VERSION "created by canmatrix"

NS_ :

BS_:

BU_:

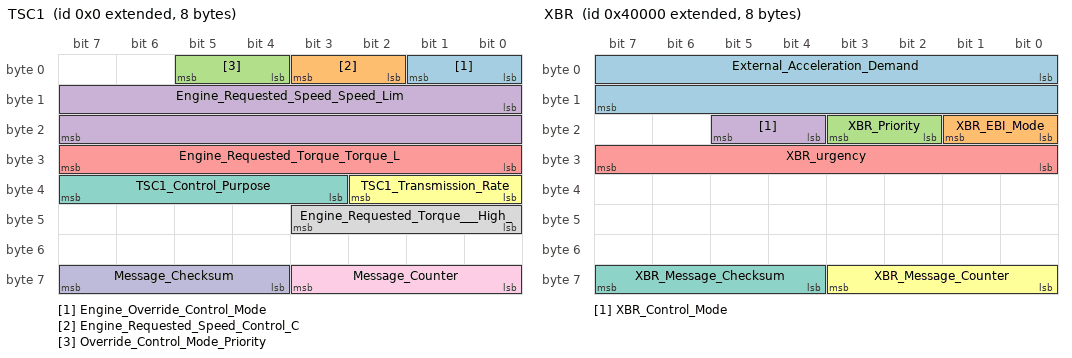
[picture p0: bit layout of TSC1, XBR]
BO_ 2147483648 TSC1: 8 Vector__XXX
 SG_ Engine_Override_Control_Mode : 0|2@1+ (1,0) [0|3] "" Vector__XXX
 SG_ Engine_Requested_Speed_Control_C : 2|2@1+ (1,0) [0|3] "" Vector__XXX
 SG_ Override_Control_Mode_Priority : 4|2@1+ (1,0) [0|3] "" Vector__XXX
 SG_ Engine_Requested_Speed_Speed_Lim : 8|16@1+ (1,0) [0|65535] "" Vector__XXX
 SG_ Engine_Requested_Torque_Torque_L : 24|8@1+ (1,0) [0|255] "" Vector__XXX
 SG_ TSC1_Transmission_Rate : 32|3@1+ (1,0) [0|7] "" Vector__XXX
 SG_ TSC1_Control_Purpose : 35|5@1+ (1,0) [0|31] "" Vector__XXX
 SG_ Engine_Requested_Torque___High_ : 40|4@1+ (1,0) [0|15] "" Vector__XXX
 SG_ Message_Counter : 56|4@1+ (1,0) [0|15] "" Vector__XXX
 SG_ Message_Checksum : 60|4@1+ (1,0) [0|15] "" Vector__XXX

BO_ 2147549184 TC1: 8 Vector__XXX
 SG_ Transmission_Gear_Shift_Inhibit_ : 0|2@1+ (1,0) [0|3] "" Vector__XXX
 SG_ Transmission_Torque_Converter_Lo : 2|2@1+ (1,0) [0|3] "" Vector__XXX
 SG_ Disengage_Driveline_Request : 4|2@1+ (1,0) [0|3] "" Vector__XXX
 SG_ Transmission_Reverse_Gear_Shift_ : 6|2@1+ (1,0) [0|3] "" Vector__XXX
 SG_ Requested_Percent_Clutch_Slip : 8|8@1+ (1,0) [0|255] "" Vector__XXX
 SG_ Transmission_Requested_Gear : 16|8@1+ (1,0) [0|255] "" Vector__XXX
 SG_ Disengage_Differential_Lock_Requ0 : 24|2@1+ (1,0) [0|3] "" Vector__XXX
 SG_ Disengage_Differential_Lock_Requ1 : 26|2@1+ (1,0) [0|3] "" Vector__XXX
 SG_ Disengage_Differential_Lock_Requ2 : 28|2@1+ (1,0) [0|3] "" Vector__XXX
 SG_ Disengage_Differential_Lock_Requ3 : 30|2@1+ (1,0) [0|3] "" Vector__XXX
 SG_ Disengage_Differential_Lock_Requ4 : 32|2@1+ (1,0) [0|3] "" Vector__XXX
 SG_ Disengage_Differential_Lock_Requ5 : 34|2@1+ (1,0) [0|3] "" Vector__XXX
 SG_ Disengage_Differential_Lock_Requ6 : 36|2@1+ (1,0) [0|3] "" Vector__XXX
 SG_ Transmission_Mode_1 : 40|2@1+ (1,0) [0|3] "" Vector__XXX
 SG_ Transmission_Mode_2 : 42|2@1+ (1,0) [0|3] "" Vector__XXX
 SG_ Transmission_Mode_3 : 44|2@1+ (1,0) [0|3] "" Vector__XXX
 SG_ Transmission_Mode_4 : 46|2@1+ (1,0) [0|3] "" Vector__XXX
 SG_ Transmission_Requested_Launch_Ge : 50|4@1+ (1,0) [0|15] "" Vector__XXX
 SG_ Transmission_Shift_Selector_Disp : 54|2@1+ (1,0) [0|3] "" Vector__XXX
 SG_ Transmission_Mode_5 : 56|2@1+ (1,0) [0|3] "" Vector__XXX
 SG_ Transmission_Mode_6 : 58|2@1+ (1,0) [0|3] "" Vector__XXX
 SG_ Transmission_Mode_7 : 60|2@1+ (1,0) [0|3] "" Vector__XXX
 SG_ Transmission_Mode_8 : 62|2@1+ (1,0) [0|3] "" Vector__XXX

BO_ 2147745792 XBR: 8 Vector__XXX
 SG_ External_Acceleration_Demand : 0|16@1+ (1,0) [0|65535] "" Vector__XXX
 SG_ XBR_EBI_Mode : 16|2@1+ (1,0) [0|3] "" Vector__XXX
 SG_ XBR_Priority : 18|2@1+ (1,0) [0|3] "" Vector__XXX
 SG_ XBR_Control_Mode : 20|2@1+ (1,0) [0|3] "" Vector__XXX
 SG_ XBR_urgency : 24|8@1+ (1,0) [0|255] "" Vector__XXX
 SG_ XBR_Message_Counter : 56|4@1+ (1,0) [0|15] "" Vector__XXX
 SG_ XBR_Message_Checksum : 60|4@1+ (1,0) [0|15] "" Vector__XXX

BO_ 2147942400 GPV4: 8 Vector__XXX
 SG_ Valve_Load_Sense_Pressure : 0|16@1+ (1,0) [0|65535] "" Vector__XXX
 SG_ Valve_Pilot_Pressure : 16|8@1+ (1,0) [0|255] "" Vector__XXX
 SG_ Valve_Assembly_Load_sense_Pressu : 24|16@1+ (1,0) [0|65535] "" Vector__XXX
 SG_ Valve_Assembly_Supply_Pressure : 40|16@1+ (1,0) [0|65535] "" Vector__XXX

BO_ 2148007936 AUXIO5: 8 Vector__XXX
 SG_ Auxiliary_I_O_Channel__6 : 0|16@1+ (1,0) [0|65535] "" Vector__XXX
 SG_ Auxiliary_I_O_Channel__5 : 16|16@1+ (1,0) [0|65535] "" Vector__XXX
 SG_ Auxiliary_I_O_Channel__4 : 32|16@1+ (1,0) [0|65535] "" Vector__XXX
 SG_ Auxiliary_I_O_Channel__3 : 48|16@1+ (1,0) [0|65535] "" Vector__XXX

BO_ 2157641728 PMI: 8 Vector__XXX
 SG_ Data_Dictionary_Manufacturer_Cod : 0|11@1+ (1,0) [0|2047] "" Vector__XXX
 SG_ Data_Dictionary_Method : 11|21@1+ (1,0) [0|2097151] "" Vector__XXX

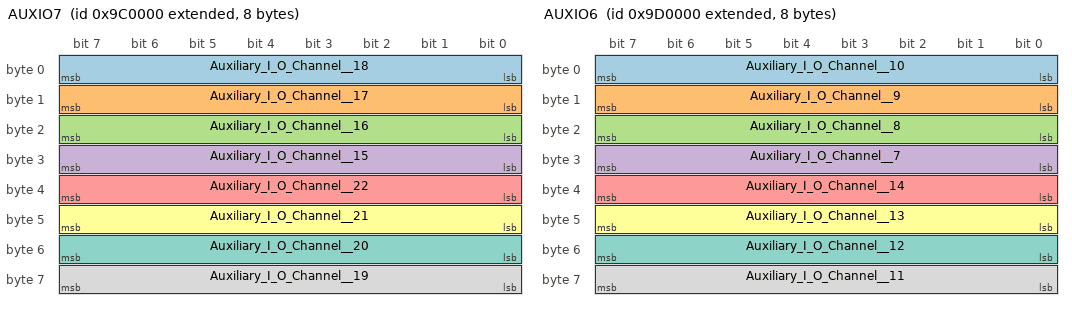
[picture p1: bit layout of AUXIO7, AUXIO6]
BO_ 2157707264 AUXIO7: 8 Vector__XXX
 SG_ Auxiliary_I_O_Channel__18 : 0|8@1+ (1,0) [0|255] "" Vector__XXX
 SG_ Auxiliary_I_O_Channel__17 : 8|8@1+ (1,0) [0|255] "" Vector__XXX
 SG_ Auxiliary_I_O_Channel__16 : 16|8@1+ (1,0) [0|255] "" Vector__XXX
 SG_ Auxiliary_I_O_Channel__15 : 24|8@1+ (1,0) [0|255] "" Vector__XXX
 SG_ Auxiliary_I_O_Channel__22 : 32|8@1+ (1,0) [0|255] "" Vector__XXX
 SG_ Auxiliary_I_O_Channel__21 : 40|8@1+ (1,0) [0|255] "" Vector__XXX
 SG_ Auxiliary_I_O_Channel__20 : 48|8@1+ (1,0) [0|255] "" Vector__XXX
 SG_ Auxiliary_I_O_Channel__19 : 56|8@1+ (1,0) [0|255] "" Vector__XXX

BO_ 2157772800 AUXIO6: 8 Vector__XXX
 SG_ Auxiliary_I_O_Channel__10 : 0|8@1+ (1,0) [0|255] "" Vector__XXX
 SG_ Auxiliary_I_O_Channel__9 : 8|8@1+ (1,0) [0|255] "" Vector__XXX
 SG_ Auxiliary_I_O_Channel__8 : 16|8@1+ (1,0) [0|255] "" Vector__XXX
 SG_ Auxiliary_I_O_Channel__7 : 24|8@1+ (1,0) [0|255] "" Vector__XXX
 SG_ Auxiliary_I_O_Channel__14 : 32|8@1+ (1,0) [0|255] "" Vector__XXX
 SG_ Auxiliary_I_O_Channel__13 : 40|8@1+ (1,0) [0|255] "" Vector__XXX
 SG_ Auxiliary_I_O_Channel__12 : 48|8@1+ (1,0) [0|255] "" Vector__XXX
 SG_ Auxiliary_I_O_Channel__11 : 56|8@1+ (1,0) [0|255] "" Vector__XXX

BO_ 2158297088 AUXIO4: 8 Vector__XXX
 SG_ Auxiliary_I_O__84 : 0|2@1+ (1,0) [0|3] "" Vector__XXX
 SG_ Auxiliary_I_O__83 : 2|2@1+ (1,0) [0|3] "" Vector__XXX
 SG_ Auxiliary_I_O__82 : 4|2@1+ (1,0) [0|3] "" Vector__XXX
 SG_ Auxiliary_I_O__81 : 6|2@1+ (1,0) [0|3] "" Vector__XXX
 SG_ Auxiliary_I_O__88 : 8|2@1+ (1,0) [0|3] "" Vector__XXX
 SG_ Auxiliary_I_O__87 : 10|2@1+ (1,0) [0|3] "" Vector__XXX
 SG_ Auxiliary_I_O__86 : 12|2@1+ (1,0) [0|3] "" Vector__XXX
 SG_ Auxiliary_I_O__85 : 14|2@1+ (1,0) [0|3] "" Vector__XXX
 SG_ Auxiliary_I_O__92 : 16|2@1+ (1,0) [0|3] "" Vector__XXX
 SG_ Auxiliary_I_O__91 : 18|2@1+ (1,0) [0|3] "" Vector__XXX
 SG_ Auxiliary_I_O__90 : 20|2@1+ (1,0) [0|3] "" Vector__XXX
 SG_ Auxiliary_I_O__89 : 22|2@1+ (1,0) [0|3] "" Vector__XXX
 SG_ Auxiliary_I_O__96 : 24|2@1+ (1,0) [0|3] "" Vector__XXX
 SG_ Auxiliary_I_O__95 : 26|2@1+ (1,0) [0|3] "" Vector__XXX
 SG_ Auxiliary_I_O__94 : 28|2@1+ (1,0) [0|3] "" Vector__XXX
 SG_ Auxiliary_I_O__93 : 30|2@1+ (1,0) [0|3] "" Vector__XXX
 SG_ Auxiliary_I_O__100 : 32|2@1+ (1,0) [0|3] "" Vector__XXX
 SG_ Auxiliary_I_O__99 : 34|2@1+ (1,0) [0|3] "" Vector__XXX
 SG_ Auxiliary_I_O__98 : 36|2@1+ (1,0) [0|3] "" Vector__XXX
 SG_ Auxiliary_I_O__97 : 38|2@1+ (1,0) [0|3] "" Vector__XXX
 SG_ Auxiliary_I_O__104 : 40|2@1+ (1,0) [0|3] "" Vector__XXX
 SG_ Auxiliary_I_O__103 : 42|2@1+ (1,0) [0|3] "" Vector__XXX
 SG_ Auxiliary_I_O__102 : 44|2@1+ (1,0) [0|3] "" Vector__XXX
 SG_ Auxiliary_I_O__101 : 46|2@1+ (1,0) [0|3] "" Vector__XXX
 SG_ Auxiliary_I_O__108 : 48|2@1+ (1,0) [0|3] "" Vector__XXX
 SG_ Auxiliary_I_O__107 : 50|2@1+ (1,0) [0|3] "" Vector__XXX
 SG_ Auxiliary_I_O__106 : 52|2@1+ (1,0) [0|3] "" Vector__XXX
 SG_ Auxiliary_I_O__105 : 54|2@1+ (1,0) [0|3] "" Vector__XXX
 SG_ Auxiliary_I_O__112 : 56|2@1+ (1,0) [0|3] "" Vector__XXX
 SG_ Auxiliary_I_O__111 : 58|2@1+ (1,0) [0|3] "" Vector__XXX
 SG_ Auxiliary_I_O__110 : 60|2@1+ (1,0) [0|3] "" Vector__XXX
 SG_ Auxiliary_I_O__109 : 62|2@1+ (1,0) [0|3] "" Vector__XXX

BO_ 2158362624 AUXIO3: 8 Vector__XXX
 SG_ Auxiliary_I_O__52 : 0|2@1+ (1,0) [0|3] "" Vector__XXX
 SG_ Auxiliary_I_O__51 : 2|2@1+ (1,0) [0|3] "" Vector__XXX
 SG_ Auxiliary_I_O__50 : 4|2@1+ (1,0) [0|3] "" Vector__XXX
 SG_ Auxiliary_I_O__49 : 6|2@1+ (1,0) [0|3] "" Vector__XXX
 SG_ Auxiliary_I_O__56 : 8|2@1+ (1,0) [0|3] "" Vector__XXX
 SG_ Auxiliary_I_O__55 : 10|2@1+ (1,0) [0|3] "" Vector__XXX
 SG_ Auxiliary_I_O__54 : 12|2@1+ (1,0) [0|3] "" Vector__XXX
 SG_ Auxiliary_I_O__53 : 14|2@1+ (1,0) [0|3] "" Vector__XXX
 SG_ Auxiliary_I_O__60 : 16|2@1+ (1,0) [0|3] "" Vector__XXX
 SG_ Auxiliary_I_O__59 : 18|2@1+ (1,0) [0|3] "" Vector__XXX
 SG_ Auxiliary_I_O__58 : 20|2@1+ (1,0) [0|3] "" Vector__XXX
 SG_ Auxiliary_I_O__57 : 22|2@1+ (1,0) [0|3] "" Vector__XXX
 SG_ Auxiliary_I_O__64 : 24|2@1+ (1,0) [0|3] "" Vector__XXX
 SG_ Auxiliary_I_O__63 : 26|2@1+ (1,0) [0|3] "" Vector__XXX
 SG_ Auxiliary_I_O__62 : 28|2@1+ (1,0) [0|3] "" Vector__XXX
 SG_ Auxiliary_I_O__61 : 30|2@1+ (1,0) [0|3] "" Vector__XXX
 SG_ Auxiliary_I_O__68 : 32|2@1+ (1,0) [0|3] "" Vector__XXX
 SG_ Auxiliary_I_O__67 : 34|2@1+ (1,0) [0|3] "" Vector__XXX
 SG_ Auxiliary_I_O__66 : 36|2@1+ (1,0) [0|3] "" Vector__XXX
 SG_ Auxiliary_I_O__65 : 38|2@1+ (1,0) [0|3] "" Vector__XXX
 SG_ Auxiliary_I_O__72 : 40|2@1+ (1,0) [0|3] "" Vector__XXX
 SG_ Auxiliary_I_O__71 : 42|2@1+ (1,0) [0|3] "" Vector__XXX
 SG_ Auxiliary_I_O__70 : 44|2@1+ (1,0) [0|3] "" Vector__XXX
 SG_ Auxiliary_I_O__69 : 46|2@1+ (1,0) [0|3] "" Vector__XXX
 SG_ Auxiliary_I_O__76 : 48|2@1+ (1,0) [0|3] "" Vector__XXX
 SG_ Auxiliary_I_O__75 : 50|2@1+ (1,0) [0|3] "" Vector__XXX
 SG_ Auxiliary_I_O__74 : 52|2@1+ (1,0) [0|3] "" Vector__XXX
 SG_ Auxiliary_I_O__73 : 54|2@1+ (1,0) [0|3] "" Vector__XXX
 SG_ Auxiliary_I_O__80 : 56|2@1+ (1,0) [0|3] "" Vector__XXX
 SG_ Auxiliary_I_O__79 : 58|2@1+ (1,0) [0|3] "" Vector__XXX
 SG_ Auxiliary_I_O__78 : 60|2@1+ (1,0) [0|3] "" Vector__XXX
 SG_ Auxiliary_I_O__77 : 62|2@1+ (1,0) [0|3] "" Vector__XXX

BO_ 2158428160 AUXIO2: 8 Vector__XXX
 SG_ Auxiliary_I_O__20 : 0|2@1+ (1,0) [0|3] "" Vector__XXX
 SG_ Auxiliary_I_O__19 : 2|2@1+ (1,0) [0|3] "" Vector__XXX
 SG_ Auxiliary_I_O__18 : 4|2@1+ (1,0) [0|3] "" Vector__XXX
 SG_ Auxiliary_I_O__17 : 6|2@1+ (1,0) [0|3] "" Vector__XXX
 SG_ Auxiliary_I_O__24 : 8|2@1+ (1,0) [0|3] "" Vector__XXX
 SG_ Auxiliary_I_O__23 : 10|2@1+ (1,0) [0|3] "" Vector__XXX
 SG_ Auxiliary_I_O__22 : 12|2@1+ (1,0) [0|3] "" Vector__XXX
 SG_ Auxiliary_I_O__21 : 14|2@1+ (1,0) [0|3] "" Vector__XXX
 SG_ Auxiliary_I_O__28 : 16|2@1+ (1,0) [0|3] "" Vector__XXX
 SG_ Auxiliary_I_O__27 : 18|2@1+ (1,0) [0|3] "" Vector__XXX
 SG_ Auxiliary_I_O__26 : 20|2@1+ (1,0) [0|3] "" Vector__XXX
 SG_ Auxiliary_I_O__25 : 22|2@1+ (1,0) [0|3] "" Vector__XXX
 SG_ Auxiliary_I_O__32 : 24|2@1+ (1,0) [0|3] "" Vector__XXX
 SG_ Auxiliary_I_O__31 : 26|2@1+ (1,0) [0|3] "" Vector__XXX
 SG_ Auxiliary_I_O__30 : 28|2@1+ (1,0) [0|3] "" Vector__XXX
 SG_ Auxiliary_I_O__29 : 30|2@1+ (1,0) [0|3] "" Vector__XXX
 SG_ Auxiliary_I_O__36 : 32|2@1+ (1,0) [0|3] "" Vector__XXX
 SG_ Auxiliary_I_O__35 : 34|2@1+ (1,0) [0|3] "" Vector__XXX
 SG_ Auxiliary_I_O__34 : 36|2@1+ (1,0) [0|3] "" Vector__XXX
 SG_ Auxiliary_I_O__33 : 38|2@1+ (1,0) [0|3] "" Vector__XXX
 SG_ Auxiliary_I_O__40 : 40|2@1+ (1,0) [0|3] "" Vector__XXX
 SG_ Auxiliary_I_O__39 : 42|2@1+ (1,0) [0|3] "" Vector__XXX
 SG_ Auxiliary_I_O__38 : 44|2@1+ (1,0) [0|3] "" Vector__XXX
 SG_ Auxiliary_I_O__37 : 46|2@1+ (1,0) [0|3] "" Vector__XXX
 SG_ Auxiliary_I_O__44 : 48|2@1+ (1,0) [0|3] "" Vector__XXX
 SG_ Auxiliary_I_O__43 : 50|2@1+ (1,0) [0|3] "" Vector__XXX
 SG_ Auxiliary_I_O__42 : 52|2@1+ (1,0) [0|3] "" Vector__XXX
 SG_ Auxiliary_I_O__41 : 54|2@1+ (1,0) [0|3] "" Vector__XXX
 SG_ Auxiliary_I_O__48 : 56|2@1+ (1,0) [0|3] "" Vector__XXX
 SG_ Auxiliary_I_O__47 : 58|2@1+ (1,0) [0|3] "" Vector__XXX
 SG_ Auxiliary_I_O__46 : 60|2@1+ (1,0) [0|3] "" Vector__XXX
 SG_ Auxiliary_I_O__45 : 62|2@1+ (1,0) [0|3] "" Vector__XXX

BO_ 2158493696 DISP1: 8 Vector__XXX
 SG_ Text_Display_Instructions : 0|4@1+ (1,0) [0|15] "" Vector__XXX
 SG_ Text_Display_Index : 16|8@1+ (1,0) [0|255] "" Vector__XXX
 SG_ Text_Display_Character : 24|1600@1+ (1,0) [0|4.446241647709404462001681407E+481] "" Vector__XXX

BO_ 2158559232 FLIC: 8 Vector__XXX
 SG_ Lane_Departure_Warning_Enable_Co : 0|2@1+ (1,0) [0|3] "" Vector__XXX

BO_ 2158886912 TPRS: 8 Vector__XXX
 SG_ Tire_Location : 0|8@1+ (1,0) [0|255] "" Vector__XXX
 SG_ Reference_Tire_Pressure_Setting : 8|8@1+ (1,0) [0|255] "" Vector__XXX

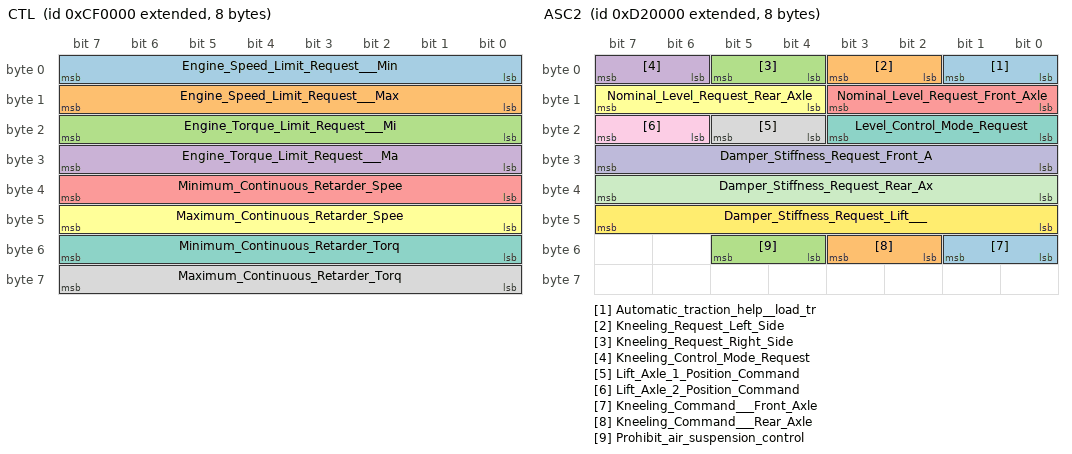
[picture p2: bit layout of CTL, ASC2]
BO_ 2161049600 CTL: 8 Vector__XXX
 SG_ Engine_Speed_Limit_Request___Min : 0|8@1+ (1,0) [0|255] "" Vector__XXX
 SG_ Engine_Speed_Limit_Request___Max : 8|8@1+ (1,0) [0|255] "" Vector__XXX
 SG_ Engine_Torque_Limit_Request___Mi : 16|8@1+ (1,0) [0|255] "" Vector__XXX
 SG_ Engine_Torque_Limit_Request___Ma : 24|8@1+ (1,0) [0|255] "" Vector__XXX
 SG_ Minimum_Continuous_Retarder_Spee : 32|8@1+ (1,0) [0|255] "" Vector__XXX
 SG_ Maximum_Continuous_Retarder_Spee : 40|8@1+ (1,0) [0|255] "" Vector__XXX
 SG_ Minimum_Continuous_Retarder_Torq : 48|8@1+ (1,0) [0|255] "" Vector__XXX
 SG_ Maximum_Continuous_Retarder_Torq : 56|8@1+ (1,0) [0|255] "" Vector__XXX

BO_ 2161115136 CL: 8 Vector__XXX
 SG_ Illumination_Brightness_Percent : 0|8@1+ (1,0) [0|255] "" Vector__XXX

BO_ 2161180672 ASC6: 8 Vector__XXX
 SG_ Level_Preset_Front_Axle_Left : 0|16@1+ (1,0) [0|65535] "" Vector__XXX
 SG_ Level_Preset_Front_Axle_Right : 16|16@1+ (1,0) [0|65535] "" Vector__XXX
 SG_ Level_Preset_Rear_Axle_Left : 32|16@1+ (1,0) [0|65535] "" Vector__XXX
 SG_ Level_Preset_Rear_Axle_Right : 48|16@1+ (1,0) [0|65535] "" Vector__XXX

BO_ 2161246208 ASC2: 8 Vector__XXX
 SG_ Automatic_traction_help__load_tr : 0|2@1+ (1,0) [0|3] "" Vector__XXX
 SG_ Kneeling_Request_Left_Side : 2|2@1+ (1,0) [0|3] "" Vector__XXX
 SG_ Kneeling_Request_Right_Side : 4|2@1+ (1,0) [0|3] "" Vector__XXX
 SG_ Kneeling_Control_Mode_Request : 6|2@1+ (1,0) [0|3] "" Vector__XXX
 SG_ Nominal_Level_Request_Front_Axle : 8|4@1+ (1,0) [0|15] "" Vector__XXX
 SG_ Nominal_Level_Request_Rear_Axle : 12|4@1+ (1,0) [0|15] "" Vector__XXX
 SG_ Level_Control_Mode_Request : 16|4@1+ (1,0) [0|15] "" Vector__XXX
 SG_ Lift_Axle_1_Position_Command : 20|2@1+ (1,0) [0|3] "" Vector__XXX
 SG_ Lift_Axle_2_Position_Command : 22|2@1+ (1,0) [0|3] "" Vector__XXX
 SG_ Damper_Stiffness_Request_Front_A : 24|8@1+ (1,0) [0|255] "" Vector__XXX
 SG_ Damper_Stiffness_Request_Rear_Ax : 32|8@1+ (1,0) [0|255] "" Vector__XXX
 SG_ Damper_Stiffness_Request_Lift___ : 40|8@1+ (1,0) [0|255] "" Vector__XXX
 SG_ Kneeling_Command___Front_Axle : 48|2@1+ (1,0) [0|3] "" Vector__XXX
 SG_ Kneeling_Command___Rear_Axle : 50|2@1+ (1,0) [0|3] "" Vector__XXX
 SG_ Prohibit_air_suspension_control : 52|2@1+ (1,0) [0|3] "" Vector__XXX

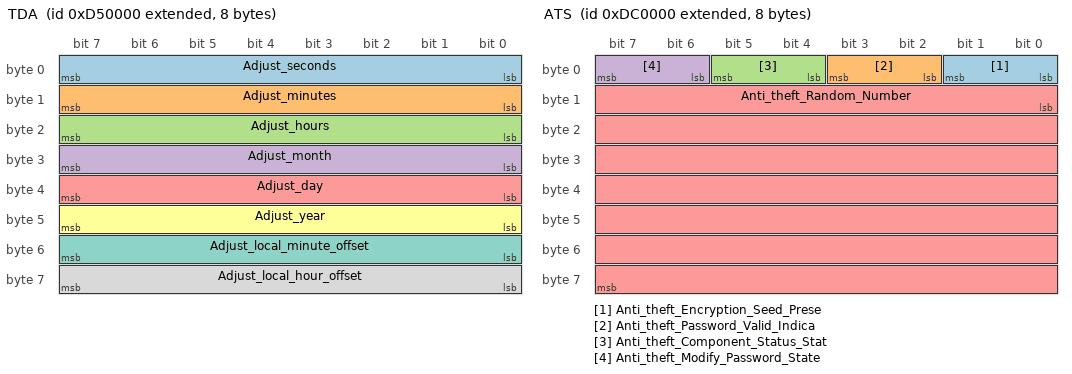
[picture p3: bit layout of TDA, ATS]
BO_ 2161442816 TDA: 8 Vector__XXX
 SG_ Adjust_seconds : 0|8@1+ (1,0) [0|255] "" Vector__XXX
 SG_ Adjust_minutes : 8|8@1+ (1,0) [0|255] "" Vector__XXX
 SG_ Adjust_hours : 16|8@1+ (1,0) [0|255] "" Vector__XXX
 SG_ Adjust_month : 24|8@1+ (1,0) [0|255] "" Vector__XXX
 SG_ Adjust_day : 32|8@1+ (1,0) [0|255] "" Vector__XXX
 SG_ Adjust_year : 40|8@1+ (1,0) [0|255] "" Vector__XXX
 SG_ Adjust_local_minute_offset : 48|8@1+ (1,0) [0|255] "" Vector__XXX
 SG_ Adjust_local_hour_offset : 56|8@1+ (1,0) [0|255] "" Vector__XXX

BO_ 2161901568 ATS: 8 Vector__XXX
 SG_ Anti_theft_Encryption_Seed_Prese : 0|2@1+ (1,0) [0|3] "" Vector__XXX
 SG_ Anti_theft_Password_Valid_Indica : 2|2@1+ (1,0) [0|3] "" Vector__XXX
 SG_ Anti_theft_Component_Status_Stat : 4|2@1+ (1,0) [0|3] "" Vector__XXX
 SG_ Anti_theft_Modify_Password_State : 6|2@1+ (1,0) [0|3] "" Vector__XXX
 SG_ Anti_theft_Random_Number : 8|56@1+ (1,0) [0|72057594037927935] "" Vector__XXX

BO_ 2161967104 ATR: 8 Vector__XXX
 SG_ Anti_theft_Encryption_Indicator_ : 1|2@1+ (1,0) [0|3] "" Vector__XXX
 SG_ Anti_theft_Desired_Exit_Mode_Sta : 3|2@1+ (1,0) [0|3] "" Vector__XXX
 SG_ Anti_theft_Command_States : 5|3@1+ (1,0) [0|7] "" Vector__XXX
 SG_ Anti_theft_Password_Representati : 8|56@1+ (1,0) [0|72057594037927935] "" Vector__XXX

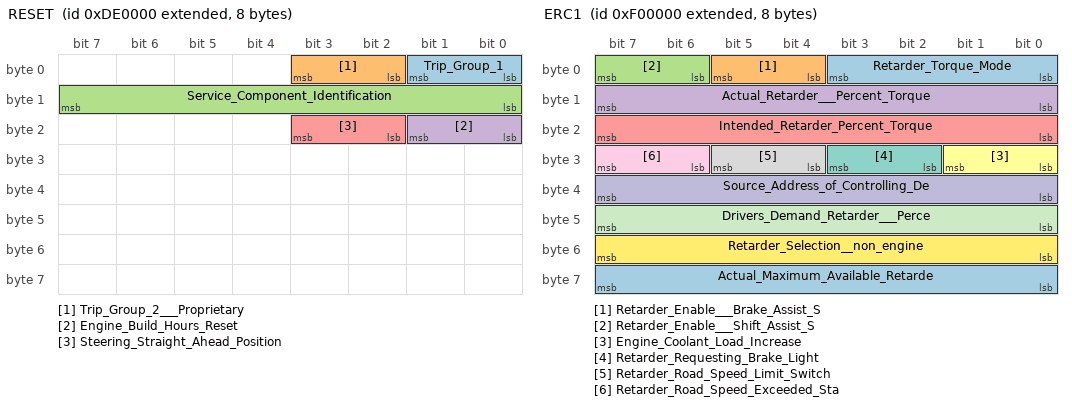
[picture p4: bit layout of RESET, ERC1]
BO_ 2162032640 RESET: 8 Vector__XXX
 SG_ Trip_Group_1 : 0|2@1+ (1,0) [0|3] "" Vector__XXX
 SG_ Trip_Group_2___Proprietary : 2|2@1+ (1,0) [0|3] "" Vector__XXX
 SG_ Service_Component_Identification : 8|8@1+ (1,0) [0|255] "" Vector__XXX
 SG_ Engine_Build_Hours_Reset : 16|2@1+ (1,0) [0|3] "" Vector__XXX
 SG_ Steering_Straight_Ahead_Position : 18|2@1+ (1,0) [0|3] "" Vector__XXX

BO_ 2162163712 CM1: 8 Vector__XXX
 SG_ Requested_Percent_Fan_Speed : 0|8@1+ (1,0) [0|255] "" Vector__XXX
 SG_ Cab_Interior_Temperature_Command : 8|16@1+ (1,0) [0|65535] "" Vector__XXX
 SG_ Auxiliary_Heater_Coolant_Pump_Re : 24|2@1+ (1,0) [0|3] "" Vector__XXX
 SG_ Battery_Main_Switch_Hold_Request : 26|2@1+ (1,0) [0|3] "" Vector__XXX
 SG_ Operator_Seat_Direction_Switch : 28|2@1+ (1,0) [0|3] "" Vector__XXX
 SG_ Seat_Belt_Switch : 30|2@1+ (1,0) [0|3] "" Vector__XXX
 SG_ Vehicle_Limiting_Speed_Governor_0 : 34|2@1+ (1,0) [0|3] "" Vector__XXX
 SG_ Vehicle_Limiting_Speed_Governor_1 : 36|2@1+ (1,0) [0|3] "" Vector__XXX
 SG_ Vehicle_Limiting_Speed_Governor_2 : 38|2@1+ (1,0) [0|3] "" Vector__XXX
 SG_ Diesel_Particulate_Filter_Regene0 : 40|2@1+ (1,0) [0|3] "" Vector__XXX
 SG_ Diesel_Particulate_Filter_Regene1 : 42|2@1+ (1,0) [0|3] "" Vector__XXX
 SG_ Automatic_Gear_Shifting_Enable_S : 44|2@1+ (1,0) [0|3] "" Vector__XXX
 SG_ Engine_Automatic_Start_Enable_Sw : 46|2@1+ (1,0) [0|3] "" Vector__XXX
 SG_ Auxiliary_Heater_Mode_Request : 48|4@1+ (1,0) [0|15] "" Vector__XXX
 SG_ Request_Engine_Zone_Heating : 52|2@1+ (1,0) [0|3] "" Vector__XXX
 SG_ Request_Cab_Zone_Heating : 54|2@1+ (1,0) [0|3] "" Vector__XXX
 SG_ Selected_Maximum_Vehicle_Speed_L : 56|8@1+ (1,0) [0|255] "" Vector__XXX

BO_ 2163212288 ERC1: 8 Vector__XXX
 SG_ Retarder_Torque_Mode : 0|4@1+ (1,0) [0|15] "" Vector__XXX
 SG_ Retarder_Enable___Brake_Assist_S : 4|2@1+ (1,0) [0|3] "" Vector__XXX
 SG_ Retarder_Enable___Shift_Assist_S : 6|2@1+ (1,0) [0|3] "" Vector__XXX
 SG_ Actual_Retarder___Percent_Torque : 8|8@1+ (1,0) [0|255] "" Vector__XXX
 SG_ Intended_Retarder_Percent_Torque : 16|8@1+ (1,0) [0|255] "" Vector__XXX
 SG_ Engine_Coolant_Load_Increase : 24|2@1+ (1,0) [0|3] "" Vector__XXX
 SG_ Retarder_Requesting_Brake_Light : 26|2@1+ (1,0) [0|3] "" Vector__XXX
 SG_ Retarder_Road_Speed_Limit_Switch : 28|2@1+ (1,0) [0|3] "" Vector__XXX
 SG_ Retarder_Road_Speed_Exceeded_Sta : 30|2@1+ (1,0) [0|3] "" Vector__XXX
 SG_ Source_Address_of_Controlling_De : 32|8@1+ (1,0) [0|255] "" Vector__XXX
 SG_ Drivers_Demand_Retarder___Perce : 40|8@1+ (1,0) [0|255] "" Vector__XXX
 SG_ Retarder_Selection__non_engine : 48|8@1+ (1,0) [0|255] "" Vector__XXX
 SG_ Actual_Maximum_Available_Retarde : 56|8@1+ (1,0) [0|255] "" Vector__XXX

BO_ 2163212544 EBC1: 8 Vector__XXX
 SG_ ASR_Engine_Control_Active : 0|2@1+ (1,0) [0|3] "" Vector__XXX
 SG_ ASR_Brake_Control_Active : 2|2@1+ (1,0) [0|3] "" Vector__XXX
 SG_ Anti_Lock_Braking__ABS__Active : 4|2@1+ (1,0) [0|3] "" Vector__XXX
 SG_ EBS_Brake_Switch : 6|2@1+ (1,0) [0|3] "" Vector__XXX
 SG_ Brake_Pedal_Position : 8|8@1+ (1,0) [0|255] "" Vector__XXX
 SG_ ABS_Off_road_Switch : 16|2@1+ (1,0) [0|3] "" Vector__XXX
 SG_ ASR_Off_road_Switch : 18|2@1+ (1,0) [0|3] "" Vector__XXX
 SG_ ASR__Hill_Holder__Switch : 20|2@1+ (1,0) [0|3] "" Vector__XXX
 SG_ Traction_Control_Override_Switch : 22|2@1+ (1,0) [0|3] "" Vector__XXX
 SG_ Accelerator_Interlock_Switch : 24|2@1+ (1,0) [0|3] "" Vector__XXX
 SG_ Engine_Derate_Switch : 26|2@1+ (1,0) [0|3] "" Vector__XXX
 SG_ Engine_Auxiliary_Shutdown_Switch : 28|2@1+ (1,0) [0|3] "" Vector__XXX
 SG_ Remote_Accelerator_Enable_Switch : 30|2@1+ (1,0) [0|3] "" Vector__XXX
 SG_ Engine_Retarder_Selection : 32|8@1+ (1,0) [0|255] "" Vector__XXX
 SG_ ABS_Fully_Operational : 40|2@1+ (1,0) [0|3] "" Vector__XXX
 SG_ EBS_Red_Warning_Signal : 42|2@1+ (1,0) [0|3] "" Vector__XXX
 SG_ ABS_EBS_Amber_Warning_Signal__Po : 44|2@1+ (1,0) [0|3] "" Vector__XXX
 SG_ ATC_ASR_Information_Signal : 46|2@1+ (1,0) [0|3] "" Vector__XXX
 SG_ Source_Address_of_Controlling_De : 48|8@1+ (1,0) [0|255] "" Vector__XXX
 SG_ Halt_brake_switch : 58|2@1+ (1,0) [0|3] "" Vector__XXX
 SG_ Trailer_ABS_Status : 60|2@1+ (1,0) [0|3] "" Vector__XXX
 SG_ Tractor_Mounted_Trailer_ABS_Warn : 62|2@1+ (1,0) [0|3] "" Vector__XXX

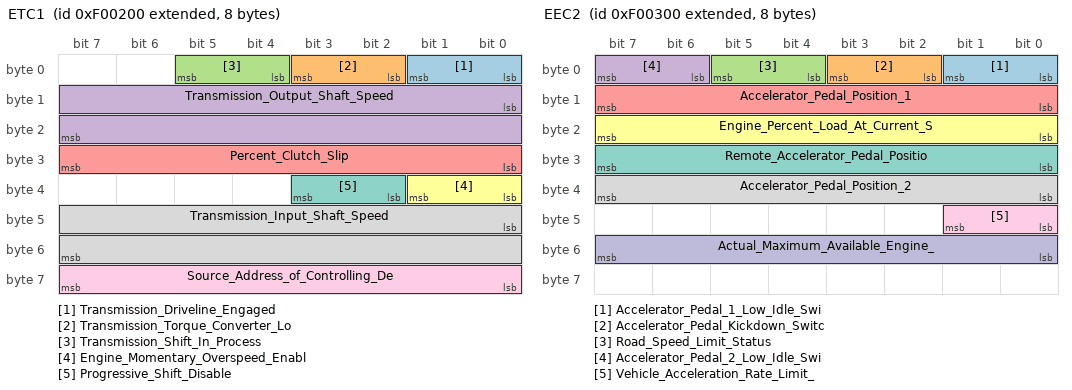
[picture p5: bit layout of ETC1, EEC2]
BO_ 2163212800 ETC1: 8 Vector__XXX
 SG_ Transmission_Driveline_Engaged : 0|2@1+ (1,0) [0|3] "" Vector__XXX
 SG_ Transmission_Torque_Converter_Lo : 2|2@1+ (1,0) [0|3] "" Vector__XXX
 SG_ Transmission_Shift_In_Process : 4|2@1+ (1,0) [0|3] "" Vector__XXX
 SG_ Transmission_Output_Shaft_Speed : 8|16@1+ (1,0) [0|65535] "" Vector__XXX
 SG_ Percent_Clutch_Slip : 24|8@1+ (1,0) [0|255] "" Vector__XXX
 SG_ Engine_Momentary_Overspeed_Enabl : 32|2@1+ (1,0) [0|3] "" Vector__XXX
 SG_ Progressive_Shift_Disable : 34|2@1+ (1,0) [0|3] "" Vector__XXX
 SG_ Transmission_Input_Shaft_Speed : 40|16@1+ (1,0) [0|65535] "" Vector__XXX
 SG_ Source_Address_of_Controlling_De : 56|8@1+ (1,0) [0|255] "" Vector__XXX

BO_ 2163213056 EEC2: 8 Vector__XXX
 SG_ Accelerator_Pedal_1_Low_Idle_Swi : 0|2@1+ (1,0) [0|3] "" Vector__XXX
 SG_ Accelerator_Pedal_Kickdown_Switc : 2|2@1+ (1,0) [0|3] "" Vector__XXX
 SG_ Road_Speed_Limit_Status : 4|2@1+ (1,0) [0|3] "" Vector__XXX
 SG_ Accelerator_Pedal_2_Low_Idle_Swi : 6|2@1+ (1,0) [0|3] "" Vector__XXX
 SG_ Accelerator_Pedal_Position_1 : 8|8@1+ (1,0) [0|255] "" Vector__XXX
 SG_ Engine_Percent_Load_At_Current_S : 16|8@1+ (1,0) [0|255] "" Vector__XXX
 SG_ Remote_Accelerator_Pedal_Positio : 24|8@1+ (1,0) [0|255] "" Vector__XXX
 SG_ Accelerator_Pedal_Position_2 : 32|8@1+ (1,0) [0|255] "" Vector__XXX
 SG_ Vehicle_Acceleration_Rate_Limit_ : 40|2@1+ (1,0) [0|3] "" Vector__XXX
 SG_ Actual_Maximum_Available_Engine_ : 48|8@1+ (1,0) [0|255] "" Vector__XXX

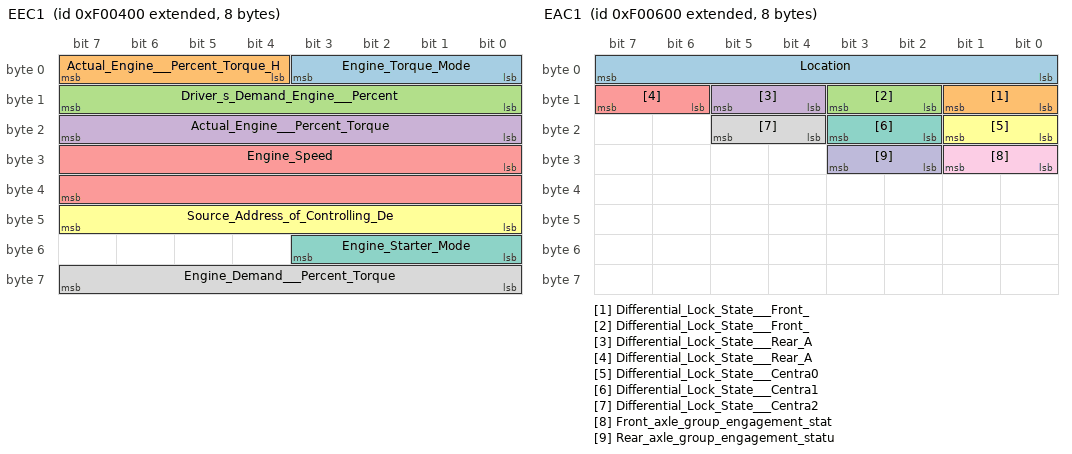
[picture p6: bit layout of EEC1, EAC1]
BO_ 2163213312 EEC1: 8 Vector__XXX
 SG_ Engine_Torque_Mode : 0|4@1+ (1,0) [0|15] "" Vector__XXX
 SG_ Actual_Engine___Percent_Torque_H : 4|4@1+ (1,0) [0|15] "" Vector__XXX
 SG_ Driver_s_Demand_Engine___Percent : 8|8@1+ (1,0) [0|255] "" Vector__XXX
 SG_ Actual_Engine___Percent_Torque : 16|8@1+ (1,0) [0|255] "" Vector__XXX
 SG_ Engine_Speed : 24|16@1+ (1,0) [0|65535] "" Vector__XXX
 SG_ Source_Address_of_Controlling_De : 40|8@1+ (1,0) [0|255] "" Vector__XXX
 SG_ Engine_Starter_Mode : 48|4@1+ (1,0) [0|15] "" Vector__XXX
 SG_ Engine_Demand___Percent_Torque : 56|8@1+ (1,0) [0|255] "" Vector__XXX

BO_ 2163213568 ETC2: 8 Vector__XXX
 SG_ Transmission_Selected_Gear : 0|8@1+ (1,0) [0|255] "" Vector__XXX
 SG_ Transmission_Actual_Gear_Ratio : 8|16@1+ (1,0) [0|65535] "" Vector__XXX
 SG_ Transmission_Current_Gear : 24|8@1+ (1,0) [0|255] "" Vector__XXX
 SG_ Transmission_Requested_Range : 32|16@1+ (1,0) [0|65535] "" Vector__XXX
 SG_ Transmission_Current_Range : 48|16@1+ (1,0) [0|65535] "" Vector__XXX

BO_ 2163213824 EAC1: 8 Vector__XXX
 SG_ Location : 0|8@1+ (1,0) [0|255] "" Vector__XXX
 SG_ Differential_Lock_State___Front_ : 8|2@1+ (1,0) [0|3] "" Vector__XXX
 SG_ Differential_Lock_State___Front_ : 10|2@1+ (1,0) [0|3] "" Vector__XXX
 SG_ Differential_Lock_State___Rear_A : 12|2@1+ (1,0) [0|3] "" Vector__XXX
 SG_ Differential_Lock_State___Rear_A : 14|2@1+ (1,0) [0|3] "" Vector__XXX
 SG_ Differential_Lock_State___Centra0 : 16|2@1+ (1,0) [0|3] "" Vector__XXX
 SG_ Differential_Lock_State___Centra1 : 18|2@1+ (1,0) [0|3] "" Vector__XXX
 SG_ Differential_Lock_State___Centra2 : 20|2@1+ (1,0) [0|3] "" Vector__XXX
 SG_ Front_axle_group_engagement_stat : 24|2@1+ (1,0) [0|3] "" Vector__XXX
 SG_ Rear_axle_group_engagement_statu : 26|2@1+ (1,0) [0|3] "" Vector__XXX

BO_ 2163214080 FLI1: 8 Vector__XXX
 SG_ Lane_Departure_Left : 0|2@1+ (1,0) [0|3] "" Vector__XXX
 SG_ Lane_Departure_Right : 2|2@1+ (1,0) [0|3] "" Vector__XXX
 SG_ Lane_Departure_Imminent__Right_S : 4|2@1+ (1,0) [0|3] "" Vector__XXX
 SG_ Lane_Departure_Imminent__Left_Si : 6|2@1+ (1,0) [0|3] "" Vector__XXX

BO_ 2163214336 HPG: 8 Vector__XXX
 SG_ Hydraulic_Pressure : 0|16@1+ (1,0) [0|65535] "" Vector__XXX
 SG_ Engine_Hydraulic_Pressure_Govern0 : 16|2@1+ (1,0) [0|3] "" Vector__XXX
 SG_ Engine_Hydraulic_Pressure_Govern1 : 18|2@1+ (1,0) [0|3] "" Vector__XXX
 SG_ Fire_Apparatus_Pump_Engagement : 20|2@1+ (1,0) [0|3] "" Vector__XXX

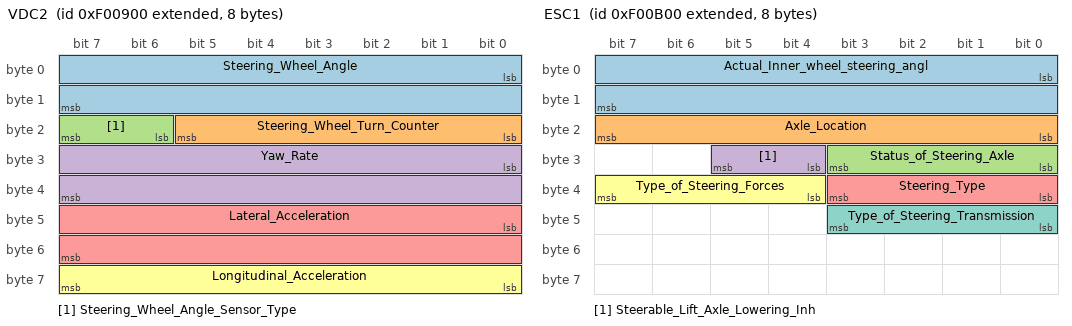
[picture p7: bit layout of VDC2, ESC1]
BO_ 2163214592 VDC2: 8 Vector__XXX
 SG_ Steering_Wheel_Angle : 0|16@1+ (1,0) [0|65535] "" Vector__XXX
 SG_ Steering_Wheel_Turn_Counter : 16|6@1+ (1,0) [0|63] "" Vector__XXX
 SG_ Steering_Wheel_Angle_Sensor_Type : 22|2@1+ (1,0) [0|3] "" Vector__XXX
 SG_ Yaw_Rate : 24|16@1+ (1,0) [0|65535] "" Vector__XXX
 SG_ Lateral_Acceleration : 40|16@1+ (1,0) [0|65535] "" Vector__XXX
 SG_ Longitudinal_Acceleration : 56|8@1+ (1,0) [0|255] "" Vector__XXX

BO_ 2163214848 EGF1: 8 Vector__XXX
 SG_ Engine_Exhaust_Gas_Recirculation : 0|16@1+ (1,0) [0|65535] "" Vector__XXX
 SG_ Engine_Inlet_Air_Mass_Flow_Rate : 16|16@1+ (1,0) [0|65535] "" Vector__XXX

BO_ 2163215104 ESC1: 8 Vector__XXX
 SG_ Actual_Inner_wheel_steering_angl : 0|16@1+ (1,0) [0|65535] "" Vector__XXX
 SG_ Axle_Location : 16|8@1+ (1,0) [0|255] "" Vector__XXX
 SG_ Status_of_Steering_Axle : 24|4@1+ (1,0) [0|15] "" Vector__XXX
 SG_ Steerable_Lift_Axle_Lowering_Inh : 28|2@1+ (1,0) [0|3] "" Vector__XXX
 SG_ Steering_Type : 32|4@1+ (1,0) [0|15] "" Vector__XXX
 SG_ Type_of_Steering_Forces : 36|4@1+ (1,0) [0|15] "" Vector__XXX
 SG_ Type_of_Steering_Transmission : 40|4@1+ (1,0) [0|15] "" Vector__XXX

BO_ 2163215360 ETC8: 8 Vector__XXX
 SG_ Transmission_Torque_Converter_Ra : 0|16@1+ (1,0) [0|65535] "" Vector__XXX

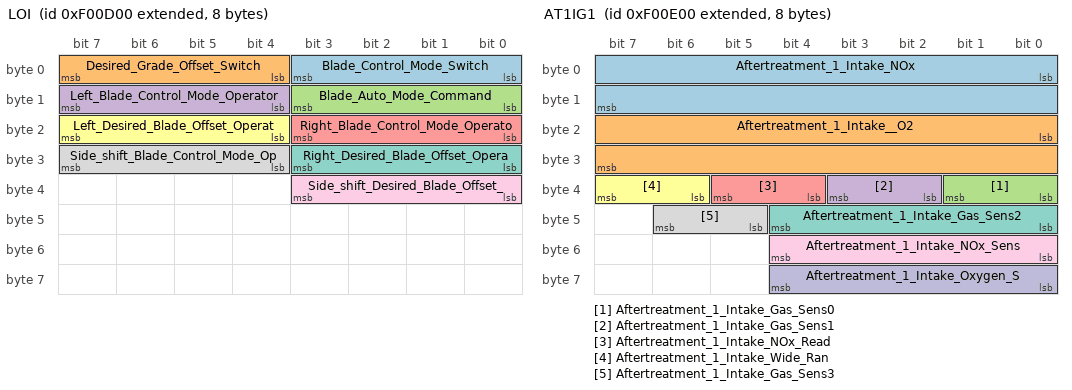
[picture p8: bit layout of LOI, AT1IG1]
BO_ 2163215616 LOI: 8 Vector__XXX
 SG_ Blade_Control_Mode_Switch : 0|4@1+ (1,0) [0|15] "" Vector__XXX
 SG_ Desired_Grade_Offset_Switch : 4|4@1+ (1,0) [0|15] "" Vector__XXX
 SG_ Blade_Auto_Mode_Command : 8|4@1+ (1,0) [0|15] "" Vector__XXX
 SG_ Left_Blade_Control_Mode_Operator : 12|4@1+ (1,0) [0|15] "" Vector__XXX
 SG_ Right_Blade_Control_Mode_Operato : 16|4@1+ (1,0) [0|15] "" Vector__XXX
 SG_ Left_Desired_Blade_Offset_Operat : 20|4@1+ (1,0) [0|15] "" Vector__XXX
 SG_ Right_Desired_Blade_Offset_Opera : 24|4@1+ (1,0) [0|15] "" Vector__XXX
 SG_ Side_shift_Blade_Control_Mode_Op : 28|4@1+ (1,0) [0|15] "" Vector__XXX
 SG_ Side_shift_Desired_Blade_Offset_ : 32|4@1+ (1,0) [0|15] "" Vector__XXX

BO_ 2163215872 AT1IG1: 8 Vector__XXX
 SG_ Aftertreatment_1_Intake_NOx : 0|16@1+ (1,0) [0|65535] "" Vector__XXX
 SG_ Aftertreatment_1_Intake__O2 : 16|16@1+ (1,0) [0|65535] "" Vector__XXX
 SG_ Aftertreatment_1_Intake_Gas_Sens0 : 32|2@1+ (1,0) [0|3] "" Vector__XXX
 SG_ Aftertreatment_1_Intake_Gas_Sens1 : 34|2@1+ (1,0) [0|3] "" Vector__XXX
 SG_ Aftertreatment_1_Intake_NOx_Read : 36|2@1+ (1,0) [0|3] "" Vector__XXX
 SG_ Aftertreatment_1_Intake_Wide_Ran : 38|2@1+ (1,0) [0|3] "" Vector__XXX
 SG_ Aftertreatment_1_Intake_Gas_Sens2 : 40|5@1+ (1,0) [0|31] "" Vector__XXX
 SG_ Aftertreatment_1_Intake_Gas_Sens3 : 45|2@1+ (1,0) [0|3] "" Vector__XXX
 SG_ Aftertreatment_1_Intake_NOx_Sens : 48|5@1+ (1,0) [0|31] "" Vector__XXX
 SG_ Aftertreatment_1_Intake_Oxygen_S : 56|5@1+ (1,0) [0|31] "" Vector__XXX

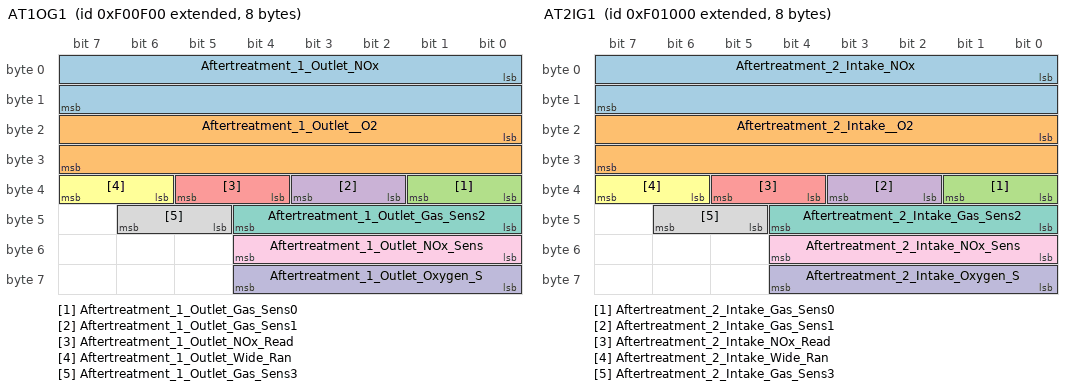
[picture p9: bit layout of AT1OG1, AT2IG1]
BO_ 2163216128 AT1OG1: 8 Vector__XXX
 SG_ Aftertreatment_1_Outlet_NOx : 0|16@1+ (1,0) [0|65535] "" Vector__XXX
 SG_ Aftertreatment_1_Outlet__O2 : 16|16@1+ (1,0) [0|65535] "" Vector__XXX
 SG_ Aftertreatment_1_Outlet_Gas_Sens0 : 32|2@1+ (1,0) [0|3] "" Vector__XXX
 SG_ Aftertreatment_1_Outlet_Gas_Sens1 : 34|2@1+ (1,0) [0|3] "" Vector__XXX
 SG_ Aftertreatment_1_Outlet_NOx_Read : 36|2@1+ (1,0) [0|3] "" Vector__XXX
 SG_ Aftertreatment_1_Outlet_Wide_Ran : 38|2@1+ (1,0) [0|3] "" Vector__XXX
 SG_ Aftertreatment_1_Outlet_Gas_Sens2 : 40|5@1+ (1,0) [0|31] "" Vector__XXX
 SG_ Aftertreatment_1_Outlet_Gas_Sens3 : 45|2@1+ (1,0) [0|3] "" Vector__XXX
 SG_ Aftertreatment_1_Outlet_NOx_Sens : 48|5@1+ (1,0) [0|31] "" Vector__XXX
 SG_ Aftertreatment_1_Outlet_Oxygen_S : 56|5@1+ (1,0) [0|31] "" Vector__XXX

BO_ 2163216384 AT2IG1: 8 Vector__XXX
 SG_ Aftertreatment_2_Intake_NOx : 0|16@1+ (1,0) [0|65535] "" Vector__XXX
 SG_ Aftertreatment_2_Intake__O2 : 16|16@1+ (1,0) [0|65535] "" Vector__XXX
 SG_ Aftertreatment_2_Intake_Gas_Sens0 : 32|2@1+ (1,0) [0|3] "" Vector__XXX
 SG_ Aftertreatment_2_Intake_Gas_Sens1 : 34|2@1+ (1,0) [0|3] "" Vector__XXX
 SG_ Aftertreatment_2_Intake_NOx_Read : 36|2@1+ (1,0) [0|3] "" Vector__XXX
 SG_ Aftertreatment_2_Intake_Wide_Ran : 38|2@1+ (1,0) [0|3] "" Vector__XXX
 SG_ Aftertreatment_2_Intake_Gas_Sens2 : 40|5@1+ (1,0) [0|31] "" Vector__XXX
 SG_ Aftertreatment_2_Intake_Gas_Sens3 : 45|2@1+ (1,0) [0|3] "" Vector__XXX
 SG_ Aftertreatment_2_Intake_NOx_Sens : 48|5@1+ (1,0) [0|31] "" Vector__XXX
 SG_ Aftertreatment_2_Intake_Oxygen_S : 56|5@1+ (1,0) [0|31] "" Vector__XXX

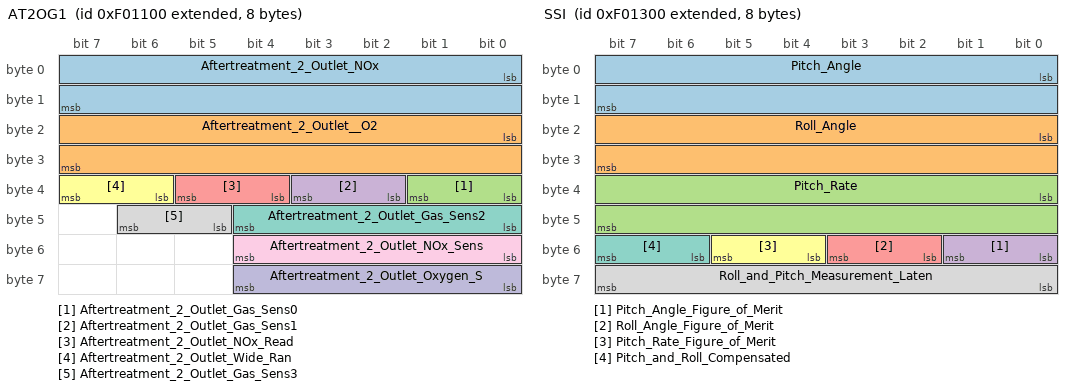
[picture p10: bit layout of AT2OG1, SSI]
BO_ 2163216640 AT2OG1: 8 Vector__XXX
 SG_ Aftertreatment_2_Outlet_NOx : 0|16@1+ (1,0) [0|65535] "" Vector__XXX
 SG_ Aftertreatment_2_Outlet__O2 : 16|16@1+ (1,0) [0|65535] "" Vector__XXX
 SG_ Aftertreatment_2_Outlet_Gas_Sens0 : 32|2@1+ (1,0) [0|3] "" Vector__XXX
 SG_ Aftertreatment_2_Outlet_Gas_Sens1 : 34|2@1+ (1,0) [0|3] "" Vector__XXX
 SG_ Aftertreatment_2_Outlet_NOx_Read : 36|2@1+ (1,0) [0|3] "" Vector__XXX
 SG_ Aftertreatment_2_Outlet_Wide_Ran : 38|2@1+ (1,0) [0|3] "" Vector__XXX
 SG_ Aftertreatment_2_Outlet_Gas_Sens2 : 40|5@1+ (1,0) [0|31] "" Vector__XXX
 SG_ Aftertreatment_2_Outlet_Gas_Sens3 : 45|2@1+ (1,0) [0|3] "" Vector__XXX
 SG_ Aftertreatment_2_Outlet_NOx_Sens : 48|5@1+ (1,0) [0|31] "" Vector__XXX
 SG_ Aftertreatment_2_Outlet_Oxygen_S : 56|5@1+ (1,0) [0|31] "" Vector__XXX

BO_ 2163216896 FWSS1: 8 Vector__XXX
 SG_ Fifth_Wheel_Vertical_Force : 0|16@1+ (1,0) [0|65535] "" Vector__XXX
 SG_ Fifth_Wheel_Drawbar_Force : 16|16@1+ (1,0) [0|65535] "" Vector__XXX
 SG_ Fifth_Wheel_Roll_Moment_ : 32|16@1+ (1,0) [0|65535] "" Vector__XXX
 SG_ Fifth_Wheel_Roll_Warning_Indicat : 48|2@1+ (1,0) [0|3] "" Vector__XXX

BO_ 2163217152 SSI: 8 Vector__XXX
 SG_ Pitch_Angle : 0|16@1+ (1,0) [0|65535] "" Vector__XXX
 SG_ Roll_Angle : 16|16@1+ (1,0) [0|65535] "" Vector__XXX
 SG_ Pitch_Rate : 32|16@1+ (1,0) [0|65535] "" Vector__XXX
 SG_ Pitch_Angle_Figure_of_Merit : 48|2@1+ (1,0) [0|3] "" Vector__XXX
 SG_ Roll_Angle_Figure_of_Merit : 50|2@1+ (1,0) [0|3] "" Vector__XXX
 SG_ Pitch_Rate_Figure_of_Merit : 52|2@1+ (1,0) [0|3] "" Vector__XXX
 SG_ Pitch_and_Roll_Compensated : 54|2@1+ (1,0) [0|3] "" Vector__XXX
 SG_ Roll_and_Pitch_Measurement_Laten : 56|8@1+ (1,0) [0|255] "" Vector__XXX

BO_ 2163217408 BI: 8 Vector__XXX
 SG_ Relative_Blade_Height : 0|16@1+ (1,0) [0|65535] "" Vector__XXX
 SG_ Blade_Rotation_Angle : 16|16@1+ (1,0) [0|65535] "" Vector__XXX
 SG_ Relative_Blade_Height_and_Blade_ : 32|8@1+ (1,0) [0|255] "" Vector__XXX
 SG_ Relative_Blade_Height_Figure_of_ : 40|2@1+ (1,0) [0|3] "" Vector__XXX
 SG_ Blade_Rotation_Angle_Figure_of_M : 42|2@1+ (1,0) [0|3] "" Vector__XXX

BO_ 2163217920 CCS: 8 Vector__XXX
 SG_ Engine_Cylinder_1_Combustion_Sta : 0|2@1+ (1,0) [0|3] "" Vector__XXX
 SG_ Engine_Cylinder_2_Combustion_Sta : 2|2@1+ (1,0) [0|3] "" Vector__XXX
 SG_ Engine_Cylinder_3_Combustion_Sta : 4|2@1+ (1,0) [0|3] "" Vector__XXX
 SG_ Engine_Cylinder_4_Combustion_Sta : 6|2@1+ (1,0) [0|3] "" Vector__XXX
 SG_ Engine_Cylinder_5_Combustion_Sta : 8|2@1+ (1,0) [0|3] "" Vector__XXX
 SG_ Engine_Cylinder_6_Combustion_Sta : 10|2@1+ (1,0) [0|3] "" Vector__XXX
 SG_ Engine_Cylinder_7_Combustion_Sta : 12|2@1+ (1,0) [0|3] "" Vector__XXX
 SG_ Engine_Cylinder_8_Combustion_Sta : 14|2@1+ (1,0) [0|3] "" Vector__XXX
 SG_ Engine_Cylinder_9_Combustion_Sta : 16|2@1+ (1,0) [0|3] "" Vector__XXX
 SG_ Engine_Cylinder_10_Combustion_St : 18|2@1+ (1,0) [0|3] "" Vector__XXX
 SG_ Engine_Cylinder_11_Combustion_St : 20|2@1+ (1,0) [0|3] "" Vector__XXX
 SG_ Engine_Cylinder_12_Combustion_St : 22|2@1+ (1,0) [0|3] "" Vector__XXX
 SG_ Engine_Cylinder_13_Combustion_St : 24|2@1+ (1,0) [0|3] "" Vector__XXX
 SG_ Engine_Cylinder_14_Combustion_St : 26|2@1+ (1,0) [0|3] "" Vector__XXX
 SG_ Engine_Cylinder_15_Combustion_St : 28|2@1+ (1,0) [0|3] "" Vector__XXX
 SG_ Engine_Cylinder_16_Combustion_St : 30|2@1+ (1,0) [0|3] "" Vector__XXX
 SG_ Engine_Cylinder_17_Combustion_St : 32|2@1+ (1,0) [0|3] "" Vector__XXX
 SG_ Engine_Cylinder_18_Combustion_St : 34|2@1+ (1,0) [0|3] "" Vector__XXX
 SG_ Engine_Cylinder_19_Combustion_St : 36|2@1+ (1,0) [0|3] "" Vector__XXX
 SG_ Engine_Cylinder_20_Combustion_St : 38|2@1+ (1,0) [0|3] "" Vector__XXX
 SG_ Engine_Cylinder_21_Combustion_St : 40|2@1+ (1,0) [0|3] "" Vector__XXX
 SG_ Engine_Cylinder_22_Combustion_St : 42|2@1+ (1,0) [0|3] "" Vector__XXX
 SG_ Engine_Cylinder_23_Combustion_St : 44|2@1+ (1,0) [0|3] "" Vector__XXX
 SG_ Engine_Cylinder_24_Combustion_St : 46|2@1+ (1,0) [0|3] "" Vector__XXX

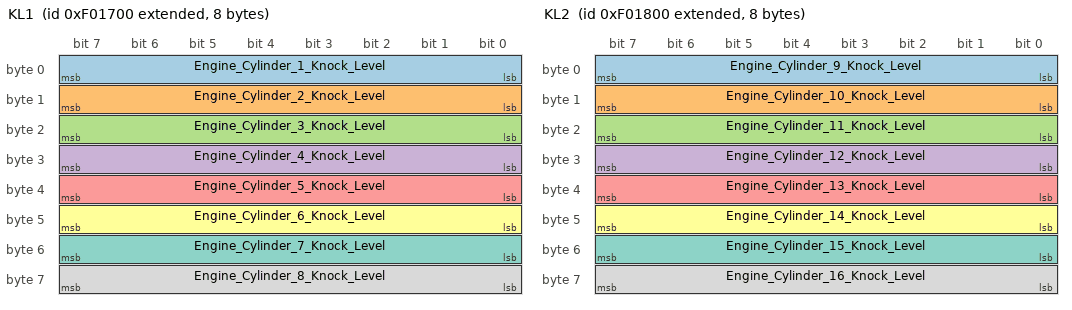
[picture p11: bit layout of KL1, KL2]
BO_ 2163218176 KL1: 8 Vector__XXX
 SG_ Engine_Cylinder_1_Knock_Level : 0|8@1+ (1,0) [0|255] "" Vector__XXX
 SG_ Engine_Cylinder_2_Knock_Level : 8|8@1+ (1,0) [0|255] "" Vector__XXX
 SG_ Engine_Cylinder_3_Knock_Level : 16|8@1+ (1,0) [0|255] "" Vector__XXX
 SG_ Engine_Cylinder_4_Knock_Level : 24|8@1+ (1,0) [0|255] "" Vector__XXX
 SG_ Engine_Cylinder_5_Knock_Level : 32|8@1+ (1,0) [0|255] "" Vector__XXX
 SG_ Engine_Cylinder_6_Knock_Level : 40|8@1+ (1,0) [0|255] "" Vector__XXX
 SG_ Engine_Cylinder_7_Knock_Level : 48|8@1+ (1,0) [0|255] "" Vector__XXX
 SG_ Engine_Cylinder_8_Knock_Level : 56|8@1+ (1,0) [0|255] "" Vector__XXX

BO_ 2163218432 KL2: 8 Vector__XXX
 SG_ Engine_Cylinder_9_Knock_Level : 0|8@1+ (1,0) [0|255] "" Vector__XXX
 SG_ Engine_Cylinder_10_Knock_Level : 8|8@1+ (1,0) [0|255] "" Vector__XXX
 SG_ Engine_Cylinder_11_Knock_Level : 16|8@1+ (1,0) [0|255] "" Vector__XXX
 SG_ Engine_Cylinder_12_Knock_Level : 24|8@1+ (1,0) [0|255] "" Vector__XXX
 SG_ Engine_Cylinder_13_Knock_Level : 32|8@1+ (1,0) [0|255] "" Vector__XXX
 SG_ Engine_Cylinder_14_Knock_Level : 40|8@1+ (1,0) [0|255] "" Vector__XXX
 SG_ Engine_Cylinder_15_Knock_Level : 48|8@1+ (1,0) [0|255] "" Vector__XXX
 SG_ Engine_Cylinder_16_Knock_Level : 56|8@1+ (1,0) [0|255] "" Vector__XXX

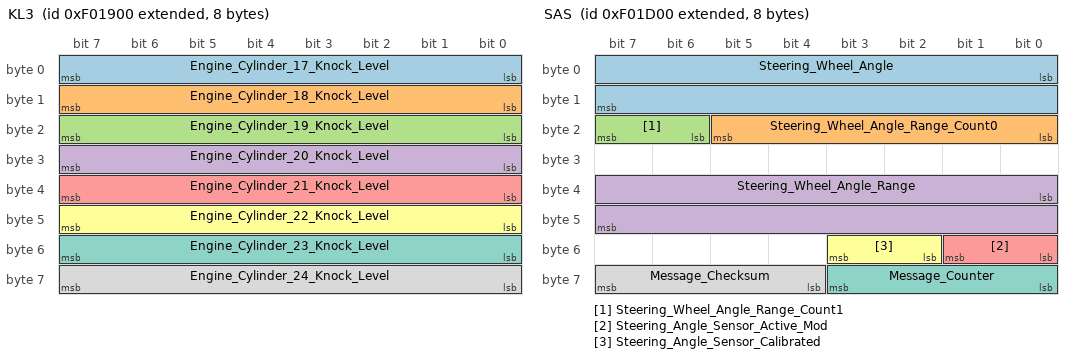
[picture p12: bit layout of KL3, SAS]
BO_ 2163218688 KL3: 8 Vector__XXX
 SG_ Engine_Cylinder_17_Knock_Level : 0|8@1+ (1,0) [0|255] "" Vector__XXX
 SG_ Engine_Cylinder_18_Knock_Level : 8|8@1+ (1,0) [0|255] "" Vector__XXX
 SG_ Engine_Cylinder_19_Knock_Level : 16|8@1+ (1,0) [0|255] "" Vector__XXX
 SG_ Engine_Cylinder_20_Knock_Level : 24|8@1+ (1,0) [0|255] "" Vector__XXX
 SG_ Engine_Cylinder_21_Knock_Level : 32|8@1+ (1,0) [0|255] "" Vector__XXX
 SG_ Engine_Cylinder_22_Knock_Level : 40|8@1+ (1,0) [0|255] "" Vector__XXX
 SG_ Engine_Cylinder_23_Knock_Level : 48|8@1+ (1,0) [0|255] "" Vector__XXX
 SG_ Engine_Cylinder_24_Knock_Level : 56|8@1+ (1,0) [0|255] "" Vector__XXX

BO_ 2163218944 TFAC: 8 Vector__XXX
 SG_ Engine_Throttle_Actuator_1_Contr : 0|16@1+ (1,0) [0|65535] "" Vector__XXX
 SG_ Engine_Throttle_Actuator_2_Contr : 16|16@1+ (1,0) [0|65535] "" Vector__XXX
 SG_ Engine_Fuel_Actuator_1_Control_C : 32|16@1+ (1,0) [0|65535] "" Vector__XXX
 SG_ Engine_Fuel_Actuator_2_Control_C : 48|16@1+ (1,0) [0|65535] "" Vector__XXX

BO_ 2163219712 SAS: 8 Vector__XXX
 SG_ Steering_Wheel_Angle : 0|16@1+ (1,0) [0|65535] "" Vector__XXX
 SG_ Steering_Wheel_Angle_Range_Count0 : 16|6@1+ (1,0) [0|63] "" Vector__XXX
 SG_ Steering_Wheel_Angle_Range_Count1 : 22|2@1+ (1,0) [0|3] "" Vector__XXX
 SG_ Steering_Wheel_Angle_Range : 32|16@1+ (1,0) [0|65535] "" Vector__XXX
 SG_ Steering_Angle_Sensor_Active_Mod : 48|2@1+ (1,0) [0|3] "" Vector__XXX
 SG_ Steering_Angle_Sensor_Calibrated : 50|2@1+ (1,0) [0|3] "" Vector__XXX
 SG_ Message_Counter : 56|4@1+ (1,0) [0|15] "" Vector__XXX
 SG_ Message_Checksum : 60|4@1+ (1,0) [0|15] "" Vector__XXX

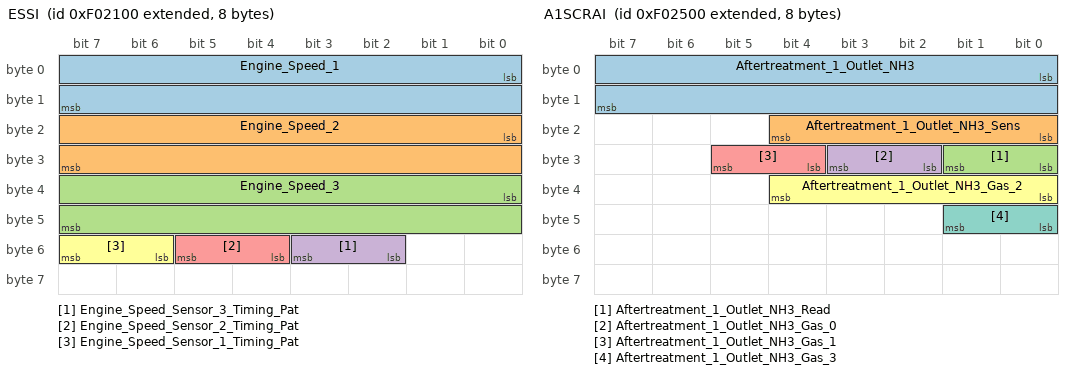
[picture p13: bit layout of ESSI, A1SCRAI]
BO_ 2163220736 ESSI: 8 Vector__XXX
 SG_ Engine_Speed_1 : 0|16@1+ (1,0) [0|65535] "" Vector__XXX
 SG_ Engine_Speed_2 : 16|16@1+ (1,0) [0|65535] "" Vector__XXX
 SG_ Engine_Speed_3 : 32|16@1+ (1,0) [0|65535] "" Vector__XXX
 SG_ Engine_Speed_Sensor_3_Timing_Pat : 50|2@1+ (1,0) [0|3] "" Vector__XXX
 SG_ Engine_Speed_Sensor_2_Timing_Pat : 52|2@1+ (1,0) [0|3] "" Vector__XXX
 SG_ Engine_Speed_Sensor_1_Timing_Pat : 54|2@1+ (1,0) [0|3] "" Vector__XXX

BO_ 2163221248 A1SCRDSI1: 8 Vector__XXX
 SG_ Aftertreatment_1_SCR_Actual_Dosi : 0|16@1+ (1,0) [0|65535] "" Vector__XXX
 SG_ Aftertreatment_1_SCR_System_Stat : 16|4@1+ (1,0) [0|15] "" Vector__XXX
 SG_ Aftertreatment_1_SCR_Actual_Reag : 24|16@1+ (1,0) [0|65535] "" Vector__XXX
 SG_ Aftertreatment_1_SCR_Dosing_Reag : 40|8@1+ (1,0) [0|255] "" Vector__XXX

BO_ 2163221504 A1SCRDSR1: 8 Vector__XXX
 SG_ Aftertreatment_1_SCR_Requested_D : 0|16@1+ (1,0) [0|65535] "" Vector__XXX
 SG_ Aftertreatment_1_SCR_System_Requ : 16|4@1+ (1,0) [0|15] "" Vector__XXX
 SG_ Aftertreatment_1_SCR_Requested_R : 24|16@1+ (1,0) [0|65535] "" Vector__XXX

BO_ 2163221760 A1SCRAI: 8 Vector__XXX
 SG_ Aftertreatment_1_Outlet_NH3 : 0|16@1+ (1,0) [0|65535] "" Vector__XXX
 SG_ Aftertreatment_1_Outlet_NH3_Sens : 16|5@1+ (1,0) [0|31] "" Vector__XXX
 SG_ Aftertreatment_1_Outlet_NH3_Read : 24|2@1+ (1,0) [0|3] "" Vector__XXX
 SG_ Aftertreatment_1_Outlet_NH3_Gas_0 : 26|2@1+ (1,0) [0|3] "" Vector__XXX
 SG_ Aftertreatment_1_Outlet_NH3_Gas_1 : 28|2@1+ (1,0) [0|3] "" Vector__XXX
 SG_ Aftertreatment_1_Outlet_NH3_Gas_2 : 32|5@1+ (1,0) [0|31] "" Vector__XXX
 SG_ Aftertreatment_1_Outlet_NH3_Gas_3 : 40|2@1+ (1,0) [0|3] "" Vector__XXX

BO_ 2163222016 A2SCRDSI1: 8 Vector__XXX
 SG_ Aftertreatment_2_SCR_Actual_Dosi : 0|16@1+ (1,0) [0|65535] "" Vector__XXX
 SG_ Aftertreatment_2_SCR_System_Stat : 16|4@1+ (1,0) [0|15] "" Vector__XXX
 SG_ Aftertreatment_2_SCR_Actual_Reag : 24|16@1+ (1,0) [0|65535] "" Vector__XXX
 SG_ Aftertreatment_2_SCR_Dosing_Reag : 40|8@1+ (1,0) [0|255] "" Vector__XXX

BO_ 2163222272 A2SCRDSR1: 8 Vector__XXX
 SG_ Aftertreatment_2_SCR_Requested_D : 0|16@1+ (1,0) [0|65535] "" Vector__XXX
 SG_ Aftertreatment_2_SCR_System_Requ : 16|4@1+ (1,0) [0|15] "" Vector__XXX
 SG_ Aftertreatment_2_SCR_Requested_R : 24|16@1+ (1,0) [0|65535] "" Vector__XXX

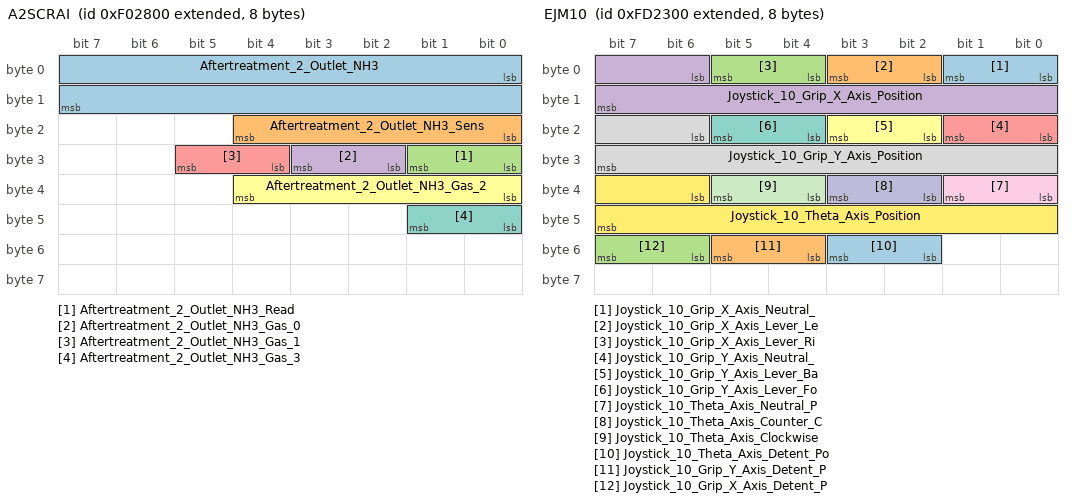
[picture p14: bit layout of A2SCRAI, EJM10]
BO_ 2163222528 A2SCRAI: 8 Vector__XXX
 SG_ Aftertreatment_2_Outlet_NH3 : 0|16@1+ (1,0) [0|65535] "" Vector__XXX
 SG_ Aftertreatment_2_Outlet_NH3_Sens : 16|5@1+ (1,0) [0|31] "" Vector__XXX
 SG_ Aftertreatment_2_Outlet_NH3_Read : 24|2@1+ (1,0) [0|3] "" Vector__XXX
 SG_ Aftertreatment_2_Outlet_NH3_Gas_0 : 26|2@1+ (1,0) [0|3] "" Vector__XXX
 SG_ Aftertreatment_2_Outlet_NH3_Gas_1 : 28|2@1+ (1,0) [0|3] "" Vector__XXX
 SG_ Aftertreatment_2_Outlet_NH3_Gas_2 : 32|5@1+ (1,0) [0|31] "" Vector__XXX
 SG_ Aftertreatment_2_Outlet_NH3_Gas_3 : 40|2@1+ (1,0) [0|3] "" Vector__XXX

BO_ 2164073216 EJM10: 8 Vector__XXX
 SG_ Joystick_10_Grip_X_Axis_Neutral_ : 0|2@1+ (1,0) [0|3] "" Vector__XXX
 SG_ Joystick_10_Grip_X_Axis_Lever_Le : 2|2@1+ (1,0) [0|3] "" Vector__XXX
 SG_ Joystick_10_Grip_X_Axis_Lever_Ri : 4|2@1+ (1,0) [0|3] "" Vector__XXX
 SG_ Joystick_10_Grip_X_Axis_Position : 6|10@1+ (1,0) [0|1023] "" Vector__XXX
 SG_ Joystick_10_Grip_Y_Axis_Neutral_ : 16|2@1+ (1,0) [0|3] "" Vector__XXX
 SG_ Joystick_10_Grip_Y_Axis_Lever_Ba : 18|2@1+ (1,0) [0|3] "" Vector__XXX
 SG_ Joystick_10_Grip_Y_Axis_Lever_Fo : 20|2@1+ (1,0) [0|3] "" Vector__XXX
 SG_ Joystick_10_Grip_Y_Axis_Position : 22|10@1+ (1,0) [0|1023] "" Vector__XXX
 SG_ Joystick_10_Theta_Axis_Neutral_P : 32|2@1+ (1,0) [0|3] "" Vector__XXX
 SG_ Joystick_10_Theta_Axis_Counter_C : 34|2@1+ (1,0) [0|3] "" Vector__XXX
 SG_ Joystick_10_Theta_Axis_Clockwise : 36|2@1+ (1,0) [0|3] "" Vector__XXX
 SG_ Joystick_10_Theta_Axis_Position : 38|10@1+ (1,0) [0|1023] "" Vector__XXX
 SG_ Joystick_10_Theta_Axis_Detent_Po : 50|2@1+ (1,0) [0|3] "" Vector__XXX
 SG_ Joystick_10_Grip_Y_Axis_Detent_P : 52|2@1+ (1,0) [0|3] "" Vector__XXX
 SG_ Joystick_10_Grip_X_Axis_Detent_P : 54|2@1+ (1,0) [0|3] "" Vector__XXX

BO_ 2164073472 BJM10: 8 Vector__XXX
 SG_ Joystick_10_X_Axis_Neutral_Posit : 0|2@1+ (1,0) [0|3] "" Vector__XXX
 SG_ Joystick_10_X_Axis_Lever_Left_Ne : 2|2@1+ (1,0) [0|3] "" Vector__XXX
 SG_ Joystick_10_X_Axis_Lever_Right_P : 4|2@1+ (1,0) [0|3] "" Vector__XXX
 SG_ Joystick_10_X_Axis_Position : 6|10@1+ (1,0) [0|1023] "" Vector__XXX
 SG_ Joystick_10_Y_Axis_Neutral_Posit : 16|2@1+ (1,0) [0|3] "" Vector__XXX
 SG_ Joystick_10_Y_Axis_Lever_Back_Ne : 18|2@1+ (1,0) [0|3] "" Vector__XXX
 SG_ Joystick_10_Y_Axis_Lever_Forward : 20|2@1+ (1,0) [0|3] "" Vector__XXX
 SG_ Joystick_10_Y_Axis_Position : 22|10@1+ (1,0) [0|1023] "" Vector__XXX
 SG_ Joystick_10_Y_Axis_Detent_Positi : 36|2@1+ (1,0) [0|3] "" Vector__XXX
 SG_ Joystick_10_X_Axis_Detent_Positi : 38|2@1+ (1,0) [0|3] "" Vector__XXX
 SG_ Joystick_10_Button_4_Pressed_Sta : 40|2@1+ (1,0) [0|3] "" Vector__XXX
 SG_ Joystick_10_Button_3_Pressed_Sta : 42|2@1+ (1,0) [0|3] "" Vector__XXX
 SG_ Joystick_10_Button_2_Pressed_Sta : 44|2@1+ (1,0) [0|3] "" Vector__XXX
 SG_ Joystick_10_Button_1_Pressed_Sta : 46|2@1+ (1,0) [0|3] "" Vector__XXX
 SG_ Joystick_10_Button_8_Pressed_Sta : 48|2@1+ (1,0) [0|3] "" Vector__XXX
 SG_ Joystick_10_Button_7_Pressed_Sta : 50|2@1+ (1,0) [0|3] "" Vector__XXX
 SG_ Joystick_10_Button_6_Pressed_Sta : 52|2@1+ (1,0) [0|3] "" Vector__XXX
 SG_ Joystick_10_Button_5_Pressed_Sta : 54|2@1+ (1,0) [0|3] "" Vector__XXX
 SG_ Joystick_10_Button_12_Pressed_St : 56|2@1+ (1,0) [0|3] "" Vector__XXX
 SG_ Joystick_10_Button_11_Pressed_St : 58|2@1+ (1,0) [0|3] "" Vector__XXX
 SG_ Joystick_10_Button_10_Pressed_St : 60|2@1+ (1,0) [0|3] "" Vector__XXX
 SG_ Joystick_10_Button_9_Pressed_Sta : 62|2@1+ (1,0) [0|3] "" Vector__XXX

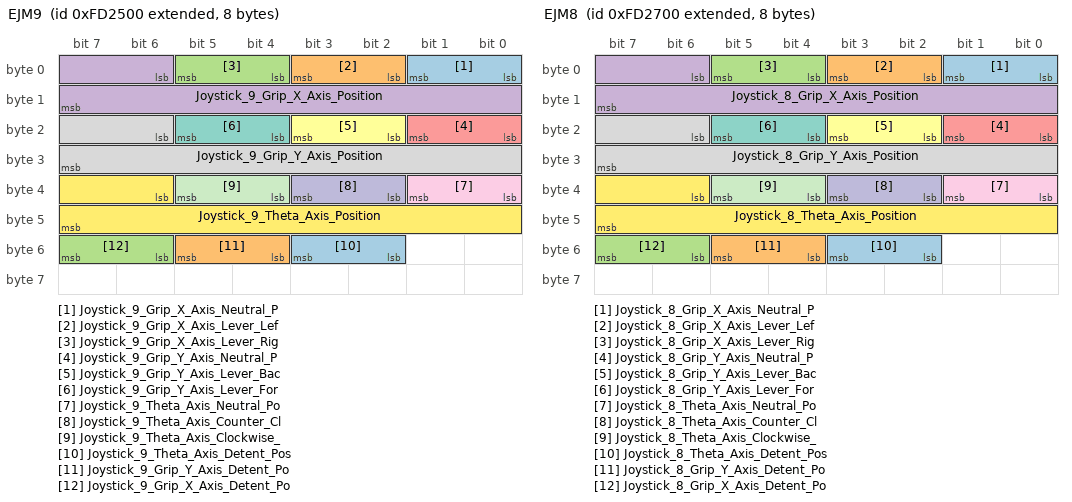
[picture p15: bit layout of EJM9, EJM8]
BO_ 2164073728 EJM9: 8 Vector__XXX
 SG_ Joystick_9_Grip_X_Axis_Neutral_P : 0|2@1+ (1,0) [0|3] "" Vector__XXX
 SG_ Joystick_9_Grip_X_Axis_Lever_Lef : 2|2@1+ (1,0) [0|3] "" Vector__XXX
 SG_ Joystick_9_Grip_X_Axis_Lever_Rig : 4|2@1+ (1,0) [0|3] "" Vector__XXX
 SG_ Joystick_9_Grip_X_Axis_Position : 6|10@1+ (1,0) [0|1023] "" Vector__XXX
 SG_ Joystick_9_Grip_Y_Axis_Neutral_P : 16|2@1+ (1,0) [0|3] "" Vector__XXX
 SG_ Joystick_9_Grip_Y_Axis_Lever_Bac : 18|2@1+ (1,0) [0|3] "" Vector__XXX
 SG_ Joystick_9_Grip_Y_Axis_Lever_For : 20|2@1+ (1,0) [0|3] "" Vector__XXX
 SG_ Joystick_9_Grip_Y_Axis_Position : 22|10@1+ (1,0) [0|1023] "" Vector__XXX
 SG_ Joystick_9_Theta_Axis_Neutral_Po : 32|2@1+ (1,0) [0|3] "" Vector__XXX
 SG_ Joystick_9_Theta_Axis_Counter_Cl : 34|2@1+ (1,0) [0|3] "" Vector__XXX
 SG_ Joystick_9_Theta_Axis_Clockwise_ : 36|2@1+ (1,0) [0|3] "" Vector__XXX
 SG_ Joystick_9_Theta_Axis_Position : 38|10@1+ (1,0) [0|1023] "" Vector__XXX
 SG_ Joystick_9_Theta_Axis_Detent_Pos : 50|2@1+ (1,0) [0|3] "" Vector__XXX
 SG_ Joystick_9_Grip_Y_Axis_Detent_Po : 52|2@1+ (1,0) [0|3] "" Vector__XXX
 SG_ Joystick_9_Grip_X_Axis_Detent_Po : 54|2@1+ (1,0) [0|3] "" Vector__XXX

BO_ 2164073984 BJM9: 8 Vector__XXX
 SG_ Joystick_9_X_Axis_Neutral_Positi : 0|2@1+ (1,0) [0|3] "" Vector__XXX
 SG_ Joystick_9_X_Axis_Lever_Left_Neg : 2|2@1+ (1,0) [0|3] "" Vector__XXX
 SG_ Joystick_9_X_Axis_Lever_Right_Po : 4|2@1+ (1,0) [0|3] "" Vector__XXX
 SG_ Joystick_9_X_Axis_Position : 6|10@1+ (1,0) [0|1023] "" Vector__XXX
 SG_ Joystick_9_Y_Axis_Neutral_Positi : 16|2@1+ (1,0) [0|3] "" Vector__XXX
 SG_ Joystick_9_Y_Axis_Lever_Back_Neg : 18|2@1+ (1,0) [0|3] "" Vector__XXX
 SG_ Joystick_9_Y_Axis_Lever_Forward_ : 20|2@1+ (1,0) [0|3] "" Vector__XXX
 SG_ Joystick_9_Y_Axis_Position : 22|10@1+ (1,0) [0|1023] "" Vector__XXX
 SG_ Joystick_9_Y_Axis_Detent_Positio : 36|2@1+ (1,0) [0|3] "" Vector__XXX
 SG_ Joystick_9_X_Axis_Detent_Positio : 38|2@1+ (1,0) [0|3] "" Vector__XXX
 SG_ Joystick_9_Button_4_Pressed_Stat : 40|2@1+ (1,0) [0|3] "" Vector__XXX
 SG_ Joystick_9_Button_3_Pressed_Stat : 42|2@1+ (1,0) [0|3] "" Vector__XXX
 SG_ Joystick_9_Button_2_Pressed_Stat : 44|2@1+ (1,0) [0|3] "" Vector__XXX
 SG_ Joystick_9_Button_1_Pressed_Stat : 46|2@1+ (1,0) [0|3] "" Vector__XXX
 SG_ Joystick_9_Button_8_Pressed_Stat : 48|2@1+ (1,0) [0|3] "" Vector__XXX
 SG_ Joystick_9_Button_7_Pressed_Stat : 50|2@1+ (1,0) [0|3] "" Vector__XXX
 SG_ Joystick_9_Button_6_Pressed_Stat : 52|2@1+ (1,0) [0|3] "" Vector__XXX
 SG_ Joystick_9_Button_5_Pressed_Stat : 54|2@1+ (1,0) [0|3] "" Vector__XXX
 SG_ Joystick_9_Button_12_Pressed_Sta : 56|2@1+ (1,0) [0|3] "" Vector__XXX
 SG_ Joystick_9_Button_11_Pressed_Sta : 58|2@1+ (1,0) [0|3] "" Vector__XXX
 SG_ Joystick_9_Button_10_Pressed_Sta : 60|2@1+ (1,0) [0|3] "" Vector__XXX
 SG_ Joystick_9_Button_9_Pressed_Stat : 62|2@1+ (1,0) [0|3] "" Vector__XXX

BO_ 2164074240 EJM8: 8 Vector__XXX
 SG_ Joystick_8_Grip_X_Axis_Neutral_P : 0|2@1+ (1,0) [0|3] "" Vector__XXX
 SG_ Joystick_8_Grip_X_Axis_Lever_Lef : 2|2@1+ (1,0) [0|3] "" Vector__XXX
 SG_ Joystick_8_Grip_X_Axis_Lever_Rig : 4|2@1+ (1,0) [0|3] "" Vector__XXX
 SG_ Joystick_8_Grip_X_Axis_Position : 6|10@1+ (1,0) [0|1023] "" Vector__XXX
 SG_ Joystick_8_Grip_Y_Axis_Neutral_P : 16|2@1+ (1,0) [0|3] "" Vector__XXX
 SG_ Joystick_8_Grip_Y_Axis_Lever_Bac : 18|2@1+ (1,0) [0|3] "" Vector__XXX
 SG_ Joystick_8_Grip_Y_Axis_Lever_For : 20|2@1+ (1,0) [0|3] "" Vector__XXX
 SG_ Joystick_8_Grip_Y_Axis_Position : 22|10@1+ (1,0) [0|1023] "" Vector__XXX
 SG_ Joystick_8_Theta_Axis_Neutral_Po : 32|2@1+ (1,0) [0|3] "" Vector__XXX
 SG_ Joystick_8_Theta_Axis_Counter_Cl : 34|2@1+ (1,0) [0|3] "" Vector__XXX
 SG_ Joystick_8_Theta_Axis_Clockwise_ : 36|2@1+ (1,0) [0|3] "" Vector__XXX
 SG_ Joystick_8_Theta_Axis_Position : 38|10@1+ (1,0) [0|1023] "" Vector__XXX
 SG_ Joystick_8_Theta_Axis_Detent_Pos : 50|2@1+ (1,0) [0|3] "" Vector__XXX
 SG_ Joystick_8_Grip_Y_Axis_Detent_Po : 52|2@1+ (1,0) [0|3] "" Vector__XXX
 SG_ Joystick_8_Grip_X_Axis_Detent_Po : 54|2@1+ (1,0) [0|3] "" Vector__XXX

BO_ 2164074496 BJM8: 8 Vector__XXX
 SG_ Joystick_8_X_Axis_Neutral_Positi : 0|2@1+ (1,0) [0|3] "" Vector__XXX
 SG_ Joystick_8_X_Axis_Lever_Left_Neg : 2|2@1+ (1,0) [0|3] "" Vector__XXX
 SG_ Joystick_8_X_Axis_Lever_Right_Po : 4|2@1+ (1,0) [0|3] "" Vector__XXX
 SG_ Joystick_8_X_Axis_Position : 6|10@1+ (1,0) [0|1023] "" Vector__XXX
 SG_ Joystick_8_Y_Axis_Neutral_Positi : 16|2@1+ (1,0) [0|3] "" Vector__XXX
 SG_ Joystick_8_Y_Axis_Lever_Back_Neg : 18|2@1+ (1,0) [0|3] "" Vector__XXX
 SG_ Joystick_8_Y_Axis_Lever_Forward_ : 20|2@1+ (1,0) [0|3] "" Vector__XXX
 SG_ Joystick_8_Y_Axis_Position : 22|10@1+ (1,0) [0|1023] "" Vector__XXX
 SG_ Joystick_8_Y_Axis_Detent_Positio : 36|2@1+ (1,0) [0|3] "" Vector__XXX
 SG_ Joystick_8_X_Axis_Detent_Positio : 38|2@1+ (1,0) [0|3] "" Vector__XXX
 SG_ Joystick_8_Button_4_Pressed_Stat : 40|2@1+ (1,0) [0|3] "" Vector__XXX
 SG_ Joystick_8_Button_3_Pressed_Stat : 42|2@1+ (1,0) [0|3] "" Vector__XXX
 SG_ Joystick_8_Button_2_Pressed_Stat : 44|2@1+ (1,0) [0|3] "" Vector__XXX
 SG_ Joystick_8_Button_1_Pressed_Stat : 46|2@1+ (1,0) [0|3] "" Vector__XXX
 SG_ Joystick_8_Button_8_Pressed_Stat : 48|2@1+ (1,0) [0|3] "" Vector__XXX
 SG_ Joystick_8_Button_7_Pressed_Stat : 50|2@1+ (1,0) [0|3] "" Vector__XXX
 SG_ Joystick_8_Button_6_Pressed_Stat : 52|2@1+ (1,0) [0|3] "" Vector__XXX
 SG_ Joystick_8_Button_5_Pressed_Stat : 54|2@1+ (1,0) [0|3] "" Vector__XXX
 SG_ Joystick_8_Button_12_Pressed_Sta : 56|2@1+ (1,0) [0|3] "" Vector__XXX
 SG_ Joystick_8_Button_11_Pressed_Sta : 58|2@1+ (1,0) [0|3] "" Vector__XXX
 SG_ Joystick_8_Button_10_Pressed_Sta : 60|2@1+ (1,0) [0|3] "" Vector__XXX
 SG_ Joystick_8_Button_9_Pressed_Stat : 62|2@1+ (1,0) [0|3] "" Vector__XXX

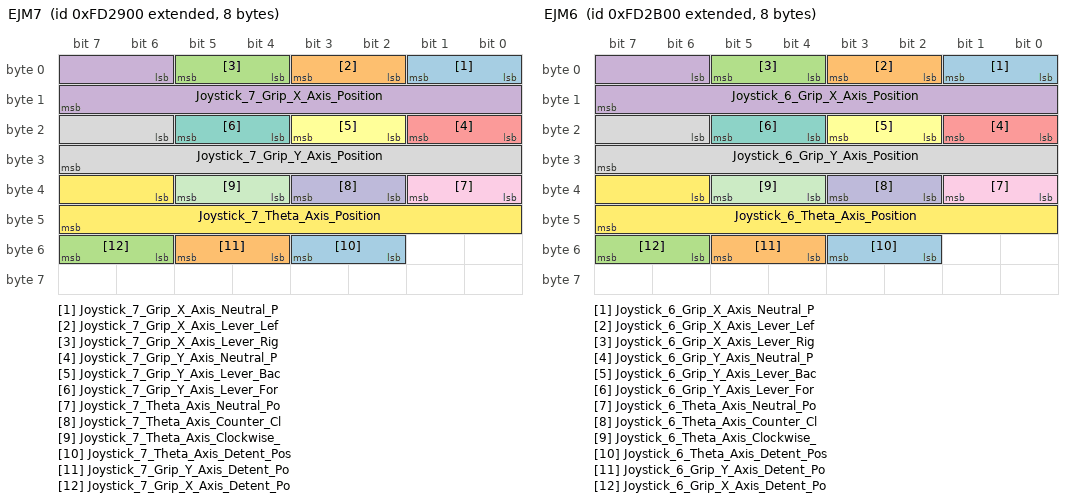
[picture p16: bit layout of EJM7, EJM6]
BO_ 2164074752 EJM7: 8 Vector__XXX
 SG_ Joystick_7_Grip_X_Axis_Neutral_P : 0|2@1+ (1,0) [0|3] "" Vector__XXX
 SG_ Joystick_7_Grip_X_Axis_Lever_Lef : 2|2@1+ (1,0) [0|3] "" Vector__XXX
 SG_ Joystick_7_Grip_X_Axis_Lever_Rig : 4|2@1+ (1,0) [0|3] "" Vector__XXX
 SG_ Joystick_7_Grip_X_Axis_Position : 6|10@1+ (1,0) [0|1023] "" Vector__XXX
 SG_ Joystick_7_Grip_Y_Axis_Neutral_P : 16|2@1+ (1,0) [0|3] "" Vector__XXX
 SG_ Joystick_7_Grip_Y_Axis_Lever_Bac : 18|2@1+ (1,0) [0|3] "" Vector__XXX
 SG_ Joystick_7_Grip_Y_Axis_Lever_For : 20|2@1+ (1,0) [0|3] "" Vector__XXX
 SG_ Joystick_7_Grip_Y_Axis_Position : 22|10@1+ (1,0) [0|1023] "" Vector__XXX
 SG_ Joystick_7_Theta_Axis_Neutral_Po : 32|2@1+ (1,0) [0|3] "" Vector__XXX
 SG_ Joystick_7_Theta_Axis_Counter_Cl : 34|2@1+ (1,0) [0|3] "" Vector__XXX
 SG_ Joystick_7_Theta_Axis_Clockwise_ : 36|2@1+ (1,0) [0|3] "" Vector__XXX
 SG_ Joystick_7_Theta_Axis_Position : 38|10@1+ (1,0) [0|1023] "" Vector__XXX
 SG_ Joystick_7_Theta_Axis_Detent_Pos : 50|2@1+ (1,0) [0|3] "" Vector__XXX
 SG_ Joystick_7_Grip_Y_Axis_Detent_Po : 52|2@1+ (1,0) [0|3] "" Vector__XXX
 SG_ Joystick_7_Grip_X_Axis_Detent_Po : 54|2@1+ (1,0) [0|3] "" Vector__XXX

BO_ 2164075008 BJM7: 8 Vector__XXX
 SG_ Joystick_7_X_Axis_Neutral_Positi : 0|2@1+ (1,0) [0|3] "" Vector__XXX
 SG_ Joystick_7_X_Axis_Lever_Left_Neg : 2|2@1+ (1,0) [0|3] "" Vector__XXX
 SG_ Joystick_7_X_Axis_Lever_Right_Po : 4|2@1+ (1,0) [0|3] "" Vector__XXX
 SG_ Joystick_7_X_Axis_Position : 6|10@1+ (1,0) [0|1023] "" Vector__XXX
 SG_ Joystick_7_Y_Axis_Neutral_Positi : 16|2@1+ (1,0) [0|3] "" Vector__XXX
 SG_ Joystick_7_Y_Axis_Lever_Back_Neg : 18|2@1+ (1,0) [0|3] "" Vector__XXX
 SG_ Joystick_7_Y_Axis_Lever_Forward_ : 20|2@1+ (1,0) [0|3] "" Vector__XXX
 SG_ Joystick_7_Y_Axis_Position : 22|10@1+ (1,0) [0|1023] "" Vector__XXX
 SG_ Joystick_7_Y_Axis_Detent_Positio : 36|2@1+ (1,0) [0|3] "" Vector__XXX
 SG_ Joystick_7_X_Axis_Detent_Positio : 38|2@1+ (1,0) [0|3] "" Vector__XXX
 SG_ Joystick_7_Button_4_Pressed_Stat : 40|2@1+ (1,0) [0|3] "" Vector__XXX
 SG_ Joystick_7_Button_3_Pressed_Stat : 42|2@1+ (1,0) [0|3] "" Vector__XXX
 SG_ Joystick_7_Button_2_Pressed_Stat : 44|2@1+ (1,0) [0|3] "" Vector__XXX
 SG_ Joystick_7_Button_1_Pressed_Stat : 46|2@1+ (1,0) [0|3] "" Vector__XXX
 SG_ Joystick_7_Button_8_Pressed_Stat : 48|2@1+ (1,0) [0|3] "" Vector__XXX
 SG_ Joystick_7_Button_7_Pressed_Stat : 50|2@1+ (1,0) [0|3] "" Vector__XXX
 SG_ Joystick_7_Button_6_Pressed_Stat : 52|2@1+ (1,0) [0|3] "" Vector__XXX
 SG_ Joystick_7_Button_5_Pressed_Stat : 54|2@1+ (1,0) [0|3] "" Vector__XXX
 SG_ Joystick_7_Button_12_Pressed_Sta : 56|2@1+ (1,0) [0|3] "" Vector__XXX
 SG_ Joystick_7_Button_11_Pressed_Sta : 58|2@1+ (1,0) [0|3] "" Vector__XXX
 SG_ Joystick_7_Button_10_Pressed_Sta : 60|2@1+ (1,0) [0|3] "" Vector__XXX
 SG_ Joystick_7_Button_9_Pressed_Stat : 62|2@1+ (1,0) [0|3] "" Vector__XXX

BO_ 2164075264 EJM6: 8 Vector__XXX
 SG_ Joystick_6_Grip_X_Axis_Neutral_P : 0|2@1+ (1,0) [0|3] "" Vector__XXX
 SG_ Joystick_6_Grip_X_Axis_Lever_Lef : 2|2@1+ (1,0) [0|3] "" Vector__XXX
 SG_ Joystick_6_Grip_X_Axis_Lever_Rig : 4|2@1+ (1,0) [0|3] "" Vector__XXX
 SG_ Joystick_6_Grip_X_Axis_Position : 6|10@1+ (1,0) [0|1023] "" Vector__XXX
 SG_ Joystick_6_Grip_Y_Axis_Neutral_P : 16|2@1+ (1,0) [0|3] "" Vector__XXX
 SG_ Joystick_6_Grip_Y_Axis_Lever_Bac : 18|2@1+ (1,0) [0|3] "" Vector__XXX
 SG_ Joystick_6_Grip_Y_Axis_Lever_For : 20|2@1+ (1,0) [0|3] "" Vector__XXX
 SG_ Joystick_6_Grip_Y_Axis_Position : 22|10@1+ (1,0) [0|1023] "" Vector__XXX
 SG_ Joystick_6_Theta_Axis_Neutral_Po : 32|2@1+ (1,0) [0|3] "" Vector__XXX
 SG_ Joystick_6_Theta_Axis_Counter_Cl : 34|2@1+ (1,0) [0|3] "" Vector__XXX
 SG_ Joystick_6_Theta_Axis_Clockwise_ : 36|2@1+ (1,0) [0|3] "" Vector__XXX
 SG_ Joystick_6_Theta_Axis_Position : 38|10@1+ (1,0) [0|1023] "" Vector__XXX
 SG_ Joystick_6_Theta_Axis_Detent_Pos : 50|2@1+ (1,0) [0|3] "" Vector__XXX
 SG_ Joystick_6_Grip_Y_Axis_Detent_Po : 52|2@1+ (1,0) [0|3] "" Vector__XXX
 SG_ Joystick_6_Grip_X_Axis_Detent_Po : 54|2@1+ (1,0) [0|3] "" Vector__XXX

BO_ 2164075520 BJM6: 8 Vector__XXX
 SG_ Joystick_6_X_Axis_Neutral_Positi : 0|2@1+ (1,0) [0|3] "" Vector__XXX
 SG_ Joystick_6_X_Axis_Lever_Left_Neg : 2|2@1+ (1,0) [0|3] "" Vector__XXX
 SG_ Joystick_6_X_Axis_Lever_Right_Po : 4|2@1+ (1,0) [0|3] "" Vector__XXX
 SG_ Joystick_6_X_Axis_Position : 6|10@1+ (1,0) [0|1023] "" Vector__XXX
 SG_ Joystick_6_Y_Axis_Neutral_Positi : 16|2@1+ (1,0) [0|3] "" Vector__XXX
 SG_ Joystick_6_Y_Axis_Lever_Back_Neg : 18|2@1+ (1,0) [0|3] "" Vector__XXX
 SG_ Joystick_6_Y_Axis_Lever_Forward_ : 20|2@1+ (1,0) [0|3] "" Vector__XXX
 SG_ Joystick_6_Y_Axis_Position : 22|10@1+ (1,0) [0|1023] "" Vector__XXX
 SG_ Joystick_6_Y_Axis_Detent_Positio : 36|2@1+ (1,0) [0|3] "" Vector__XXX
 SG_ Joystick_6_X_Axis_Detent_Positio : 38|2@1+ (1,0) [0|3] "" Vector__XXX
 SG_ Joystick_6_Button_4_Pressed_Stat : 40|2@1+ (1,0) [0|3] "" Vector__XXX
 SG_ Joystick_6_Button_3_Pressed_Stat : 42|2@1+ (1,0) [0|3] "" Vector__XXX
 SG_ Joystick_6_Button_2_Pressed_Stat : 44|2@1+ (1,0) [0|3] "" Vector__XXX
 SG_ Joystick_6_Button_1_Pressed_Stat : 46|2@1+ (1,0) [0|3] "" Vector__XXX
 SG_ Joystick_6_Button_8_Pressed_Stat : 48|2@1+ (1,0) [0|3] "" Vector__XXX
 SG_ Joystick_6_Button_7_Pressed_Stat : 50|2@1+ (1,0) [0|3] "" Vector__XXX
 SG_ Joystick_6_Button_6_Pressed_Stat : 52|2@1+ (1,0) [0|3] "" Vector__XXX
 SG_ Joystick_6_Button_5_Pressed_Stat : 54|2@1+ (1,0) [0|3] "" Vector__XXX
 SG_ Joystick_6_Button_12_Pressed_Sta : 56|2@1+ (1,0) [0|3] "" Vector__XXX
 SG_ Joystick_6_Button_11_Pressed_Sta : 58|2@1+ (1,0) [0|3] "" Vector__XXX
 SG_ Joystick_6_Button_10_Pressed_Sta : 60|2@1+ (1,0) [0|3] "" Vector__XXX
 SG_ Joystick_6_Button_9_Pressed_Stat : 62|2@1+ (1,0) [0|3] "" Vector__XXX

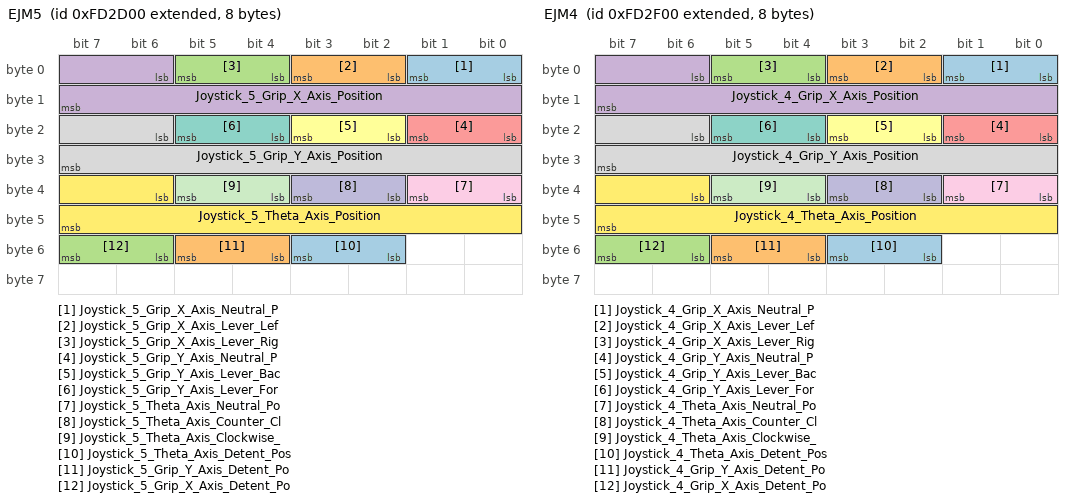
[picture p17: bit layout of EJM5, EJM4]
BO_ 2164075776 EJM5: 8 Vector__XXX
 SG_ Joystick_5_Grip_X_Axis_Neutral_P : 0|2@1+ (1,0) [0|3] "" Vector__XXX
 SG_ Joystick_5_Grip_X_Axis_Lever_Lef : 2|2@1+ (1,0) [0|3] "" Vector__XXX
 SG_ Joystick_5_Grip_X_Axis_Lever_Rig : 4|2@1+ (1,0) [0|3] "" Vector__XXX
 SG_ Joystick_5_Grip_X_Axis_Position : 6|10@1+ (1,0) [0|1023] "" Vector__XXX
 SG_ Joystick_5_Grip_Y_Axis_Neutral_P : 16|2@1+ (1,0) [0|3] "" Vector__XXX
 SG_ Joystick_5_Grip_Y_Axis_Lever_Bac : 18|2@1+ (1,0) [0|3] "" Vector__XXX
 SG_ Joystick_5_Grip_Y_Axis_Lever_For : 20|2@1+ (1,0) [0|3] "" Vector__XXX
 SG_ Joystick_5_Grip_Y_Axis_Position : 22|10@1+ (1,0) [0|1023] "" Vector__XXX
 SG_ Joystick_5_Theta_Axis_Neutral_Po : 32|2@1+ (1,0) [0|3] "" Vector__XXX
 SG_ Joystick_5_Theta_Axis_Counter_Cl : 34|2@1+ (1,0) [0|3] "" Vector__XXX
 SG_ Joystick_5_Theta_Axis_Clockwise_ : 36|2@1+ (1,0) [0|3] "" Vector__XXX
 SG_ Joystick_5_Theta_Axis_Position : 38|10@1+ (1,0) [0|1023] "" Vector__XXX
 SG_ Joystick_5_Theta_Axis_Detent_Pos : 50|2@1+ (1,0) [0|3] "" Vector__XXX
 SG_ Joystick_5_Grip_Y_Axis_Detent_Po : 52|2@1+ (1,0) [0|3] "" Vector__XXX
 SG_ Joystick_5_Grip_X_Axis_Detent_Po : 54|2@1+ (1,0) [0|3] "" Vector__XXX

BO_ 2164076032 BJM5: 8 Vector__XXX
 SG_ Joystick_5_X_Axis_Neutral_Positi : 0|2@1+ (1,0) [0|3] "" Vector__XXX
 SG_ Joystick_5_X_Axis_Lever_Left_Neg : 2|2@1+ (1,0) [0|3] "" Vector__XXX
 SG_ Joystick_5_X_Axis_Lever_Right_Po : 4|2@1+ (1,0) [0|3] "" Vector__XXX
 SG_ Joystick_5_X_Axis_Position : 6|10@1+ (1,0) [0|1023] "" Vector__XXX
 SG_ Joystick_5_Y_Axis_Neutral_Positi : 16|2@1+ (1,0) [0|3] "" Vector__XXX
 SG_ Joystick_5_Y_Axis_Lever_Back_Neg : 18|2@1+ (1,0) [0|3] "" Vector__XXX
 SG_ Joystick_5_Y_Axis_Lever_Forward_ : 20|2@1+ (1,0) [0|3] "" Vector__XXX
 SG_ Joystick_5_Y_Axis_Position : 22|10@1+ (1,0) [0|1023] "" Vector__XXX
 SG_ Joystick_5_Y_Axis_Detent_Positio : 36|2@1+ (1,0) [0|3] "" Vector__XXX
 SG_ Joystick_5_X_Axis_Detent_Positio : 38|2@1+ (1,0) [0|3] "" Vector__XXX
 SG_ Joystick_5_Button_4_Pressed_Stat : 40|2@1+ (1,0) [0|3] "" Vector__XXX
 SG_ Joystick_5_Button_3_Pressed_Stat : 42|2@1+ (1,0) [0|3] "" Vector__XXX
 SG_ Joystick_5_Button_2_Pressed_Stat : 44|2@1+ (1,0) [0|3] "" Vector__XXX
 SG_ Joystick_5_Button_1_Pressed_Stat : 46|2@1+ (1,0) [0|3] "" Vector__XXX
 SG_ Joystick_5_Button_8_Pressed_Stat : 48|2@1+ (1,0) [0|3] "" Vector__XXX
 SG_ Joystick_5_Button_7_Pressed_Stat : 50|2@1+ (1,0) [0|3] "" Vector__XXX
 SG_ Joystick_5_Button_6_Pressed_Stat : 52|2@1+ (1,0) [0|3] "" Vector__XXX
 SG_ Joystick_5_Button_5_Pressed_Stat : 54|2@1+ (1,0) [0|3] "" Vector__XXX
 SG_ Joystick_5_Button_12_Pressed_Sta : 56|2@1+ (1,0) [0|3] "" Vector__XXX
 SG_ Joystick_5_Button_11_Pressed_Sta : 58|2@1+ (1,0) [0|3] "" Vector__XXX
 SG_ Joystick_5_Button_10_Pressed_Sta : 60|2@1+ (1,0) [0|3] "" Vector__XXX
 SG_ Joystick_5_Button_9_Pressed_Stat : 62|2@1+ (1,0) [0|3] "" Vector__XXX

BO_ 2164076288 EJM4: 8 Vector__XXX
 SG_ Joystick_4_Grip_X_Axis_Neutral_P : 0|2@1+ (1,0) [0|3] "" Vector__XXX
 SG_ Joystick_4_Grip_X_Axis_Lever_Lef : 2|2@1+ (1,0) [0|3] "" Vector__XXX
 SG_ Joystick_4_Grip_X_Axis_Lever_Rig : 4|2@1+ (1,0) [0|3] "" Vector__XXX
 SG_ Joystick_4_Grip_X_Axis_Position : 6|10@1+ (1,0) [0|1023] "" Vector__XXX
 SG_ Joystick_4_Grip_Y_Axis_Neutral_P : 16|2@1+ (1,0) [0|3] "" Vector__XXX
 SG_ Joystick_4_Grip_Y_Axis_Lever_Bac : 18|2@1+ (1,0) [0|3] "" Vector__XXX
 SG_ Joystick_4_Grip_Y_Axis_Lever_For : 20|2@1+ (1,0) [0|3] "" Vector__XXX
 SG_ Joystick_4_Grip_Y_Axis_Position : 22|10@1+ (1,0) [0|1023] "" Vector__XXX
 SG_ Joystick_4_Theta_Axis_Neutral_Po : 32|2@1+ (1,0) [0|3] "" Vector__XXX
 SG_ Joystick_4_Theta_Axis_Counter_Cl : 34|2@1+ (1,0) [0|3] "" Vector__XXX
 SG_ Joystick_4_Theta_Axis_Clockwise_ : 36|2@1+ (1,0) [0|3] "" Vector__XXX
 SG_ Joystick_4_Theta_Axis_Position : 38|10@1+ (1,0) [0|1023] "" Vector__XXX
 SG_ Joystick_4_Theta_Axis_Detent_Pos : 50|2@1+ (1,0) [0|3] "" Vector__XXX
 SG_ Joystick_4_Grip_Y_Axis_Detent_Po : 52|2@1+ (1,0) [0|3] "" Vector__XXX
 SG_ Joystick_4_Grip_X_Axis_Detent_Po : 54|2@1+ (1,0) [0|3] "" Vector__XXX

BO_ 2164076544 BJM4: 8 Vector__XXX
 SG_ Joystick_4_X_Axis_Neutral_Positi : 0|2@1+ (1,0) [0|3] "" Vector__XXX
 SG_ Joystick_4_X_Axis_Lever_Left_Neg : 2|2@1+ (1,0) [0|3] "" Vector__XXX
 SG_ Joystick_4_X_Axis_Lever_Right_Po : 4|2@1+ (1,0) [0|3] "" Vector__XXX
 SG_ Joystick_4_X_Axis_Position : 6|10@1+ (1,0) [0|1023] "" Vector__XXX
 SG_ Joystick_4_Y_Axis_Neutral_Positi : 16|2@1+ (1,0) [0|3] "" Vector__XXX
 SG_ Joystick_4_Y_Axis_Lever_Back_Neg : 18|2@1+ (1,0) [0|3] "" Vector__XXX
 SG_ Joystick_4_Y_Axis_Lever_Forward_ : 20|2@1+ (1,0) [0|3] "" Vector__XXX
 SG_ Joystick_4_Y_Axis_Position : 22|10@1+ (1,0) [0|1023] "" Vector__XXX
 SG_ Joystick_4_Y_Axis_Detent_Positio : 36|2@1+ (1,0) [0|3] "" Vector__XXX
 SG_ Joystick_4_X_Axis_Detent_Positio : 38|2@1+ (1,0) [0|3] "" Vector__XXX
 SG_ Joystick_4_Button_4_Pressed_Stat : 40|2@1+ (1,0) [0|3] "" Vector__XXX
 SG_ Joystick_4_Button_3_Pressed_Stat : 42|2@1+ (1,0) [0|3] "" Vector__XXX
 SG_ Joystick_4_Button_2_Pressed_Stat : 44|2@1+ (1,0) [0|3] "" Vector__XXX
 SG_ Joystick_4_Button_1_Pressed_Stat : 46|2@1+ (1,0) [0|3] "" Vector__XXX
 SG_ Joystick_4_Button_8_Pressed_Stat : 48|2@1+ (1,0) [0|3] "" Vector__XXX
 SG_ Joystick_4_Button_7_Pressed_Stat : 50|2@1+ (1,0) [0|3] "" Vector__XXX
 SG_ Joystick_4_Button_6_Pressed_Stat : 52|2@1+ (1,0) [0|3] "" Vector__XXX
 SG_ Joystick_4_Button_5_Pressed_Stat : 54|2@1+ (1,0) [0|3] "" Vector__XXX
 SG_ Joystick_4_Button_12_Pressed_Sta : 56|2@1+ (1,0) [0|3] "" Vector__XXX
 SG_ Joystick_4_Button_11_Pressed_Sta : 58|2@1+ (1,0) [0|3] "" Vector__XXX
 SG_ Joystick_4_Button_10_Pressed_Sta : 60|2@1+ (1,0) [0|3] "" Vector__XXX
 SG_ Joystick_4_Button_9_Pressed_Stat : 62|2@1+ (1,0) [0|3] "" Vector__XXX

BO_ 2164076800 JLCM: 8 Vector__XXX
 SG_ Joystick_1_Lamp_1_Command : 0|2@1+ (1,0) [0|3] "" Vector__XXX
 SG_ Joystick_1_Lamp_2_Command : 2|2@1+ (1,0) [0|3] "" Vector__XXX
 SG_ Joystick_1_Lamp_3_Command : 4|2@1+ (1,0) [0|3] "" Vector__XXX
 SG_ Joystick_1_Lamp_4_Command : 6|2@1+ (1,0) [0|3] "" Vector__XXX
 SG_ Joystick_1_Lamp_5_Command : 8|2@1+ (1,0) [0|3] "" Vector__XXX
 SG_ Joystick_1_Lamp_6_Command : 10|2@1+ (1,0) [0|3] "" Vector__XXX
 SG_ Joystick_1_Lamp_7_Command : 12|2@1+ (1,0) [0|3] "" Vector__XXX
 SG_ Joystick_1_Lamp_8_Command : 14|2@1+ (1,0) [0|3] "" Vector__XXX
 SG_ Joystick_1_Lamp_9_Command : 16|2@1+ (1,0) [0|3] "" Vector__XXX
 SG_ Joystick_1_Lamp_10_Command : 18|2@1+ (1,0) [0|3] "" Vector__XXX
 SG_ Joystick_2_Lamp_1_Command : 20|2@1+ (1,0) [0|3] "" Vector__XXX
 SG_ Joystick_2_Lamp_2_Command : 22|2@1+ (1,0) [0|3] "" Vector__XXX
 SG_ Joystick_2_Lamp_3_Command : 24|2@1+ (1,0) [0|3] "" Vector__XXX
 SG_ Joystick_2_Lamp_4_Command : 26|2@1+ (1,0) [0|3] "" Vector__XXX
 SG_ Joystick_2_Lamp_5_Command : 28|2@1+ (1,0) [0|3] "" Vector__XXX
 SG_ Joystick_2_Lamp_6_Command : 30|2@1+ (1,0) [0|3] "" Vector__XXX
 SG_ Joystick_2_Lamp_7_Command : 32|2@1+ (1,0) [0|3] "" Vector__XXX
 SG_ Joystick_2_Lamp_8_Command : 34|2@1+ (1,0) [0|3] "" Vector__XXX
 SG_ Joystick_2_Lamp_9_Command : 36|2@1+ (1,0) [0|3] "" Vector__XXX
 SG_ Joystick_2_Lamp_10_Command : 38|2@1+ (1,0) [0|3] "" Vector__XXX
 SG_ Joystick_3_Lamp_1_Command : 40|2@1+ (1,0) [0|3] "" Vector__XXX
 SG_ Joystick_3_Lamp_2_Command : 42|2@1+ (1,0) [0|3] "" Vector__XXX
 SG_ Joystick_3_Lamp_3_Command : 44|2@1+ (1,0) [0|3] "" Vector__XXX
 SG_ Joystick_3_Lamp_4_Command : 46|2@1+ (1,0) [0|3] "" Vector__XXX
 SG_ Joystick_3_Lamp_5_Command : 48|2@1+ (1,0) [0|3] "" Vector__XXX
 SG_ Joystick_3_Lamp_6_Command : 50|2@1+ (1,0) [0|3] "" Vector__XXX
 SG_ Joystick_3_Lamp_7_Command : 52|2@1+ (1,0) [0|3] "" Vector__XXX
 SG_ Joystick_3_Lamp_8_Command : 54|2@1+ (1,0) [0|3] "" Vector__XXX
 SG_ Joystick_3_Lamp_9_Command : 56|2@1+ (1,0) [0|3] "" Vector__XXX
 SG_ Joystick_3_Lamp_10_Command : 58|2@1+ (1,0) [0|3] "" Vector__XXX

BO_ 2164077312 A2SCRRSI: 8 Vector__XXX
 SG_ Aftertreatment_2_SCR_Catalyst_Re0 : 0|16@1+ (1,0) [0|65535] "" Vector__XXX
 SG_ Aftertreatment_2_SCR_Catalyst_Re1 : 16|8@1+ (1,0) [0|255] "" Vector__XXX
 SG_ Aftertreatment_2_SCR_Catalyst_Re2 : 24|8@1+ (1,0) [0|255] "" Vector__XXX

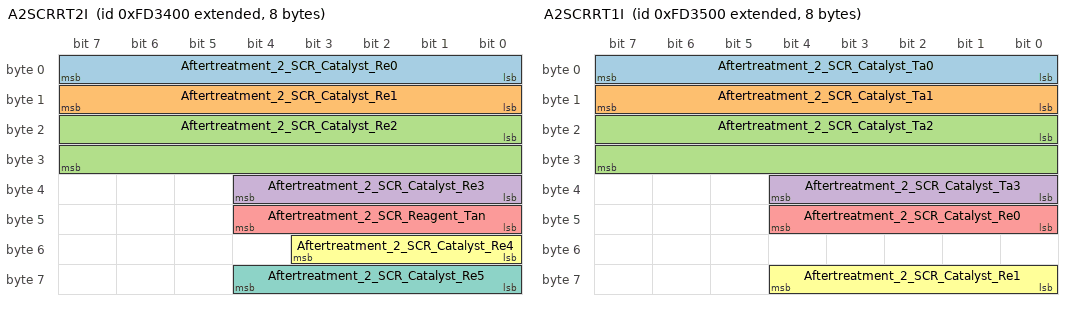
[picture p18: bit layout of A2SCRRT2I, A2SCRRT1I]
BO_ 2164077568 A2SCRRT2I: 8 Vector__XXX
 SG_ Aftertreatment_2_SCR_Catalyst_Re0 : 0|8@1+ (1,0) [0|255] "" Vector__XXX
 SG_ Aftertreatment_2_SCR_Catalyst_Re1 : 8|8@1+ (1,0) [0|255] "" Vector__XXX
 SG_ Aftertreatment_2_SCR_Catalyst_Re2 : 16|16@1+ (1,0) [0|65535] "" Vector__XXX
 SG_ Aftertreatment_2_SCR_Catalyst_Re3 : 32|5@1+ (1,0) [0|31] "" Vector__XXX
 SG_ Aftertreatment_2_SCR_Reagent_Tan : 40|5@1+ (1,0) [0|31] "" Vector__XXX
 SG_ Aftertreatment_2_SCR_Catalyst_Re4 : 48|4@1+ (1,0) [0|15] "" Vector__XXX
 SG_ Aftertreatment_2_SCR_Catalyst_Re5 : 56|5@1+ (1,0) [0|31] "" Vector__XXX

BO_ 2164077824 A2SCRRT1I: 8 Vector__XXX
 SG_ Aftertreatment_2_SCR_Catalyst_Ta0 : 0|8@1+ (1,0) [0|255] "" Vector__XXX
 SG_ Aftertreatment_2_SCR_Catalyst_Ta1 : 8|8@1+ (1,0) [0|255] "" Vector__XXX
 SG_ Aftertreatment_2_SCR_Catalyst_Ta2 : 16|16@1+ (1,0) [0|65535] "" Vector__XXX
 SG_ Aftertreatment_2_SCR_Catalyst_Ta3 : 32|5@1+ (1,0) [0|31] "" Vector__XXX
 SG_ Aftertreatment_2_SCR_Catalyst_Re0 : 40|5@1+ (1,0) [0|31] "" Vector__XXX
 SG_ Aftertreatment_2_SCR_Catalyst_Re1 : 56|5@1+ (1,0) [0|31] "" Vector__XXX

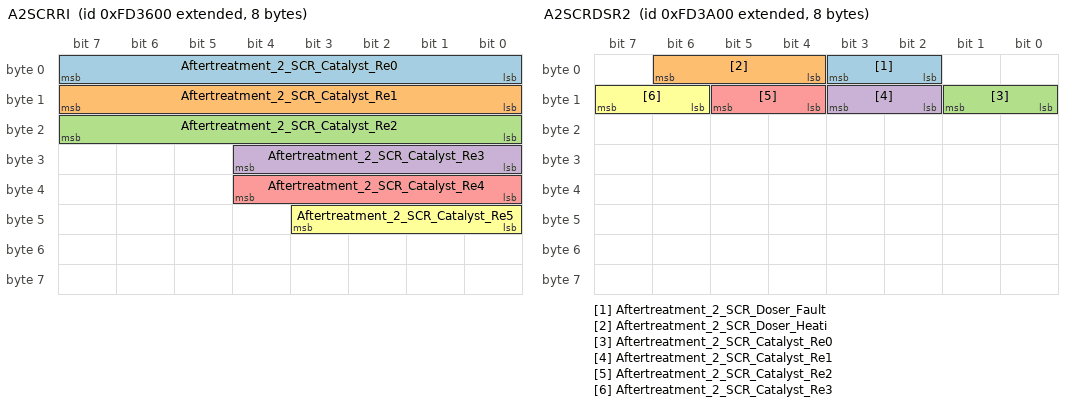
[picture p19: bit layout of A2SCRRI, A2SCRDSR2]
BO_ 2164078080 A2SCRRI: 8 Vector__XXX
 SG_ Aftertreatment_2_SCR_Catalyst_Re0 : 0|8@1+ (1,0) [0|255] "" Vector__XXX
 SG_ Aftertreatment_2_SCR_Catalyst_Re1 : 8|8@1+ (1,0) [0|255] "" Vector__XXX
 SG_ Aftertreatment_2_SCR_Catalyst_Re2 : 16|8@1+ (1,0) [0|255] "" Vector__XXX
 SG_ Aftertreatment_2_SCR_Catalyst_Re3 : 24|5@1+ (1,0) [0|31] "" Vector__XXX
 SG_ Aftertreatment_2_SCR_Catalyst_Re4 : 32|5@1+ (1,0) [0|31] "" Vector__XXX
 SG_ Aftertreatment_2_SCR_Catalyst_Re5 : 40|4@1+ (1,0) [0|15] "" Vector__XXX

BO_ 2164078336 A2SCRSI: 8 Vector__XXX
 SG_ Aftertreatment_2_SCR_Average_Cat : 0|16@1+ (1,0) [0|65535] "" Vector__XXX
 SG_ Aftertreatment_2_SCR_Commanded_C : 16|16@1+ (1,0) [0|65535] "" Vector__XXX
 SG_ Aftertreatment_2_SCR_Catalyst_Co : 32|8@1+ (1,0) [0|255] "" Vector__XXX

BO_ 2164078592 A2SCREGT: 8 Vector__XXX
 SG_ Aftertreatment_2_SCR_Catalyst_In0 : 0|16@1+ (1,0) [0|65535] "" Vector__XXX
 SG_ Aftertreatment_2_SCR_Catalyst_In1 : 16|5@1+ (1,0) [0|31] "" Vector__XXX
 SG_ Aftertreatment_2_SCR_Catalyst_Ou0 : 24|16@1+ (1,0) [0|65535] "" Vector__XXX
 SG_ Aftertreatment_2_SCR_Catalyst_Ou1 : 40|5@1+ (1,0) [0|31] "" Vector__XXX

BO_ 2164078848 A2SCREGP: 8 Vector__XXX
 SG_ Aftertreatment_2_SCR_Catalyst_Ex0 : 0|16@1+ (1,0) [0|65535] "" Vector__XXX
 SG_ Aftertreatment_2_SCR_Catalyst_Ex1 : 16|5@1+ (1,0) [0|31] "" Vector__XXX

BO_ 2164079104 A2SCRDSR2: 8 Vector__XXX
 SG_ Aftertreatment_2_SCR_Doser_Fault : 2|2@1+ (1,0) [0|3] "" Vector__XXX
 SG_ Aftertreatment_2_SCR_Doser_Heati : 4|3@1+ (1,0) [0|7] "" Vector__XXX
 SG_ Aftertreatment_2_SCR_Catalyst_Re0 : 8|2@1+ (1,0) [0|3] "" Vector__XXX
 SG_ Aftertreatment_2_SCR_Catalyst_Re1 : 10|2@1+ (1,0) [0|3] "" Vector__XXX
 SG_ Aftertreatment_2_SCR_Catalyst_Re2 : 12|2@1+ (1,0) [0|3] "" Vector__XXX
 SG_ Aftertreatment_2_SCR_Catalyst_Re3 : 14|2@1+ (1,0) [0|3] "" Vector__XXX

BA_DEF_ BO_ "VFrameFormat" ENUM "StandardCAN","ExtendedCAN","StandardCAN_FD","ExtendedCAN_FD","J1939PG";
BA_DEF_ SG_ "SPN" INT 0 524287;
BA_DEF_ SG_ "SystemSignalLongSymbol" STRING;
BA_DEF_  "ProtocolType" STRING;

BA_ "ProtocolType"   "J1939";

BA_ "VFrameFormat" BO_ 2147483648 4;
BA_ "VFrameFormat" BO_ 2147549184 4;
BA_ "VFrameFormat" BO_ 2147745792 4;
BA_ "VFrameFormat" BO_ 2147942400 4;
BA_ "VFrameFormat" BO_ 2148007936 4;
BA_ "VFrameFormat" BO_ 2157641728 4;
BA_ "VFrameFormat" BO_ 2157707264 4;
BA_ "VFrameFormat" BO_ 2157772800 4;
BA_ "VFrameFormat" BO_ 2158297088 4;
BA_ "VFrameFormat" BO_ 2158362624 4;
BA_ "VFrameFormat" BO_ 2158428160 4;
BA_ "VFrameFormat" BO_ 2158493696 4;
BA_ "VFrameFormat" BO_ 2158559232 4;
BA_ "VFrameFormat" BO_ 2158886912 4;
BA_ "VFrameFormat" BO_ 2161049600 4;
BA_ "VFrameFormat" BO_ 2161115136 4;
BA_ "VFrameFormat" BO_ 2161180672 4;
BA_ "VFrameFormat" BO_ 2161246208 4;
BA_ "VFrameFormat" BO_ 2161442816 4;
BA_ "VFrameFormat" BO_ 2161901568 4;
BA_ "VFrameFormat" BO_ 2161967104 4;
BA_ "VFrameFormat" BO_ 2162032640 4;
BA_ "VFrameFormat" BO_ 2162163712 4;
BA_ "VFrameFormat" BO_ 2163212288 4;
BA_ "VFrameFormat" BO_ 2163212544 4;
BA_ "VFrameFormat" BO_ 2163212800 4;
BA_ "VFrameFormat" BO_ 2163213056 4;
BA_ "VFrameFormat" BO_ 2163213312 4;
BA_ "VFrameFormat" BO_ 2163213568 4;
BA_ "VFrameFormat" BO_ 2163213824 4;
BA_ "VFrameFormat" BO_ 2163214080 4;
BA_ "VFrameFormat" BO_ 2163214336 4;
BA_ "VFrameFormat" BO_ 2163214592 4;
BA_ "VFrameFormat" BO_ 2163214848 4;
BA_ "VFrameFormat" BO_ 2163215104 4;
BA_ "VFrameFormat" BO_ 2163215360 4;
BA_ "VFrameFormat" BO_ 2163215616 4;
BA_ "VFrameFormat" BO_ 2163215872 4;
BA_ "VFrameFormat" BO_ 2163216128 4;
BA_ "VFrameFormat" BO_ 2163216384 4;
BA_ "VFrameFormat" BO_ 2163216640 4;
BA_ "VFrameFormat" BO_ 2163216896 4;
BA_ "VFrameFormat" BO_ 2163217152 4;
BA_ "VFrameFormat" BO_ 2163217408 4;
BA_ "VFrameFormat" BO_ 2163217920 4;
BA_ "VFrameFormat" BO_ 2163218176 4;
BA_ "VFrameFormat" BO_ 2163218432 4;
BA_ "VFrameFormat" BO_ 2163218688 4;
BA_ "VFrameFormat" BO_ 2163218944 4;
BA_ "VFrameFormat" BO_ 2163219712 4;
BA_ "VFrameFormat" BO_ 2163220736 4;
BA_ "VFrameFormat" BO_ 2163221248 4;
BA_ "VFrameFormat" BO_ 2163221504 4;
BA_ "VFrameFormat" BO_ 2163221760 4;
BA_ "VFrameFormat" BO_ 2163222016 4;
BA_ "VFrameFormat" BO_ 2163222272 4;
BA_ "VFrameFormat" BO_ 2163222528 4;
BA_ "VFrameFormat" BO_ 2164073216 4;
BA_ "VFrameFormat" BO_ 2164073472 4;
BA_ "VFrameFormat" BO_ 2164073728 4;
BA_ "VFrameFormat" BO_ 2164073984 4;
BA_ "VFrameFormat" BO_ 2164074240 4;
BA_ "VFrameFormat" BO_ 2164074496 4;
BA_ "VFrameFormat" BO_ 2164074752 4;
BA_ "VFrameFormat" BO_ 2164075008 4;
BA_ "VFrameFormat" BO_ 2164075264 4;
BA_ "VFrameFormat" BO_ 2164075520 4;
BA_ "VFrameFormat" BO_ 2164075776 4;
BA_ "VFrameFormat" BO_ 2164076032 4;
BA_ "VFrameFormat" BO_ 2164076288 4;
BA_ "VFrameFormat" BO_ 2164076544 4;
BA_ "VFrameFormat" BO_ 2164076800 4;
BA_ "VFrameFormat" BO_ 2164077312 4;
BA_ "VFrameFormat" BO_ 2164077568 4;
BA_ "VFrameFormat" BO_ 2164077824 4;
BA_ "VFrameFormat" BO_ 2164078080 4;
BA_ "VFrameFormat" BO_ 2164078336 4;
BA_ "VFrameFormat" BO_ 2164078592 4;
BA_ "VFrameFormat" BO_ 2164078848 4;
BA_ "VFrameFormat" BO_ 2164079104 4;

BA_ "SPN" SG_ 2147483648 Engine_Override_Control_Mode 695;
BA_ "SPN" SG_ 2147483648 Engine_Requested_Speed_Control_C 696;
BA_ "SystemSignalLongSymbol" SG_ 2147483648 Engine_Requested_Speed_Control_C "Engine Requested Speed Control Conditions";
BA_ "SPN" SG_ 2147483648 Override_Control_Mode_Priority 897;
BA_ "SPN" SG_ 2147483648 Engine_Requested_Speed_Speed_Lim 898;
BA_ "SystemSignalLongSymbol" SG_ 2147483648 Engine_Requested_Speed_Speed_Lim "Engine Requested Speed/Speed Limit";
BA_ "SPN" SG_ 2147483648 Engine_Requested_Torque_Torque_L 518;
BA_ "SystemSignalLongSymbol" SG_ 2147483648 Engine_Requested_Torque_Torque_L "Engine Requested Torque/Torque Limit";
BA_ "SPN" SG_ 2147483648 TSC1_Transmission_Rate 3349;
BA_ "SPN" SG_ 2147483648 TSC1_Control_Purpose 3350;
BA_ "SPN" SG_ 2147483648 Engine_Requested_Torque___High_ 4191;
BA_ "SystemSignalLongSymbol" SG_ 2147483648 Engine_Requested_Torque___High_ "Engine Requested Torque -  High Resolution";
BA_ "SPN" SG_ 2147483648 Message_Counter 4206;
BA_ "SPN" SG_ 2147483648 Message_Checksum 4207;
BA_ "SPN" SG_ 2147549184 Transmission_Gear_Shift_Inhibit_ 681;
BA_ "SystemSignalLongSymbol" SG_ 2147549184 Transmission_Gear_Shift_Inhibit_ "Transmission Gear Shift Inhibit Request";
BA_ "SPN" SG_ 2147549184 Transmission_Torque_Converter_Lo 682;
BA_ "SystemSignalLongSymbol" SG_ 2147549184 Transmission_Torque_Converter_Lo "Transmission Torque Converter Lockup Disable Request";
BA_ "SPN" SG_ 2147549184 Disengage_Driveline_Request 683;
BA_ "SPN" SG_ 2147549184 Transmission_Reverse_Gear_Shift_ 4242;
BA_ "SystemSignalLongSymbol" SG_ 2147549184 Transmission_Reverse_Gear_Shift_ "Transmission Reverse Gear Shift Inhibit Request";
BA_ "SPN" SG_ 2147549184 Requested_Percent_Clutch_Slip 684;
BA_ "SPN" SG_ 2147549184 Transmission_Requested_Gear 525;
BA_ "SPN" SG_ 2147549184 Disengage_Differential_Lock_Requ0 685;
BA_ "SystemSignalLongSymbol" SG_ 2147549184 Disengage_Differential_Lock_Requ0 "Disengage Differential Lock Request - Front Axle 1";
BA_ "SPN" SG_ 2147549184 Disengage_Differential_Lock_Requ1 686;
BA_ "SystemSignalLongSymbol" SG_ 2147549184 Disengage_Differential_Lock_Requ1 "Disengage Differential Lock Request - Front Axle 2";
BA_ "SPN" SG_ 2147549184 Disengage_Differential_Lock_Requ2 687;
BA_ "SystemSignalLongSymbol" SG_ 2147549184 Disengage_Differential_Lock_Requ2 "Disengage Differential Lock Request - Rear Axle 1";
BA_ "SPN" SG_ 2147549184 Disengage_Differential_Lock_Requ3 688;
BA_ "SystemSignalLongSymbol" SG_ 2147549184 Disengage_Differential_Lock_Requ3 "Disengage Differential Lock Request - Rear Axle 2";
BA_ "SPN" SG_ 2147549184 Disengage_Differential_Lock_Requ4 689;
BA_ "SystemSignalLongSymbol" SG_ 2147549184 Disengage_Differential_Lock_Requ4 "Disengage Differential Lock Request - Central";
BA_ "SPN" SG_ 2147549184 Disengage_Differential_Lock_Requ5 690;
BA_ "SystemSignalLongSymbol" SG_ 2147549184 Disengage_Differential_Lock_Requ5 "Disengage Differential Lock Request - Central Front";
BA_ "SPN" SG_ 2147549184 Disengage_Differential_Lock_Requ6 691;
BA_ "SystemSignalLongSymbol" SG_ 2147549184 Disengage_Differential_Lock_Requ6 "Disengage Differential Lock Request - Central Rear";
BA_ "SPN" SG_ 2147549184 Transmission_Mode_1 1852;
BA_ "SPN" SG_ 2147549184 Transmission_Mode_2 1853;
BA_ "SPN" SG_ 2147549184 Transmission_Mode_3 1854;
BA_ "SPN" SG_ 2147549184 Transmission_Mode_4 1855;
BA_ "SPN" SG_ 2147549184 Transmission_Requested_Launch_Ge 4255;
BA_ "SystemSignalLongSymbol" SG_ 2147549184 Transmission_Requested_Launch_Ge "Transmission Requested Launch Gear";
BA_ "SPN" SG_ 2147549184 Transmission_Shift_Selector_Disp 2985;
BA_ "SystemSignalLongSymbol" SG_ 2147549184 Transmission_Shift_Selector_Disp "Transmission Shift Selector Display Mode Switch";
BA_ "SPN" SG_ 2147549184 Transmission_Mode_5 4246;
BA_ "SPN" SG_ 2147549184 Transmission_Mode_6 4247;
BA_ "SPN" SG_ 2147549184 Transmission_Mode_7 4248;
BA_ "SPN" SG_ 2147549184 Transmission_Mode_8 4249;
BA_ "SPN" SG_ 2147745792 External_Acceleration_Demand 2920;
BA_ "SPN" SG_ 2147745792 XBR_EBI_Mode 2914;
BA_ "SPN" SG_ 2147745792 XBR_Priority 2915;
BA_ "SPN" SG_ 2147745792 XBR_Control_Mode 2916;
BA_ "SPN" SG_ 2147745792 XBR_urgency 4099;
BA_ "SPN" SG_ 2147745792 XBR_Message_Counter 3189;
BA_ "SPN" SG_ 2147745792 XBR_Message_Checksum 3188;
BA_ "SPN" SG_ 2147942400 Valve_Load_Sense_Pressure 4086;
BA_ "SPN" SG_ 2147942400 Valve_Pilot_Pressure 4087;
BA_ "SPN" SG_ 2147942400 Valve_Assembly_Load_sense_Pressu 4088;
BA_ "SystemSignalLongSymbol" SG_ 2147942400 Valve_Assembly_Load_sense_Pressu "Valve Assembly Load sense Pressure";
BA_ "SPN" SG_ 2147942400 Valve_Assembly_Supply_Pressure 4089;
BA_ "SPN" SG_ 2148007936 Auxiliary_I_O_Channel__6 4155;
BA_ "SPN" SG_ 2148007936 Auxiliary_I_O_Channel__5 4156;
BA_ "SPN" SG_ 2148007936 Auxiliary_I_O_Channel__4 4157;
BA_ "SPN" SG_ 2148007936 Auxiliary_I_O_Channel__3 4158;
BA_ "SPN" SG_ 2157641728 Data_Dictionary_Manufacturer_Cod 4180;
BA_ "SystemSignalLongSymbol" SG_ 2157641728 Data_Dictionary_Manufacturer_Cod "Data Dictionary Manufacturer Code";
BA_ "SPN" SG_ 2157641728 Data_Dictionary_Method 4181;
BA_ "SPN" SG_ 2157707264 Auxiliary_I_O_Channel__18 4167;
BA_ "SPN" SG_ 2157707264 Auxiliary_I_O_Channel__17 4168;
BA_ "SPN" SG_ 2157707264 Auxiliary_I_O_Channel__16 4169;
BA_ "SPN" SG_ 2157707264 Auxiliary_I_O_Channel__15 4170;
BA_ "SPN" SG_ 2157707264 Auxiliary_I_O_Channel__22 4171;
BA_ "SPN" SG_ 2157707264 Auxiliary_I_O_Channel__21 4172;
BA_ "SPN" SG_ 2157707264 Auxiliary_I_O_Channel__20 4173;
BA_ "SPN" SG_ 2157707264 Auxiliary_I_O_Channel__19 4174;
BA_ "SPN" SG_ 2157772800 Auxiliary_I_O_Channel__10 4159;
BA_ "SPN" SG_ 2157772800 Auxiliary_I_O_Channel__9 4160;
BA_ "SPN" SG_ 2157772800 Auxiliary_I_O_Channel__8 4161;
BA_ "SPN" SG_ 2157772800 Auxiliary_I_O_Channel__7 4162;
BA_ "SPN" SG_ 2157772800 Auxiliary_I_O_Channel__14 4163;
BA_ "SPN" SG_ 2157772800 Auxiliary_I_O_Channel__13 4164;
BA_ "SPN" SG_ 2157772800 Auxiliary_I_O_Channel__12 4165;
BA_ "SPN" SG_ 2157772800 Auxiliary_I_O_Channel__11 4166;
BA_ "SPN" SG_ 2158297088 Auxiliary_I_O__84 3907;
BA_ "SPN" SG_ 2158297088 Auxiliary_I_O__83 3906;
BA_ "SPN" SG_ 2158297088 Auxiliary_I_O__82 3905;
BA_ "SPN" SG_ 2158297088 Auxiliary_I_O__81 3904;
BA_ "SPN" SG_ 2158297088 Auxiliary_I_O__88 3911;
BA_ "SPN" SG_ 2158297088 Auxiliary_I_O__87 3910;
BA_ "SPN" SG_ 2158297088 Auxiliary_I_O__86 3909;
BA_ "SPN" SG_ 2158297088 Auxiliary_I_O__85 3908;
BA_ "SPN" SG_ 2158297088 Auxiliary_I_O__92 3915;
BA_ "SPN" SG_ 2158297088 Auxiliary_I_O__91 3914;
BA_ "SPN" SG_ 2158297088 Auxiliary_I_O__90 3913;
BA_ "SPN" SG_ 2158297088 Auxiliary_I_O__89 3912;
BA_ "SPN" SG_ 2158297088 Auxiliary_I_O__96 3919;
BA_ "SPN" SG_ 2158297088 Auxiliary_I_O__95 3918;
BA_ "SPN" SG_ 2158297088 Auxiliary_I_O__94 3917;
BA_ "SPN" SG_ 2158297088 Auxiliary_I_O__93 3916;
BA_ "SPN" SG_ 2158297088 Auxiliary_I_O__100 3923;
BA_ "SPN" SG_ 2158297088 Auxiliary_I_O__99 3922;
BA_ "SPN" SG_ 2158297088 Auxiliary_I_O__98 3921;
BA_ "SPN" SG_ 2158297088 Auxiliary_I_O__97 3920;
BA_ "SPN" SG_ 2158297088 Auxiliary_I_O__104 3927;
BA_ "SPN" SG_ 2158297088 Auxiliary_I_O__103 3926;
BA_ "SPN" SG_ 2158297088 Auxiliary_I_O__102 3925;
BA_ "SPN" SG_ 2158297088 Auxiliary_I_O__101 3924;
BA_ "SPN" SG_ 2158297088 Auxiliary_I_O__108 3931;
BA_ "SPN" SG_ 2158297088 Auxiliary_I_O__107 3930;
BA_ "SPN" SG_ 2158297088 Auxiliary_I_O__106 3929;
BA_ "SPN" SG_ 2158297088 Auxiliary_I_O__105 3928;
BA_ "SPN" SG_ 2158297088 Auxiliary_I_O__112 3935;
BA_ "SPN" SG_ 2158297088 Auxiliary_I_O__111 3934;
BA_ "SPN" SG_ 2158297088 Auxiliary_I_O__110 3933;
BA_ "SPN" SG_ 2158297088 Auxiliary_I_O__109 3932;
BA_ "SPN" SG_ 2158362624 Auxiliary_I_O__52 3875;
BA_ "SPN" SG_ 2158362624 Auxiliary_I_O__51 3874;
BA_ "SPN" SG_ 2158362624 Auxiliary_I_O__50 3873;
BA_ "SPN" SG_ 2158362624 Auxiliary_I_O__49 3872;
BA_ "SPN" SG_ 2158362624 Auxiliary_I_O__56 3879;
BA_ "SPN" SG_ 2158362624 Auxiliary_I_O__55 3878;
BA_ "SPN" SG_ 2158362624 Auxiliary_I_O__54 3877;
BA_ "SPN" SG_ 2158362624 Auxiliary_I_O__53 3876;
BA_ "SPN" SG_ 2158362624 Auxiliary_I_O__60 3883;
BA_ "SPN" SG_ 2158362624 Auxiliary_I_O__59 3882;
BA_ "SPN" SG_ 2158362624 Auxiliary_I_O__58 3881;
BA_ "SPN" SG_ 2158362624 Auxiliary_I_O__57 3880;
BA_ "SPN" SG_ 2158362624 Auxiliary_I_O__64 3887;
BA_ "SPN" SG_ 2158362624 Auxiliary_I_O__63 3886;
BA_ "SPN" SG_ 2158362624 Auxiliary_I_O__62 3885;
BA_ "SPN" SG_ 2158362624 Auxiliary_I_O__61 3884;
BA_ "SPN" SG_ 2158362624 Auxiliary_I_O__68 3891;
BA_ "SPN" SG_ 2158362624 Auxiliary_I_O__67 3890;
BA_ "SPN" SG_ 2158362624 Auxiliary_I_O__66 3889;
BA_ "SPN" SG_ 2158362624 Auxiliary_I_O__65 3888;
BA_ "SPN" SG_ 2158362624 Auxiliary_I_O__72 3895;
BA_ "SPN" SG_ 2158362624 Auxiliary_I_O__71 3894;
BA_ "SPN" SG_ 2158362624 Auxiliary_I_O__70 3893;
BA_ "SPN" SG_ 2158362624 Auxiliary_I_O__69 3892;
BA_ "SPN" SG_ 2158362624 Auxiliary_I_O__76 3899;
BA_ "SPN" SG_ 2158362624 Auxiliary_I_O__75 3898;
BA_ "SPN" SG_ 2158362624 Auxiliary_I_O__74 3897;
BA_ "SPN" SG_ 2158362624 Auxiliary_I_O__73 3896;
BA_ "SPN" SG_ 2158362624 Auxiliary_I_O__80 3903;
BA_ "SPN" SG_ 2158362624 Auxiliary_I_O__79 3902;
BA_ "SPN" SG_ 2158362624 Auxiliary_I_O__78 3901;
BA_ "SPN" SG_ 2158362624 Auxiliary_I_O__77 3900;
BA_ "SPN" SG_ 2158428160 Auxiliary_I_O__20 3843;
BA_ "SPN" SG_ 2158428160 Auxiliary_I_O__19 3842;
BA_ "SPN" SG_ 2158428160 Auxiliary_I_O__18 3841;
BA_ "SPN" SG_ 2158428160 Auxiliary_I_O__17 3840;
BA_ "SPN" SG_ 2158428160 Auxiliary_I_O__24 3847;
BA_ "SPN" SG_ 2158428160 Auxiliary_I_O__23 3846;
BA_ "SPN" SG_ 2158428160 Auxiliary_I_O__22 3845;
BA_ "SPN" SG_ 2158428160 Auxiliary_I_O__21 3844;
BA_ "SPN" SG_ 2158428160 Auxiliary_I_O__28 3851;
BA_ "SPN" SG_ 2158428160 Auxiliary_I_O__27 3850;
BA_ "SPN" SG_ 2158428160 Auxiliary_I_O__26 3849;
BA_ "SPN" SG_ 2158428160 Auxiliary_I_O__25 3848;
BA_ "SPN" SG_ 2158428160 Auxiliary_I_O__32 3855;
BA_ "SPN" SG_ 2158428160 Auxiliary_I_O__31 3854;
BA_ "SPN" SG_ 2158428160 Auxiliary_I_O__30 3853;
BA_ "SPN" SG_ 2158428160 Auxiliary_I_O__29 3852;
BA_ "SPN" SG_ 2158428160 Auxiliary_I_O__36 3859;
BA_ "SPN" SG_ 2158428160 Auxiliary_I_O__35 3858;
BA_ "SPN" SG_ 2158428160 Auxiliary_I_O__34 3857;
BA_ "SPN" SG_ 2158428160 Auxiliary_I_O__33 3856;
BA_ "SPN" SG_ 2158428160 Auxiliary_I_O__40 3863;
BA_ "SPN" SG_ 2158428160 Auxiliary_I_O__39 3862;
BA_ "SPN" SG_ 2158428160 Auxiliary_I_O__38 3861;
BA_ "SPN" SG_ 2158428160 Auxiliary_I_O__37 3860;
BA_ "SPN" SG_ 2158428160 Auxiliary_I_O__44 3867;
BA_ "SPN" SG_ 2158428160 Auxiliary_I_O__43 3866;
BA_ "SPN" SG_ 2158428160 Auxiliary_I_O__42 3865;
BA_ "SPN" SG_ 2158428160 Auxiliary_I_O__41 3864;
BA_ "SPN" SG_ 2158428160 Auxiliary_I_O__48 3871;
BA_ "SPN" SG_ 2158428160 Auxiliary_I_O__47 3870;
BA_ "SPN" SG_ 2158428160 Auxiliary_I_O__46 3869;
BA_ "SPN" SG_ 2158428160 Auxiliary_I_O__45 3868;
BA_ "SPN" SG_ 2158493696 Text_Display_Instructions 3613;
BA_ "SPN" SG_ 2158493696 Text_Display_Index 3614;
BA_ "SPN" SG_ 2158493696 Text_Display_Character 3615;
BA_ "SPN" SG_ 2158559232 Lane_Departure_Warning_Enable_Co 3564;
BA_ "SystemSignalLongSymbol" SG_ 2158559232 Lane_Departure_Warning_Enable_Co "Lane Departure Warning Enable Command";
BA_ "SPN" SG_ 2158886912 Tire_Location 3192;
BA_ "SPN" SG_ 2158886912 Reference_Tire_Pressure_Setting 3193;
BA_ "SPN" SG_ 2161049600 Engine_Speed_Limit_Request___Min 1784;
BA_ "SystemSignalLongSymbol" SG_ 2161049600 Engine_Speed_Limit_Request___Min "Engine Speed Limit Request - Minimum Continuous";
BA_ "SPN" SG_ 2161049600 Engine_Speed_Limit_Request___Max 1785;
BA_ "SystemSignalLongSymbol" SG_ 2161049600 Engine_Speed_Limit_Request___Max "Engine Speed Limit Request - Maximum Continuous";
BA_ "SPN" SG_ 2161049600 Engine_Torque_Limit_Request___Mi 1786;
BA_ "SystemSignalLongSymbol" SG_ 2161049600 Engine_Torque_Limit_Request___Mi "Engine Torque Limit Request - Minimum Continuous";
BA_ "SPN" SG_ 2161049600 Engine_Torque_Limit_Request___Ma 1787;
BA_ "SystemSignalLongSymbol" SG_ 2161049600 Engine_Torque_Limit_Request___Ma "Engine Torque Limit Request - Maximum Continuous";
BA_ "SPN" SG_ 2161049600 Minimum_Continuous_Retarder_Spee 1788;
BA_ "SystemSignalLongSymbol" SG_ 2161049600 Minimum_Continuous_Retarder_Spee "Minimum Continuous Retarder Speed Limit Request";
BA_ "SPN" SG_ 2161049600 Maximum_Continuous_Retarder_Spee 1789;
BA_ "SystemSignalLongSymbol" SG_ 2161049600 Maximum_Continuous_Retarder_Spee "Maximum Continuous Retarder Speed Limit Request";
BA_ "SPN" SG_ 2161049600 Minimum_Continuous_Retarder_Torq 1790;
BA_ "SystemSignalLongSymbol" SG_ 2161049600 Minimum_Continuous_Retarder_Torq "Minimum Continuous Retarder Torque Limit Request";
BA_ "SPN" SG_ 2161049600 Maximum_Continuous_Retarder_Torq 1791;
BA_ "SystemSignalLongSymbol" SG_ 2161049600 Maximum_Continuous_Retarder_Torq "Maximum Continuous Retarder Torque Limit Request";
BA_ "SPN" SG_ 2161115136 Illumination_Brightness_Percent 1487;
BA_ "SPN" SG_ 2161180672 Level_Preset_Front_Axle_Left 1732;
BA_ "SPN" SG_ 2161180672 Level_Preset_Front_Axle_Right 1757;
BA_ "SPN" SG_ 2161180672 Level_Preset_Rear_Axle_Left 1758;
BA_ "SPN" SG_ 2161180672 Level_Preset_Rear_Axle_Right 1735;
BA_ "SPN" SG_ 2161246208 Automatic_traction_help__load_tr 2984;
BA_ "SystemSignalLongSymbol" SG_ 2161246208 Automatic_traction_help__load_tr "Automatic traction help (load transfer)";
BA_ "SPN" SG_ 2161246208 Kneeling_Request_Left_Side 1749;
BA_ "SPN" SG_ 2161246208 Kneeling_Request_Right_Side 1748;
BA_ "SPN" SG_ 2161246208 Kneeling_Control_Mode_Request 1747;
BA_ "SPN" SG_ 2161246208 Nominal_Level_Request_Front_Axle 1751;
BA_ "SPN" SG_ 2161246208 Nominal_Level_Request_Rear_Axle 1750;
BA_ "SPN" SG_ 2161246208 Level_Control_Mode_Request 1753;
BA_ "SPN" SG_ 2161246208 Lift_Axle_1_Position_Command 1752;
BA_ "SPN" SG_ 2161246208 Lift_Axle_2_Position_Command 1828;
BA_ "SPN" SG_ 2161246208 Damper_Stiffness_Request_Front_A 1718;
BA_ "SystemSignalLongSymbol" SG_ 2161246208 Damper_Stiffness_Request_Front_A "Damper Stiffness Request Front Axle";
BA_ "SPN" SG_ 2161246208 Damper_Stiffness_Request_Rear_Ax 1719;
BA_ "SystemSignalLongSymbol" SG_ 2161246208 Damper_Stiffness_Request_Rear_Ax "Damper Stiffness Request Rear Axle";
BA_ "SPN" SG_ 2161246208 Damper_Stiffness_Request_Lift___ 1720;
BA_ "SystemSignalLongSymbol" SG_ 2161246208 Damper_Stiffness_Request_Lift___ "Damper Stiffness Request Lift / Tag Axle";
BA_ "SPN" SG_ 2161246208 Kneeling_Command___Front_Axle 1830;
BA_ "SPN" SG_ 2161246208 Kneeling_Command___Rear_Axle 1829;
BA_ "SPN" SG_ 2161246208 Prohibit_air_suspension_control 3215;
BA_ "SPN" SG_ 2161442816 Adjust_seconds 1603;
BA_ "SPN" SG_ 2161442816 Adjust_minutes 1604;
BA_ "SPN" SG_ 2161442816 Adjust_hours 1605;
BA_ "SPN" SG_ 2161442816 Adjust_month 1606;
BA_ "SPN" SG_ 2161442816 Adjust_day 1607;
BA_ "SPN" SG_ 2161442816 Adjust_year 1608;
BA_ "SPN" SG_ 2161442816 Adjust_local_minute_offset 1609;
BA_ "SPN" SG_ 2161442816 Adjust_local_hour_offset 1610;
BA_ "SPN" SG_ 2161901568 Anti_theft_Encryption_Seed_Prese 1194;
BA_ "SystemSignalLongSymbol" SG_ 2161901568 Anti_theft_Encryption_Seed_Prese "Anti-theft Encryption Seed Present Indicator";
BA_ "SPN" SG_ 2161901568 Anti_theft_Password_Valid_Indica 1195;
BA_ "SystemSignalLongSymbol" SG_ 2161901568 Anti_theft_Password_Valid_Indica "Anti-theft Password Valid Indicator";
BA_ "SPN" SG_ 2161901568 Anti_theft_Component_Status_Stat 1196;
BA_ "SystemSignalLongSymbol" SG_ 2161901568 Anti_theft_Component_Status_Stat "Anti-theft Component Status States";
BA_ "SPN" SG_ 2161901568 Anti_theft_Modify_Password_State 1197;
BA_ "SystemSignalLongSymbol" SG_ 2161901568 Anti_theft_Modify_Password_State "Anti-theft Modify Password States";
BA_ "SPN" SG_ 2161901568 Anti_theft_Random_Number 1198;
BA_ "SPN" SG_ 2161967104 Anti_theft_Encryption_Indicator_ 1199;
BA_ "SystemSignalLongSymbol" SG_ 2161967104 Anti_theft_Encryption_Indicator_ "Anti-theft Encryption Indicator States";
BA_ "SPN" SG_ 2161967104 Anti_theft_Desired_Exit_Mode_Sta 1200;
BA_ "SystemSignalLongSymbol" SG_ 2161967104 Anti_theft_Desired_Exit_Mode_Sta "Anti-theft Desired Exit Mode States";
BA_ "SPN" SG_ 2161967104 Anti_theft_Command_States 1201;
BA_ "SPN" SG_ 2161967104 Anti_theft_Password_Representati 1202;
BA_ "SystemSignalLongSymbol" SG_ 2161967104 Anti_theft_Password_Representati "Anti-theft Password Representation";
BA_ "SPN" SG_ 2162032640 Trip_Group_1 988;
BA_ "SPN" SG_ 2162032640 Trip_Group_2___Proprietary 989;
BA_ "SPN" SG_ 2162032640 Service_Component_Identification 1584;
BA_ "SPN" SG_ 2162032640 Engine_Build_Hours_Reset 1211;
BA_ "SPN" SG_ 2162032640 Steering_Straight_Ahead_Position 3600;
BA_ "SystemSignalLongSymbol" SG_ 2162032640 Steering_Straight_Ahead_Position "Steering Straight Ahead Position Reset";
BA_ "SPN" SG_ 2162163712 Requested_Percent_Fan_Speed 986;
BA_ "SPN" SG_ 2162163712 Cab_Interior_Temperature_Command 1691;
BA_ "SPN" SG_ 2162163712 Auxiliary_Heater_Coolant_Pump_Re 1684;
BA_ "SystemSignalLongSymbol" SG_ 2162163712 Auxiliary_Heater_Coolant_Pump_Re "Auxiliary Heater Coolant Pump Request";
BA_ "SPN" SG_ 2162163712 Battery_Main_Switch_Hold_Request 1682;
BA_ "SPN" SG_ 2162163712 Operator_Seat_Direction_Switch 1714;
BA_ "SPN" SG_ 2162163712 Seat_Belt_Switch 1856;
BA_ "SPN" SG_ 2162163712 Vehicle_Limiting_Speed_Governor_0 1655;
BA_ "SystemSignalLongSymbol" SG_ 2162163712 Vehicle_Limiting_Speed_Governor_0 "Vehicle Limiting Speed Governor Decrement Switch";
BA_ "SPN" SG_ 2162163712 Vehicle_Limiting_Speed_Governor_1 1654;
BA_ "SystemSignalLongSymbol" SG_ 2162163712 Vehicle_Limiting_Speed_Governor_1 "Vehicle Limiting Speed Governor Increment Switch";
BA_ "SPN" SG_ 2162163712 Vehicle_Limiting_Speed_Governor_2 1653;
BA_ "SystemSignalLongSymbol" SG_ 2162163712 Vehicle_Limiting_Speed_Governor_2 "Vehicle Limiting Speed Governor Enable Switch";
BA_ "SPN" SG_ 2162163712 Diesel_Particulate_Filter_Regene0 3695;
BA_ "SystemSignalLongSymbol" SG_ 2162163712 Diesel_Particulate_Filter_Regene0 "Diesel Particulate Filter Regeneration Inhibit Switch";
BA_ "SPN" SG_ 2162163712 Diesel_Particulate_Filter_Regene1 3696;
BA_ "SystemSignalLongSymbol" SG_ 2162163712 Diesel_Particulate_Filter_Regene1 "Diesel Particulate Filter Regeneration Force Switch";
BA_ "SPN" SG_ 2162163712 Automatic_Gear_Shifting_Enable_S 1666;
BA_ "SystemSignalLongSymbol" SG_ 2162163712 Automatic_Gear_Shifting_Enable_S "Automatic Gear Shifting Enable Switch";
BA_ "SPN" SG_ 2162163712 Engine_Automatic_Start_Enable_Sw 1656;
BA_ "SystemSignalLongSymbol" SG_ 2162163712 Engine_Automatic_Start_Enable_Sw "Engine Automatic Start Enable Switch";
BA_ "SPN" SG_ 2162163712 Auxiliary_Heater_Mode_Request 1683;
BA_ "SPN" SG_ 2162163712 Request_Engine_Zone_Heating 1685;
BA_ "SPN" SG_ 2162163712 Request_Cab_Zone_Heating 1686;
BA_ "SPN" SG_ 2162163712 Selected_Maximum_Vehicle_Speed_L 2596;
BA_ "SystemSignalLongSymbol" SG_ 2162163712 Selected_Maximum_Vehicle_Speed_L "Selected Maximum Vehicle Speed Limit";
BA_ "SPN" SG_ 2163212288 Retarder_Torque_Mode 900;
BA_ "SPN" SG_ 2163212288 Retarder_Enable___Brake_Assist_S 571;
BA_ "SystemSignalLongSymbol" SG_ 2163212288 Retarder_Enable___Brake_Assist_S "Retarder Enable - Brake Assist Switch";
BA_ "SPN" SG_ 2163212288 Retarder_Enable___Shift_Assist_S 572;
BA_ "SystemSignalLongSymbol" SG_ 2163212288 Retarder_Enable___Shift_Assist_S "Retarder Enable - Shift Assist Switch";
BA_ "SPN" SG_ 2163212288 Actual_Retarder___Percent_Torque 520;
BA_ "SPN" SG_ 2163212288 Intended_Retarder_Percent_Torque 1085;
BA_ "SPN" SG_ 2163212288 Engine_Coolant_Load_Increase 1082;
BA_ "SPN" SG_ 2163212288 Retarder_Requesting_Brake_Light 1667;
BA_ "SPN" SG_ 2163212288 Retarder_Road_Speed_Limit_Switch 4233;
BA_ "SPN" SG_ 2163212288 Retarder_Road_Speed_Exceeded_Sta 4234;
BA_ "SystemSignalLongSymbol" SG_ 2163212288 Retarder_Road_Speed_Exceeded_Sta "Retarder Road Speed Exceeded Status";
BA_ "SPN" SG_ 2163212288 Source_Address_of_Controlling_De 1480;
BA_ "SystemSignalLongSymbol" SG_ 2163212288 Source_Address_of_Controlling_De "Source Address of Controlling Device for Retarder Control";
BA_ "SPN" SG_ 2163212288 Drivers_Demand_Retarder___Perce 1715;
BA_ "SystemSignalLongSymbol" SG_ 2163212288 Drivers_Demand_Retarder___Perce "Drivers Demand Retarder -  Percent Torque";
BA_ "SPN" SG_ 2163212288 Retarder_Selection__non_engine 1716;
BA_ "SPN" SG_ 2163212288 Actual_Maximum_Available_Retarde 1717;
BA_ "SystemSignalLongSymbol" SG_ 2163212288 Actual_Maximum_Available_Retarde "Actual Maximum Available Retarder - Percent Torque";
BA_ "SPN" SG_ 2163212544 ASR_Engine_Control_Active 561;
BA_ "SPN" SG_ 2163212544 ASR_Brake_Control_Active 562;
BA_ "SPN" SG_ 2163212544 Anti_Lock_Braking__ABS__Active 563;
BA_ "SPN" SG_ 2163212544 EBS_Brake_Switch 1121;
BA_ "SPN" SG_ 2163212544 Brake_Pedal_Position 521;
BA_ "SPN" SG_ 2163212544 ABS_Off_road_Switch 575;
BA_ "SPN" SG_ 2163212544 ASR_Off_road_Switch 576;
BA_ "SPN" SG_ 2163212544 ASR__Hill_Holder__Switch 577;
BA_ "SPN" SG_ 2163212544 Traction_Control_Override_Switch 1238;
BA_ "SPN" SG_ 2163212544 Accelerator_Interlock_Switch 972;
BA_ "SPN" SG_ 2163212544 Engine_Derate_Switch 971;
BA_ "SPN" SG_ 2163212544 Engine_Auxiliary_Shutdown_Switch 970;
BA_ "SPN" SG_ 2163212544 Remote_Accelerator_Enable_Switch 969;
BA_ "SPN" SG_ 2163212544 Engine_Retarder_Selection 973;
BA_ "SPN" SG_ 2163212544 ABS_Fully_Operational 1243;
BA_ "SPN" SG_ 2163212544 EBS_Red_Warning_Signal 1439;
BA_ "SPN" SG_ 2163212544 ABS_EBS_Amber_Warning_Signal__Po 1438;
BA_ "SystemSignalLongSymbol" SG_ 2163212544 ABS_EBS_Amber_Warning_Signal__Po "ABS/EBS Amber Warning Signal (Powered Vehicle)";
BA_ "SPN" SG_ 2163212544 ATC_ASR_Information_Signal 1793;
BA_ "SPN" SG_ 2163212544 Source_Address_of_Controlling_De 1481;
BA_ "SystemSignalLongSymbol" SG_ 2163212544 Source_Address_of_Controlling_De "Source Address of Controlling Device for Brake Control";
BA_ "SPN" SG_ 2163212544 Halt_brake_switch 2911;
BA_ "SPN" SG_ 2163212544 Trailer_ABS_Status 1836;
BA_ "SPN" SG_ 2163212544 Tractor_Mounted_Trailer_ABS_Warn 1792;
BA_ "SystemSignalLongSymbol" SG_ 2163212544 Tractor_Mounted_Trailer_ABS_Warn "Tractor-Mounted Trailer ABS Warning Signal";
BA_ "SPN" SG_ 2163212800 Transmission_Driveline_Engaged 560;
BA_ "SPN" SG_ 2163212800 Transmission_Torque_Converter_Lo 573;
BA_ "SystemSignalLongSymbol" SG_ 2163212800 Transmission_Torque_Converter_Lo "Transmission Torque Converter Lockup Engaged";
BA_ "SPN" SG_ 2163212800 Transmission_Shift_In_Process 574;
BA_ "SPN" SG_ 2163212800 Transmission_Output_Shaft_Speed 191;
BA_ "SPN" SG_ 2163212800 Percent_Clutch_Slip 522;
BA_ "SPN" SG_ 2163212800 Engine_Momentary_Overspeed_Enabl 606;
BA_ "SystemSignalLongSymbol" SG_ 2163212800 Engine_Momentary_Overspeed_Enabl "Engine Momentary Overspeed Enable";
BA_ "SPN" SG_ 2163212800 Progressive_Shift_Disable 607;
BA_ "SPN" SG_ 2163212800 Transmission_Input_Shaft_Speed 161;
BA_ "SPN" SG_ 2163212800 Source_Address_of_Controlling_De 1482;
BA_ "SystemSignalLongSymbol" SG_ 2163212800 Source_Address_of_Controlling_De "Source Address of Controlling Device for Transmission Control";
BA_ "SPN" SG_ 2163213056 Accelerator_Pedal_1_Low_Idle_Swi 558;
BA_ "SystemSignalLongSymbol" SG_ 2163213056 Accelerator_Pedal_1_Low_Idle_Swi "Accelerator Pedal 1 Low Idle Switch";
BA_ "SPN" SG_ 2163213056 Accelerator_Pedal_Kickdown_Switc 559;
BA_ "SystemSignalLongSymbol" SG_ 2163213056 Accelerator_Pedal_Kickdown_Switc "Accelerator Pedal Kickdown Switch";
BA_ "SPN" SG_ 2163213056 Road_Speed_Limit_Status 1437;
BA_ "SPN" SG_ 2163213056 Accelerator_Pedal_2_Low_Idle_Swi 2970;
BA_ "SystemSignalLongSymbol" SG_ 2163213056 Accelerator_Pedal_2_Low_Idle_Swi "Accelerator Pedal 2 Low Idle Switch";
BA_ "SPN" SG_ 2163213056 Accelerator_Pedal_Position_1 91;
BA_ "SPN" SG_ 2163213056 Engine_Percent_Load_At_Current_S 92;
BA_ "SystemSignalLongSymbol" SG_ 2163213056 Engine_Percent_Load_At_Current_S "Engine Percent Load At Current Speed";
BA_ "SPN" SG_ 2163213056 Remote_Accelerator_Pedal_Positio 974;
BA_ "SystemSignalLongSymbol" SG_ 2163213056 Remote_Accelerator_Pedal_Positio "Remote Accelerator Pedal Position";
BA_ "SPN" SG_ 2163213056 Accelerator_Pedal_Position_2 29;
BA_ "SPN" SG_ 2163213056 Vehicle_Acceleration_Rate_Limit_ 2979;
BA_ "SystemSignalLongSymbol" SG_ 2163213056 Vehicle_Acceleration_Rate_Limit_ "Vehicle Acceleration Rate Limit Status";
BA_ "SPN" SG_ 2163213056 Actual_Maximum_Available_Engine_ 3357;
BA_ "SystemSignalLongSymbol" SG_ 2163213056 Actual_Maximum_Available_Engine_ "Actual Maximum Available Engine - Percent Torque";
BA_ "SPN" SG_ 2163213312 Engine_Torque_Mode 899;
BA_ "SPN" SG_ 2163213312 Actual_Engine___Percent_Torque_H 4154;
BA_ "SystemSignalLongSymbol" SG_ 2163213312 Actual_Engine___Percent_Torque_H "Actual Engine - Percent Torque High Resolution";
BA_ "SPN" SG_ 2163213312 Driver_s_Demand_Engine___Percent 512;
BA_ "SystemSignalLongSymbol" SG_ 2163213312 Driver_s_Demand_Engine___Percent "Driver's Demand Engine - Percent Torque";
BA_ "SPN" SG_ 2163213312 Actual_Engine___Percent_Torque 513;
BA_ "SPN" SG_ 2163213312 Engine_Speed 190;
BA_ "SPN" SG_ 2163213312 Source_Address_of_Controlling_De 1483;
BA_ "SystemSignalLongSymbol" SG_ 2163213312 Source_Address_of_Controlling_De "Source Address of Controlling Device for Engine Control";
BA_ "SPN" SG_ 2163213312 Engine_Starter_Mode 1675;
BA_ "SPN" SG_ 2163213312 Engine_Demand___Percent_Torque 2432;
BA_ "SPN" SG_ 2163213568 Transmission_Selected_Gear 524;
BA_ "SPN" SG_ 2163213568 Transmission_Actual_Gear_Ratio 526;
BA_ "SPN" SG_ 2163213568 Transmission_Current_Gear 523;
BA_ "SPN" SG_ 2163213568 Transmission_Requested_Range 162;
BA_ "SPN" SG_ 2163213568 Transmission_Current_Range 163;
BA_ "SPN" SG_ 2163213824 Location 927;
BA_ "SPN" SG_ 2163213824 Differential_Lock_State___Front_ 568;
BA_ "SystemSignalLongSymbol" SG_ 2163213824 Differential_Lock_State___Front_ "Differential Lock State - Front Axle 2";
BA_ "SPN" SG_ 2163213824 Differential_Lock_State___Rear_A 570;
BA_ "SystemSignalLongSymbol" SG_ 2163213824 Differential_Lock_State___Rear_A "Differential Lock State - Rear Axle 2";
BA_ "SPN" SG_ 2163213824 Differential_Lock_State___Centra0 566;
BA_ "SystemSignalLongSymbol" SG_ 2163213824 Differential_Lock_State___Centra0 "Differential Lock State - Central Rear";
BA_ "SPN" SG_ 2163213824 Front_axle_group_engagement_stat 3819;
BA_ "SystemSignalLongSymbol" SG_ 2163213824 Front_axle_group_engagement_stat "Front axle group engagement status";
BA_ "SPN" SG_ 2163213824 Rear_axle_group_engagement_statu 3820;
BA_ "SystemSignalLongSymbol" SG_ 2163213824 Rear_axle_group_engagement_statu "Rear axle group engagement status";
BA_ "SPN" SG_ 2163214080 Lane_Departure_Left 3565;
BA_ "SPN" SG_ 2163214080 Lane_Departure_Right 3566;
BA_ "SPN" SG_ 2163214080 Lane_Departure_Imminent__Right_S 1701;
BA_ "SystemSignalLongSymbol" SG_ 2163214080 Lane_Departure_Imminent__Right_S "Lane Departure Imminent, Right Side";
BA_ "SPN" SG_ 2163214080 Lane_Departure_Imminent__Left_Si 1700;
BA_ "SystemSignalLongSymbol" SG_ 2163214080 Lane_Departure_Imminent__Left_Si "Lane Departure Imminent, Left Side";
BA_ "SPN" SG_ 2163214336 Hydraulic_Pressure 1762;
BA_ "SPN" SG_ 2163214336 Engine_Hydraulic_Pressure_Govern0 1763;
BA_ "SystemSignalLongSymbol" SG_ 2163214336 Engine_Hydraulic_Pressure_Govern0 "Engine Hydraulic Pressure Governor Mode Indicator";
BA_ "SPN" SG_ 2163214336 Engine_Hydraulic_Pressure_Govern1 1764;
BA_ "SystemSignalLongSymbol" SG_ 2163214336 Engine_Hydraulic_Pressure_Govern1 "Engine Hydraulic Pressure Governor Switch";
BA_ "SPN" SG_ 2163214336 Fire_Apparatus_Pump_Engagement 2599;
BA_ "SPN" SG_ 2163214592 Steering_Wheel_Angle 1807;
BA_ "SPN" SG_ 2163214592 Steering_Wheel_Turn_Counter 1811;
BA_ "SPN" SG_ 2163214592 Steering_Wheel_Angle_Sensor_Type 1812;
BA_ "SPN" SG_ 2163214592 Yaw_Rate 1808;
BA_ "SPN" SG_ 2163214592 Lateral_Acceleration 1809;
BA_ "SPN" SG_ 2163214592 Longitudinal_Acceleration 1810;
BA_ "SPN" SG_ 2163214848 Engine_Exhaust_Gas_Recirculation 2659;
BA_ "SystemSignalLongSymbol" SG_ 2163214848 Engine_Exhaust_Gas_Recirculation "Engine Exhaust Gas Recirculation (EGR) Mass Flow Rate";
BA_ "SPN" SG_ 2163214848 Engine_Inlet_Air_Mass_Flow_Rate 132;
BA_ "SPN" SG_ 2163215104 Actual_Inner_wheel_steering_angl 2927;
BA_ "SystemSignalLongSymbol" SG_ 2163215104 Actual_Inner_wheel_steering_angl "Actual Inner wheel steering angle";
BA_ "SPN" SG_ 2163215104 Axle_Location 2928;
BA_ "SPN" SG_ 2163215104 Status_of_Steering_Axle 2923;
BA_ "SPN" SG_ 2163215104 Steerable_Lift_Axle_Lowering_Inh 2922;
BA_ "SystemSignalLongSymbol" SG_ 2163215104 Steerable_Lift_Axle_Lowering_Inh "Steerable Lift Axle Lowering Inhibit";
BA_ "SPN" SG_ 2163215104 Steering_Type 2924;
BA_ "SPN" SG_ 2163215104 Type_of_Steering_Forces 2925;
BA_ "SPN" SG_ 2163215104 Type_of_Steering_Transmission 2926;
BA_ "SPN" SG_ 2163215360 Transmission_Torque_Converter_Ra 3030;
BA_ "SystemSignalLongSymbol" SG_ 2163215360 Transmission_Torque_Converter_Ra "Transmission Torque Converter Ratio";
BA_ "SPN" SG_ 2163215616 Blade_Control_Mode_Switch 3156;
BA_ "SPN" SG_ 2163215616 Desired_Grade_Offset_Switch 3157;
BA_ "SPN" SG_ 2163215616 Blade_Auto_Mode_Command 3158;
BA_ "SPN" SG_ 2163215616 Left_Blade_Control_Mode_Operator 3334;
BA_ "SystemSignalLongSymbol" SG_ 2163215616 Left_Blade_Control_Mode_Operator "Left Blade Control Mode Operator Control";
BA_ "SPN" SG_ 2163215616 Right_Blade_Control_Mode_Operato 3335;
BA_ "SystemSignalLongSymbol" SG_ 2163215616 Right_Blade_Control_Mode_Operato "Right Blade Control Mode Operator Control";
BA_ "SPN" SG_ 2163215616 Left_Desired_Blade_Offset_Operat 3336;
BA_ "SystemSignalLongSymbol" SG_ 2163215616 Left_Desired_Blade_Offset_Operat "Left Desired Blade Offset Operator Control";
BA_ "SPN" SG_ 2163215616 Right_Desired_Blade_Offset_Opera 3337;
BA_ "SystemSignalLongSymbol" SG_ 2163215616 Right_Desired_Blade_Offset_Opera "Right Desired Blade Offset Operator Control";
BA_ "SPN" SG_ 2163215616 Side_shift_Blade_Control_Mode_Op 3338;
BA_ "SystemSignalLongSymbol" SG_ 2163215616 Side_shift_Blade_Control_Mode_Op "Side-shift Blade Control Mode Operator Control";
BA_ "SPN" SG_ 2163215616 Side_shift_Desired_Blade_Offset_ 3339;
BA_ "SystemSignalLongSymbol" SG_ 2163215616 Side_shift_Desired_Blade_Offset_ "Side-shift Desired Blade Offset Operator Control";
BA_ "SPN" SG_ 2163215872 Aftertreatment_1_Intake_NOx 3216;
BA_ "SPN" SG_ 2163215872 Aftertreatment_1_Intake__O2 3217;
BA_ "SPN" SG_ 2163215872 Aftertreatment_1_Intake_Gas_Sens0 3218;
BA_ "SystemSignalLongSymbol" SG_ 2163215872 Aftertreatment_1_Intake_Gas_Sens0 "Aftertreatment 1 Intake Gas Sensor Power In Range";
BA_ "SPN" SG_ 2163215872 Aftertreatment_1_Intake_Gas_Sens1 3219;
BA_ "SystemSignalLongSymbol" SG_ 2163215872 Aftertreatment_1_Intake_Gas_Sens1 "Aftertreatment 1 Intake Gas Sensor at Temperature";
BA_ "SPN" SG_ 2163215872 Aftertreatment_1_Intake_NOx_Read 3220;
BA_ "SystemSignalLongSymbol" SG_ 2163215872 Aftertreatment_1_Intake_NOx_Read "Aftertreatment 1 Intake NOx Reading Stable";
BA_ "SPN" SG_ 2163215872 Aftertreatment_1_Intake_Wide_Ran 3221;
BA_ "SystemSignalLongSymbol" SG_ 2163215872 Aftertreatment_1_Intake_Wide_Ran "Aftertreatment 1 Intake Wide-Range % O2 Reading Stable";
BA_ "SPN" SG_ 2163215872 Aftertreatment_1_Intake_Gas_Sens2 3222;
BA_ "SystemSignalLongSymbol" SG_ 2163215872 Aftertreatment_1_Intake_Gas_Sens2 "Aftertreatment 1 Intake Gas Sensor Heater Preliminary FMI";
BA_ "SPN" SG_ 2163215872 Aftertreatment_1_Intake_Gas_Sens3 3223;
BA_ "SystemSignalLongSymbol" SG_ 2163215872 Aftertreatment_1_Intake_Gas_Sens3 "Aftertreatment 1 Intake Gas Sensor Heater Control";
BA_ "SPN" SG_ 2163215872 Aftertreatment_1_Intake_NOx_Sens 3224;
BA_ "SystemSignalLongSymbol" SG_ 2163215872 Aftertreatment_1_Intake_NOx_Sens "Aftertreatment 1 Intake NOx Sensor Preliminary FMI";
BA_ "SPN" SG_ 2163215872 Aftertreatment_1_Intake_Oxygen_S 3225;
BA_ "SystemSignalLongSymbol" SG_ 2163215872 Aftertreatment_1_Intake_Oxygen_S "Aftertreatment 1 Intake Oxygen Sensor Preliminary FMI";
BA_ "SPN" SG_ 2163216128 Aftertreatment_1_Outlet_NOx 3226;
BA_ "SPN" SG_ 2163216128 Aftertreatment_1_Outlet__O2 3227;
BA_ "SPN" SG_ 2163216128 Aftertreatment_1_Outlet_Gas_Sens0 3228;
BA_ "SystemSignalLongSymbol" SG_ 2163216128 Aftertreatment_1_Outlet_Gas_Sens0 "Aftertreatment 1 Outlet Gas Sensor Power In Range";
BA_ "SPN" SG_ 2163216128 Aftertreatment_1_Outlet_Gas_Sens1 3229;
BA_ "SystemSignalLongSymbol" SG_ 2163216128 Aftertreatment_1_Outlet_Gas_Sens1 "Aftertreatment 1 Outlet Gas Sensor at Temperature";
BA_ "SPN" SG_ 2163216128 Aftertreatment_1_Outlet_NOx_Read 3230;
BA_ "SystemSignalLongSymbol" SG_ 2163216128 Aftertreatment_1_Outlet_NOx_Read "Aftertreatment 1 Outlet NOx Reading Stable";
BA_ "SPN" SG_ 2163216128 Aftertreatment_1_Outlet_Wide_Ran 3231;
BA_ "SystemSignalLongSymbol" SG_ 2163216128 Aftertreatment_1_Outlet_Wide_Ran "Aftertreatment 1 Outlet Wide-Range %O2 Reading Stable";
BA_ "SPN" SG_ 2163216128 Aftertreatment_1_Outlet_Gas_Sens2 3232;
BA_ "SystemSignalLongSymbol" SG_ 2163216128 Aftertreatment_1_Outlet_Gas_Sens2 "Aftertreatment 1 Outlet Gas Sensor Heater Preliminary FMI";
BA_ "SPN" SG_ 2163216128 Aftertreatment_1_Outlet_Gas_Sens3 3233;
BA_ "SystemSignalLongSymbol" SG_ 2163216128 Aftertreatment_1_Outlet_Gas_Sens3 "Aftertreatment 1 Outlet Gas Sensor Heater Control";
BA_ "SPN" SG_ 2163216128 Aftertreatment_1_Outlet_NOx_Sens 3234;
BA_ "SystemSignalLongSymbol" SG_ 2163216128 Aftertreatment_1_Outlet_NOx_Sens "Aftertreatment 1 Outlet NOx Sensor Preliminary FMI";
BA_ "SPN" SG_ 2163216128 Aftertreatment_1_Outlet_Oxygen_S 3235;
BA_ "SystemSignalLongSymbol" SG_ 2163216128 Aftertreatment_1_Outlet_Oxygen_S "Aftertreatment 1 Outlet Oxygen Sensor Preliminary FMI";
BA_ "SPN" SG_ 2163216384 Aftertreatment_2_Intake_NOx 3255;
BA_ "SPN" SG_ 2163216384 Aftertreatment_2_Intake__O2 3256;
BA_ "SPN" SG_ 2163216384 Aftertreatment_2_Intake_Gas_Sens0 3257;
BA_ "SystemSignalLongSymbol" SG_ 2163216384 Aftertreatment_2_Intake_Gas_Sens0 "Aftertreatment 2 Intake Gas Sensor Power In Range";
BA_ "SPN" SG_ 2163216384 Aftertreatment_2_Intake_Gas_Sens1 3258;
BA_ "SystemSignalLongSymbol" SG_ 2163216384 Aftertreatment_2_Intake_Gas_Sens1 "Aftertreatment 2 Intake Gas Sensor at Temperature";
BA_ "SPN" SG_ 2163216384 Aftertreatment_2_Intake_NOx_Read 3259;
BA_ "SystemSignalLongSymbol" SG_ 2163216384 Aftertreatment_2_Intake_NOx_Read "Aftertreatment 2 Intake NOx Reading Stable";
BA_ "SPN" SG_ 2163216384 Aftertreatment_2_Intake_Wide_Ran 3260;
BA_ "SystemSignalLongSymbol" SG_ 2163216384 Aftertreatment_2_Intake_Wide_Ran "Aftertreatment 2 Intake Wide-Range % O2 Reading Stable";
BA_ "SPN" SG_ 2163216384 Aftertreatment_2_Intake_Gas_Sens2 3261;
BA_ "SystemSignalLongSymbol" SG_ 2163216384 Aftertreatment_2_Intake_Gas_Sens2 "Aftertreatment 2 Intake Gas Sensor Heater Preliminary FMI";
BA_ "SPN" SG_ 2163216384 Aftertreatment_2_Intake_Gas_Sens3 3262;
BA_ "SystemSignalLongSymbol" SG_ 2163216384 Aftertreatment_2_Intake_Gas_Sens3 "Aftertreatment 2 Intake Gas Sensor Heater Control";
BA_ "SPN" SG_ 2163216384 Aftertreatment_2_Intake_NOx_Sens 3263;
BA_ "SystemSignalLongSymbol" SG_ 2163216384 Aftertreatment_2_Intake_NOx_Sens "Aftertreatment 2 Intake NOx Sensor Preliminary FMI";
BA_ "SPN" SG_ 2163216384 Aftertreatment_2_Intake_Oxygen_S 3264;
BA_ "SystemSignalLongSymbol" SG_ 2163216384 Aftertreatment_2_Intake_Oxygen_S "Aftertreatment 2 Intake Oxygen Sensor Preliminary FMI";
BA_ "SPN" SG_ 2163216640 Aftertreatment_2_Outlet_NOx 3265;
BA_ "SPN" SG_ 2163216640 Aftertreatment_2_Outlet__O2 3266;
BA_ "SPN" SG_ 2163216640 Aftertreatment_2_Outlet_Gas_Sens0 3267;
BA_ "SystemSignalLongSymbol" SG_ 2163216640 Aftertreatment_2_Outlet_Gas_Sens0 "Aftertreatment 2 Outlet Gas Sensor Power In Range";
BA_ "SPN" SG_ 2163216640 Aftertreatment_2_Outlet_Gas_Sens1 3268;
BA_ "SystemSignalLongSymbol" SG_ 2163216640 Aftertreatment_2_Outlet_Gas_Sens1 "Aftertreatment 2 Outlet Gas Sensor at Temperature";
BA_ "SPN" SG_ 2163216640 Aftertreatment_2_Outlet_NOx_Read 3269;
BA_ "SystemSignalLongSymbol" SG_ 2163216640 Aftertreatment_2_Outlet_NOx_Read "Aftertreatment 2 Outlet NOx Reading Stable";
BA_ "SPN" SG_ 2163216640 Aftertreatment_2_Outlet_Wide_Ran 3270;
BA_ "SystemSignalLongSymbol" SG_ 2163216640 Aftertreatment_2_Outlet_Wide_Ran "Aftertreatment 2 Outlet Wide-Range % O2 Reading Stable";
BA_ "SPN" SG_ 2163216640 Aftertreatment_2_Outlet_Gas_Sens2 3271;
BA_ "SystemSignalLongSymbol" SG_ 2163216640 Aftertreatment_2_Outlet_Gas_Sens2 "Aftertreatment 2 Outlet Gas Sensor Heater Preliminary FMI";
BA_ "SPN" SG_ 2163216640 Aftertreatment_2_Outlet_Gas_Sens3 3272;
BA_ "SystemSignalLongSymbol" SG_ 2163216640 Aftertreatment_2_Outlet_Gas_Sens3 "Aftertreatment 2 Outlet Gas Sensor Heater Control";
BA_ "SPN" SG_ 2163216640 Aftertreatment_2_Outlet_NOx_Sens 3273;
BA_ "SystemSignalLongSymbol" SG_ 2163216640 Aftertreatment_2_Outlet_NOx_Sens "Aftertreatment 2 Outlet NOx Sensor Preliminary FMI";
BA_ "SPN" SG_ 2163216640 Aftertreatment_2_Outlet_Oxygen_S 3274;
BA_ "SystemSignalLongSymbol" SG_ 2163216640 Aftertreatment_2_Outlet_Oxygen_S "Aftertreatment 2 Outlet Oxygen Sensor Preliminary FMI";
BA_ "SPN" SG_ 2163216896 Fifth_Wheel_Vertical_Force 3308;
BA_ "SPN" SG_ 2163216896 Fifth_Wheel_Drawbar_Force 3309;
BA_ "SPN" SG_ 2163216896 Fifth_Wheel_Roll_Moment_ 3310;
BA_ "SPN" SG_ 2163216896 Fifth_Wheel_Roll_Warning_Indicat 3317;
BA_ "SystemSignalLongSymbol" SG_ 2163216896 Fifth_Wheel_Roll_Warning_Indicat "Fifth Wheel Roll Warning Indicator";
BA_ "SPN" SG_ 2163217152 Pitch_Angle 3318;
BA_ "SPN" SG_ 2163217152 Roll_Angle 3319;
BA_ "SPN" SG_ 2163217152 Pitch_Rate 3322;
BA_ "SPN" SG_ 2163217152 Pitch_Angle_Figure_of_Merit 3323;
BA_ "SPN" SG_ 2163217152 Roll_Angle_Figure_of_Merit 3324;
BA_ "SPN" SG_ 2163217152 Pitch_Rate_Figure_of_Merit 3325;
BA_ "SPN" SG_ 2163217152 Pitch_and_Roll_Compensated 3326;
BA_ "SPN" SG_ 2163217152 Roll_and_Pitch_Measurement_Laten 3327;
BA_ "SystemSignalLongSymbol" SG_ 2163217152 Roll_and_Pitch_Measurement_Laten "Roll and Pitch Measurement Latency";
BA_ "SPN" SG_ 2163217408 Relative_Blade_Height 3365;
BA_ "SPN" SG_ 2163217408 Blade_Rotation_Angle 3331;
BA_ "SPN" SG_ 2163217408 Relative_Blade_Height_and_Blade_ 3366;
BA_ "SystemSignalLongSymbol" SG_ 2163217408 Relative_Blade_Height_and_Blade_ "Relative Blade Height and Blade Rotation Angle Measurement Latency";
BA_ "SPN" SG_ 2163217408 Relative_Blade_Height_Figure_of_ 3367;
BA_ "SystemSignalLongSymbol" SG_ 2163217408 Relative_Blade_Height_Figure_of_ "Relative Blade Height Figure of Merit";
BA_ "SPN" SG_ 2163217408 Blade_Rotation_Angle_Figure_of_M 3332;
BA_ "SystemSignalLongSymbol" SG_ 2163217408 Blade_Rotation_Angle_Figure_of_M "Blade Rotation Angle Figure of Merit";
BA_ "SPN" SG_ 2163217920 Engine_Cylinder_1_Combustion_Sta 3387;
BA_ "SystemSignalLongSymbol" SG_ 2163217920 Engine_Cylinder_1_Combustion_Sta "Engine Cylinder 1 Combustion Status";
BA_ "SPN" SG_ 2163217920 Engine_Cylinder_2_Combustion_Sta 3388;
BA_ "SystemSignalLongSymbol" SG_ 2163217920 Engine_Cylinder_2_Combustion_Sta "Engine Cylinder 2 Combustion Status";
BA_ "SPN" SG_ 2163217920 Engine_Cylinder_3_Combustion_Sta 3389;
BA_ "SystemSignalLongSymbol" SG_ 2163217920 Engine_Cylinder_3_Combustion_Sta "Engine Cylinder 3 Combustion Status";
BA_ "SPN" SG_ 2163217920 Engine_Cylinder_4_Combustion_Sta 3390;
BA_ "SystemSignalLongSymbol" SG_ 2163217920 Engine_Cylinder_4_Combustion_Sta "Engine Cylinder 4 Combustion Status";
BA_ "SPN" SG_ 2163217920 Engine_Cylinder_5_Combustion_Sta 3391;
BA_ "SystemSignalLongSymbol" SG_ 2163217920 Engine_Cylinder_5_Combustion_Sta "Engine Cylinder 5 Combustion Status";
BA_ "SPN" SG_ 2163217920 Engine_Cylinder_6_Combustion_Sta 3392;
BA_ "SystemSignalLongSymbol" SG_ 2163217920 Engine_Cylinder_6_Combustion_Sta "Engine Cylinder 6 Combustion Status";
BA_ "SPN" SG_ 2163217920 Engine_Cylinder_7_Combustion_Sta 3393;
BA_ "SystemSignalLongSymbol" SG_ 2163217920 Engine_Cylinder_7_Combustion_Sta "Engine Cylinder 7 Combustion Status";
BA_ "SPN" SG_ 2163217920 Engine_Cylinder_8_Combustion_Sta 3394;
BA_ "SystemSignalLongSymbol" SG_ 2163217920 Engine_Cylinder_8_Combustion_Sta "Engine Cylinder 8 Combustion Status";
BA_ "SPN" SG_ 2163217920 Engine_Cylinder_9_Combustion_Sta 3395;
BA_ "SystemSignalLongSymbol" SG_ 2163217920 Engine_Cylinder_9_Combustion_Sta "Engine Cylinder 9 Combustion Status";
BA_ "SPN" SG_ 2163217920 Engine_Cylinder_10_Combustion_St 3396;
BA_ "SystemSignalLongSymbol" SG_ 2163217920 Engine_Cylinder_10_Combustion_St "Engine Cylinder 10 Combustion Status";
BA_ "SPN" SG_ 2163217920 Engine_Cylinder_11_Combustion_St 3397;
BA_ "SystemSignalLongSymbol" SG_ 2163217920 Engine_Cylinder_11_Combustion_St "Engine Cylinder 11 Combustion Status";
BA_ "SPN" SG_ 2163217920 Engine_Cylinder_12_Combustion_St 3398;
BA_ "SystemSignalLongSymbol" SG_ 2163217920 Engine_Cylinder_12_Combustion_St "Engine Cylinder 12 Combustion Status";
BA_ "SPN" SG_ 2163217920 Engine_Cylinder_13_Combustion_St 3399;
BA_ "SystemSignalLongSymbol" SG_ 2163217920 Engine_Cylinder_13_Combustion_St "Engine Cylinder 13 Combustion Status";
BA_ "SPN" SG_ 2163217920 Engine_Cylinder_14_Combustion_St 3400;
BA_ "SystemSignalLongSymbol" SG_ 2163217920 Engine_Cylinder_14_Combustion_St "Engine Cylinder 14 Combustion Status";
BA_ "SPN" SG_ 2163217920 Engine_Cylinder_15_Combustion_St 3401;
BA_ "SystemSignalLongSymbol" SG_ 2163217920 Engine_Cylinder_15_Combustion_St "Engine Cylinder 15 Combustion Status";
BA_ "SPN" SG_ 2163217920 Engine_Cylinder_16_Combustion_St 3402;
BA_ "SystemSignalLongSymbol" SG_ 2163217920 Engine_Cylinder_16_Combustion_St "Engine Cylinder 16 Combustion Status";
BA_ "SPN" SG_ 2163217920 Engine_Cylinder_17_Combustion_St 3403;
BA_ "SystemSignalLongSymbol" SG_ 2163217920 Engine_Cylinder_17_Combustion_St "Engine Cylinder 17 Combustion Status";
BA_ "SPN" SG_ 2163217920 Engine_Cylinder_18_Combustion_St 3404;
BA_ "SystemSignalLongSymbol" SG_ 2163217920 Engine_Cylinder_18_Combustion_St "Engine Cylinder 18 Combustion Status";
BA_ "SPN" SG_ 2163217920 Engine_Cylinder_19_Combustion_St 3405;
BA_ "SystemSignalLongSymbol" SG_ 2163217920 Engine_Cylinder_19_Combustion_St "Engine Cylinder 19 Combustion Status";
BA_ "SPN" SG_ 2163217920 Engine_Cylinder_20_Combustion_St 3406;
BA_ "SystemSignalLongSymbol" SG_ 2163217920 Engine_Cylinder_20_Combustion_St "Engine Cylinder 20 Combustion Status";
BA_ "SPN" SG_ 2163217920 Engine_Cylinder_21_Combustion_St 3407;
BA_ "SystemSignalLongSymbol" SG_ 2163217920 Engine_Cylinder_21_Combustion_St "Engine Cylinder 21 Combustion Status";
BA_ "SPN" SG_ 2163217920 Engine_Cylinder_22_Combustion_St 3408;
BA_ "SystemSignalLongSymbol" SG_ 2163217920 Engine_Cylinder_22_Combustion_St "Engine Cylinder 22 Combustion Status";
BA_ "SPN" SG_ 2163217920 Engine_Cylinder_23_Combustion_St 3409;
BA_ "SystemSignalLongSymbol" SG_ 2163217920 Engine_Cylinder_23_Combustion_St "Engine Cylinder 23 Combustion Status";
BA_ "SPN" SG_ 2163217920 Engine_Cylinder_24_Combustion_St 3410;
BA_ "SystemSignalLongSymbol" SG_ 2163217920 Engine_Cylinder_24_Combustion_St "Engine Cylinder 24 Combustion Status";
BA_ "SPN" SG_ 2163218176 Engine_Cylinder_1_Knock_Level 1352;
BA_ "SPN" SG_ 2163218176 Engine_Cylinder_2_Knock_Level 1353;
BA_ "SPN" SG_ 2163218176 Engine_Cylinder_3_Knock_Level 1354;
BA_ "SPN" SG_ 2163218176 Engine_Cylinder_4_Knock_Level 1355;
BA_ "SPN" SG_ 2163218176 Engine_Cylinder_5_Knock_Level 1356;
BA_ "SPN" SG_ 2163218176 Engine_Cylinder_6_Knock_Level 1357;
BA_ "SPN" SG_ 2163218176 Engine_Cylinder_7_Knock_Level 1358;
BA_ "SPN" SG_ 2163218176 Engine_Cylinder_8_Knock_Level 1359;
BA_ "SPN" SG_ 2163218432 Engine_Cylinder_9_Knock_Level 1360;
BA_ "SPN" SG_ 2163218432 Engine_Cylinder_10_Knock_Level 1361;
BA_ "SPN" SG_ 2163218432 Engine_Cylinder_11_Knock_Level 1362;
BA_ "SPN" SG_ 2163218432 Engine_Cylinder_12_Knock_Level 1363;
BA_ "SPN" SG_ 2163218432 Engine_Cylinder_13_Knock_Level 1364;
BA_ "SPN" SG_ 2163218432 Engine_Cylinder_14_Knock_Level 1365;
BA_ "SPN" SG_ 2163218432 Engine_Cylinder_15_Knock_Level 1366;
BA_ "SPN" SG_ 2163218432 Engine_Cylinder_16_Knock_Level 1367;
BA_ "SPN" SG_ 2163218688 Engine_Cylinder_17_Knock_Level 1368;
BA_ "SPN" SG_ 2163218688 Engine_Cylinder_18_Knock_Level 1369;
BA_ "SPN" SG_ 2163218688 Engine_Cylinder_19_Knock_Level 1370;
BA_ "SPN" SG_ 2163218688 Engine_Cylinder_20_Knock_Level 1371;
BA_ "SPN" SG_ 2163218688 Engine_Cylinder_21_Knock_Level 1372;
BA_ "SPN" SG_ 2163218688 Engine_Cylinder_22_Knock_Level 1373;
BA_ "SPN" SG_ 2163218688 Engine_Cylinder_23_Knock_Level 1374;
BA_ "SPN" SG_ 2163218688 Engine_Cylinder_24_Knock_Level 1375;
BA_ "SPN" SG_ 2163218944 Engine_Throttle_Actuator_1_Contr 3464;
BA_ "SystemSignalLongSymbol" SG_ 2163218944 Engine_Throttle_Actuator_1_Contr "Engine Throttle Actuator 1 Control Command";
BA_ "SPN" SG_ 2163218944 Engine_Throttle_Actuator_2_Contr 3465;
BA_ "SystemSignalLongSymbol" SG_ 2163218944 Engine_Throttle_Actuator_2_Contr "Engine Throttle Actuator 2 Control Command";
BA_ "SPN" SG_ 2163218944 Engine_Fuel_Actuator_1_Control_C 633;
BA_ "SystemSignalLongSymbol" SG_ 2163218944 Engine_Fuel_Actuator_1_Control_C "Engine Fuel Actuator 1 Control Command";
BA_ "SPN" SG_ 2163218944 Engine_Fuel_Actuator_2_Control_C 1244;
BA_ "SystemSignalLongSymbol" SG_ 2163218944 Engine_Fuel_Actuator_2_Control_C "Engine Fuel Actuator 2 Control Command";
BA_ "SPN" SG_ 2163219712 Steering_Wheel_Angle 3683;
BA_ "SPN" SG_ 2163219712 Steering_Wheel_Angle_Range_Count0 3684;
BA_ "SystemSignalLongSymbol" SG_ 2163219712 Steering_Wheel_Angle_Range_Count0 "Steering Wheel Angle Range Counter";
BA_ "SPN" SG_ 2163219712 Steering_Wheel_Angle_Range_Count1 3685;
BA_ "SystemSignalLongSymbol" SG_ 2163219712 Steering_Wheel_Angle_Range_Count1 "Steering Wheel Angle Range Counter Type";
BA_ "SPN" SG_ 2163219712 Steering_Wheel_Angle_Range 3686;
BA_ "SPN" SG_ 2163219712 Steering_Angle_Sensor_Active_Mod 3687;
BA_ "SystemSignalLongSymbol" SG_ 2163219712 Steering_Angle_Sensor_Active_Mod "Steering Angle Sensor Active Mode";
BA_ "SPN" SG_ 2163219712 Steering_Angle_Sensor_Calibrated 3688;
BA_ "SPN" SG_ 2163219712 Message_Counter 3689;
BA_ "SPN" SG_ 2163219712 Message_Checksum 3690;
BA_ "SPN" SG_ 2163220736 Engine_Speed_1 4201;
BA_ "SPN" SG_ 2163220736 Engine_Speed_2 723;
BA_ "SPN" SG_ 2163220736 Engine_Speed_3 4202;
BA_ "SPN" SG_ 2163220736 Engine_Speed_Sensor_3_Timing_Pat 4205;
BA_ "SystemSignalLongSymbol" SG_ 2163220736 Engine_Speed_Sensor_3_Timing_Pat "Engine Speed Sensor 3 Timing Pattern Status";
BA_ "SPN" SG_ 2163220736 Engine_Speed_Sensor_2_Timing_Pat 4204;
BA_ "SystemSignalLongSymbol" SG_ 2163220736 Engine_Speed_Sensor_2_Timing_Pat "Engine Speed Sensor 2 Timing Pattern Status";
BA_ "SPN" SG_ 2163220736 Engine_Speed_Sensor_1_Timing_Pat 4203;
BA_ "SystemSignalLongSymbol" SG_ 2163220736 Engine_Speed_Sensor_1_Timing_Pat "Engine Speed Sensor 1 Timing Pattern Status";
BA_ "SPN" SG_ 2163221248 Aftertreatment_1_SCR_Actual_Dosi 4331;
BA_ "SystemSignalLongSymbol" SG_ 2163221248 Aftertreatment_1_SCR_Actual_Dosi "Aftertreatment 1 SCR Actual Dosing Reagent Quantity (instantaneous) ";
BA_ "SPN" SG_ 2163221248 Aftertreatment_1_SCR_System_Stat 4332;
BA_ "SystemSignalLongSymbol" SG_ 2163221248 Aftertreatment_1_SCR_System_Stat "Aftertreatment 1 SCR System State";
BA_ "SPN" SG_ 2163221248 Aftertreatment_1_SCR_Actual_Reag 4333;
BA_ "SystemSignalLongSymbol" SG_ 2163221248 Aftertreatment_1_SCR_Actual_Reag "Aftertreatment 1 SCR Actual Reagent Quantity of Integrator (integrator total value)";
BA_ "SPN" SG_ 2163221248 Aftertreatment_1_SCR_Dosing_Reag 4334;
BA_ "SystemSignalLongSymbol" SG_ 2163221248 Aftertreatment_1_SCR_Dosing_Reag "Aftertreatment 1 SCR Dosing Reagent Absolute Pressure";
BA_ "SPN" SG_ 2163221504 Aftertreatment_1_SCR_Requested_D 4348;
BA_ "SystemSignalLongSymbol" SG_ 2163221504 Aftertreatment_1_SCR_Requested_D "Aftertreatment 1 SCR Requested Dosing Reagent Quantity";
BA_ "SPN" SG_ 2163221504 Aftertreatment_1_SCR_System_Requ 4349;
BA_ "SystemSignalLongSymbol" SG_ 2163221504 Aftertreatment_1_SCR_System_Requ "Aftertreatment 1 SCR System Requested State";
BA_ "SPN" SG_ 2163221504 Aftertreatment_1_SCR_Requested_R 4350;
BA_ "SystemSignalLongSymbol" SG_ 2163221504 Aftertreatment_1_SCR_Requested_R "Aftertreatment 1 SCR Requested Reagent Quantity for Integrator (integrator total value)";
BA_ "SPN" SG_ 2163221760 Aftertreatment_1_Outlet_NH3 4377;
BA_ "SPN" SG_ 2163221760 Aftertreatment_1_Outlet_NH3_Sens 4378;
BA_ "SystemSignalLongSymbol" SG_ 2163221760 Aftertreatment_1_Outlet_NH3_Sens "Aftertreatment 1 Outlet NH3 Sensor Preliminary FMI";
BA_ "SPN" SG_ 2163221760 Aftertreatment_1_Outlet_NH3_Read 4379;
BA_ "SystemSignalLongSymbol" SG_ 2163221760 Aftertreatment_1_Outlet_NH3_Read "Aftertreatment 1 Outlet NH3 Reading Stable";
BA_ "SPN" SG_ 2163221760 Aftertreatment_1_Outlet_NH3_Gas_0 4380;
BA_ "SystemSignalLongSymbol" SG_ 2163221760 Aftertreatment_1_Outlet_NH3_Gas_0 "Aftertreatment 1 Outlet NH3 Gas Sensor Power In Range";
BA_ "SPN" SG_ 2163221760 Aftertreatment_1_Outlet_NH3_Gas_1 4381;
BA_ "SystemSignalLongSymbol" SG_ 2163221760 Aftertreatment_1_Outlet_NH3_Gas_1 "Aftertreatment 1 Outlet NH3 Gas Sensor at Temperature";
BA_ "SPN" SG_ 2163221760 Aftertreatment_1_Outlet_NH3_Gas_2 4382;
BA_ "SystemSignalLongSymbol" SG_ 2163221760 Aftertreatment_1_Outlet_NH3_Gas_2 "Aftertreatment 1 Outlet NH3 Gas Sensor Heater Preliminary FMI";
BA_ "SPN" SG_ 2163221760 Aftertreatment_1_Outlet_NH3_Gas_3 4383;
BA_ "SystemSignalLongSymbol" SG_ 2163221760 Aftertreatment_1_Outlet_NH3_Gas_3 "Aftertreatment 1 Outlet NH3 Gas Sensor Heater Control";
BA_ "SPN" SG_ 2163222016 Aftertreatment_2_SCR_Actual_Dosi 4384;
BA_ "SystemSignalLongSymbol" SG_ 2163222016 Aftertreatment_2_SCR_Actual_Dosi "Aftertreatment 2 SCR Actual Dosing Reagent Quantity (instantaneous) ";
BA_ "SPN" SG_ 2163222016 Aftertreatment_2_SCR_System_Stat 4385;
BA_ "SystemSignalLongSymbol" SG_ 2163222016 Aftertreatment_2_SCR_System_Stat "Aftertreatment 2 SCR System State";
BA_ "SPN" SG_ 2163222016 Aftertreatment_2_SCR_Actual_Reag 4386;
BA_ "SystemSignalLongSymbol" SG_ 2163222016 Aftertreatment_2_SCR_Actual_Reag "Aftertreatment 2 SCR Actual Reagent Quantity of Integrator (integrator feedback)";
BA_ "SPN" SG_ 2163222016 Aftertreatment_2_SCR_Dosing_Reag 4387;
BA_ "SystemSignalLongSymbol" SG_ 2163222016 Aftertreatment_2_SCR_Dosing_Reag "Aftertreatment 2 SCR Dosing Reagent Absolute Pressure";
BA_ "SPN" SG_ 2163222272 Aftertreatment_2_SCR_Requested_D 4401;
BA_ "SystemSignalLongSymbol" SG_ 2163222272 Aftertreatment_2_SCR_Requested_D "Aftertreatment 2 SCR Requested Dosing Reagent Quantity";
BA_ "SPN" SG_ 2163222272 Aftertreatment_2_SCR_System_Requ 4402;
BA_ "SystemSignalLongSymbol" SG_ 2163222272 Aftertreatment_2_SCR_System_Requ "Aftertreatment 2 SCR System Requested State";
BA_ "SPN" SG_ 2163222272 Aftertreatment_2_SCR_Requested_R 4403;
BA_ "SystemSignalLongSymbol" SG_ 2163222272 Aftertreatment_2_SCR_Requested_R "Aftertreatment 2 SCR Requested Reagent Quantity for Integrator (integrator total value)";
BA_ "SPN" SG_ 2163222528 Aftertreatment_2_Outlet_NH3 4443;
BA_ "SPN" SG_ 2163222528 Aftertreatment_2_Outlet_NH3_Sens 4444;
BA_ "SystemSignalLongSymbol" SG_ 2163222528 Aftertreatment_2_Outlet_NH3_Sens "Aftertreatment 2 Outlet NH3 Sensor Preliminary FMI";
BA_ "SPN" SG_ 2163222528 Aftertreatment_2_Outlet_NH3_Read 4445;
BA_ "SystemSignalLongSymbol" SG_ 2163222528 Aftertreatment_2_Outlet_NH3_Read "Aftertreatment 2 Outlet NH3 Reading Stable";
BA_ "SPN" SG_ 2163222528 Aftertreatment_2_Outlet_NH3_Gas_0 4446;
BA_ "SystemSignalLongSymbol" SG_ 2163222528 Aftertreatment_2_Outlet_NH3_Gas_0 "Aftertreatment 2 Outlet NH3 Gas Sensor Power In Range";
BA_ "SPN" SG_ 2163222528 Aftertreatment_2_Outlet_NH3_Gas_1 4447;
BA_ "SystemSignalLongSymbol" SG_ 2163222528 Aftertreatment_2_Outlet_NH3_Gas_1 "Aftertreatment 2 Outlet NH3 Gas Sensor at Temperature";
BA_ "SPN" SG_ 2163222528 Aftertreatment_2_Outlet_NH3_Gas_2 4448;
BA_ "SystemSignalLongSymbol" SG_ 2163222528 Aftertreatment_2_Outlet_NH3_Gas_2 "Aftertreatment 2 Outlet NH3 Gas Sensor Heater Preliminary FMI";
BA_ "SPN" SG_ 2163222528 Aftertreatment_2_Outlet_NH3_Gas_3 4449;
BA_ "SystemSignalLongSymbol" SG_ 2163222528 Aftertreatment_2_Outlet_NH3_Gas_3 "Aftertreatment 2 Outlet NH3 Gas Sensor Heater Control";
BA_ "SPN" SG_ 2164073216 Joystick_10_Grip_X_Axis_Neutral_ 4735;
BA_ "SystemSignalLongSymbol" SG_ 2164073216 Joystick_10_Grip_X_Axis_Neutral_ "Joystick 10 Grip X-Axis Neutral Position Status";
BA_ "SPN" SG_ 2164073216 Joystick_10_Grip_X_Axis_Lever_Le 4736;
BA_ "SystemSignalLongSymbol" SG_ 2164073216 Joystick_10_Grip_X_Axis_Lever_Le "Joystick 10 Grip X-Axis Lever Left Negative Position Status";
BA_ "SPN" SG_ 2164073216 Joystick_10_Grip_X_Axis_Lever_Ri 4737;
BA_ "SystemSignalLongSymbol" SG_ 2164073216 Joystick_10_Grip_X_Axis_Lever_Ri "Joystick 10 Grip X-Axis Lever Right Positive Position Status";
BA_ "SPN" SG_ 2164073216 Joystick_10_Grip_X_Axis_Position 4738;
BA_ "SPN" SG_ 2164073216 Joystick_10_Grip_Y_Axis_Neutral_ 4739;
BA_ "SystemSignalLongSymbol" SG_ 2164073216 Joystick_10_Grip_Y_Axis_Neutral_ "Joystick 10 Grip Y-Axis Neutral Position Status";
BA_ "SPN" SG_ 2164073216 Joystick_10_Grip_Y_Axis_Lever_Ba 4740;
BA_ "SystemSignalLongSymbol" SG_ 2164073216 Joystick_10_Grip_Y_Axis_Lever_Ba "Joystick 10 Grip Y-Axis Lever Back Negative Position Status";
BA_ "SPN" SG_ 2164073216 Joystick_10_Grip_Y_Axis_Lever_Fo 4741;
BA_ "SystemSignalLongSymbol" SG_ 2164073216 Joystick_10_Grip_Y_Axis_Lever_Fo "Joystick 10 Grip Y-Axis Lever Forward Positive Position Status";
BA_ "SPN" SG_ 2164073216 Joystick_10_Grip_Y_Axis_Position 4742;
BA_ "SPN" SG_ 2164073216 Joystick_10_Theta_Axis_Neutral_P 4743;
BA_ "SystemSignalLongSymbol" SG_ 2164073216 Joystick_10_Theta_Axis_Neutral_P "Joystick 10 Theta-Axis Neutral Position Status";
BA_ "SPN" SG_ 2164073216 Joystick_10_Theta_Axis_Counter_C 4744;
BA_ "SystemSignalLongSymbol" SG_ 2164073216 Joystick_10_Theta_Axis_Counter_C "Joystick 10 Theta-Axis Counter Clockwise Negative Position Status";
BA_ "SPN" SG_ 2164073216 Joystick_10_Theta_Axis_Clockwise 4745;
BA_ "SystemSignalLongSymbol" SG_ 2164073216 Joystick_10_Theta_Axis_Clockwise "Joystick 10 Theta-Axis Clockwise Positive Position Status";
BA_ "SPN" SG_ 2164073216 Joystick_10_Theta_Axis_Position 4746;
BA_ "SPN" SG_ 2164073216 Joystick_10_Theta_Axis_Detent_Po 4747;
BA_ "SystemSignalLongSymbol" SG_ 2164073216 Joystick_10_Theta_Axis_Detent_Po "Joystick 10 Theta-Axis Detent Position Status";
BA_ "SPN" SG_ 2164073216 Joystick_10_Grip_Y_Axis_Detent_P 4748;
BA_ "SystemSignalLongSymbol" SG_ 2164073216 Joystick_10_Grip_Y_Axis_Detent_P "Joystick 10 Grip Y-Axis Detent Position Status";
BA_ "SPN" SG_ 2164073216 Joystick_10_Grip_X_Axis_Detent_P 4749;
BA_ "SystemSignalLongSymbol" SG_ 2164073216 Joystick_10_Grip_X_Axis_Detent_P "Joystick 10 Grip X-Axis Detent Position Status";
BA_ "SPN" SG_ 2164073472 Joystick_10_X_Axis_Neutral_Posit 4713;
BA_ "SystemSignalLongSymbol" SG_ 2164073472 Joystick_10_X_Axis_Neutral_Posit "Joystick 10 X-Axis Neutral Position Status";
BA_ "SPN" SG_ 2164073472 Joystick_10_X_Axis_Lever_Left_Ne 4714;
BA_ "SystemSignalLongSymbol" SG_ 2164073472 Joystick_10_X_Axis_Lever_Left_Ne "Joystick 10 X-Axis Lever Left Negative Position Status";
BA_ "SPN" SG_ 2164073472 Joystick_10_X_Axis_Lever_Right_P 4715;
BA_ "SystemSignalLongSymbol" SG_ 2164073472 Joystick_10_X_Axis_Lever_Right_P "Joystick 10 X-Axis Lever Right Positive Position Status";
BA_ "SPN" SG_ 2164073472 Joystick_10_X_Axis_Position 4716;
BA_ "SPN" SG_ 2164073472 Joystick_10_Y_Axis_Neutral_Posit 4717;
BA_ "SystemSignalLongSymbol" SG_ 2164073472 Joystick_10_Y_Axis_Neutral_Posit "Joystick 10 Y-Axis Neutral Position Status";
BA_ "SPN" SG_ 2164073472 Joystick_10_Y_Axis_Lever_Back_Ne 4718;
BA_ "SystemSignalLongSymbol" SG_ 2164073472 Joystick_10_Y_Axis_Lever_Back_Ne "Joystick 10 Y-Axis Lever Back Negative Position Status";
BA_ "SPN" SG_ 2164073472 Joystick_10_Y_Axis_Lever_Forward 4719;
BA_ "SystemSignalLongSymbol" SG_ 2164073472 Joystick_10_Y_Axis_Lever_Forward "Joystick 10 Y-Axis Lever Forward Positive Position Status";
BA_ "SPN" SG_ 2164073472 Joystick_10_Y_Axis_Position 4720;
BA_ "SPN" SG_ 2164073472 Joystick_10_Y_Axis_Detent_Positi 4721;
BA_ "SystemSignalLongSymbol" SG_ 2164073472 Joystick_10_Y_Axis_Detent_Positi "Joystick 10 Y-Axis Detent Position Status";
BA_ "SPN" SG_ 2164073472 Joystick_10_X_Axis_Detent_Positi 4722;
BA_ "SystemSignalLongSymbol" SG_ 2164073472 Joystick_10_X_Axis_Detent_Positi "Joystick 10 X-Axis Detent Position Status";
BA_ "SPN" SG_ 2164073472 Joystick_10_Button_4_Pressed_Sta 4723;
BA_ "SystemSignalLongSymbol" SG_ 2164073472 Joystick_10_Button_4_Pressed_Sta "Joystick 10 Button 4 Pressed Status";
BA_ "SPN" SG_ 2164073472 Joystick_10_Button_3_Pressed_Sta 4724;
BA_ "SystemSignalLongSymbol" SG_ 2164073472 Joystick_10_Button_3_Pressed_Sta "Joystick 10 Button 3 Pressed Status";
BA_ "SPN" SG_ 2164073472 Joystick_10_Button_2_Pressed_Sta 4725;
BA_ "SystemSignalLongSymbol" SG_ 2164073472 Joystick_10_Button_2_Pressed_Sta "Joystick 10 Button 2 Pressed Status";
BA_ "SPN" SG_ 2164073472 Joystick_10_Button_1_Pressed_Sta 4726;
BA_ "SystemSignalLongSymbol" SG_ 2164073472 Joystick_10_Button_1_Pressed_Sta "Joystick 10 Button 1 Pressed Status";
BA_ "SPN" SG_ 2164073472 Joystick_10_Button_8_Pressed_Sta 4727;
BA_ "SystemSignalLongSymbol" SG_ 2164073472 Joystick_10_Button_8_Pressed_Sta "Joystick 10 Button 8 Pressed Status";
BA_ "SPN" SG_ 2164073472 Joystick_10_Button_7_Pressed_Sta 4728;
BA_ "SystemSignalLongSymbol" SG_ 2164073472 Joystick_10_Button_7_Pressed_Sta "Joystick 10 Button 7 Pressed Status";
BA_ "SPN" SG_ 2164073472 Joystick_10_Button_6_Pressed_Sta 4729;
BA_ "SystemSignalLongSymbol" SG_ 2164073472 Joystick_10_Button_6_Pressed_Sta "Joystick 10 Button 6 Pressed Status";
BA_ "SPN" SG_ 2164073472 Joystick_10_Button_5_Pressed_Sta 4730;
BA_ "SystemSignalLongSymbol" SG_ 2164073472 Joystick_10_Button_5_Pressed_Sta "Joystick 10 Button 5 Pressed Status";
BA_ "SPN" SG_ 2164073472 Joystick_10_Button_12_Pressed_St 4731;
BA_ "SystemSignalLongSymbol" SG_ 2164073472 Joystick_10_Button_12_Pressed_St "Joystick 10 Button 12 Pressed Status";
BA_ "SPN" SG_ 2164073472 Joystick_10_Button_11_Pressed_St 4732;
BA_ "SystemSignalLongSymbol" SG_ 2164073472 Joystick_10_Button_11_Pressed_St "Joystick 10 Button 11 Pressed Status";
BA_ "SPN" SG_ 2164073472 Joystick_10_Button_10_Pressed_St 4733;
BA_ "SystemSignalLongSymbol" SG_ 2164073472 Joystick_10_Button_10_Pressed_St "Joystick 10 Button 10 Pressed Status";
BA_ "SPN" SG_ 2164073472 Joystick_10_Button_9_Pressed_Sta 4734;
BA_ "SystemSignalLongSymbol" SG_ 2164073472 Joystick_10_Button_9_Pressed_Sta "Joystick 10 Button 9 Pressed Status";
BA_ "SPN" SG_ 2164073728 Joystick_9_Grip_X_Axis_Neutral_P 4698;
BA_ "SystemSignalLongSymbol" SG_ 2164073728 Joystick_9_Grip_X_Axis_Neutral_P "Joystick 9 Grip X-Axis Neutral Position Status";
BA_ "SPN" SG_ 2164073728 Joystick_9_Grip_X_Axis_Lever_Lef 4699;
BA_ "SystemSignalLongSymbol" SG_ 2164073728 Joystick_9_Grip_X_Axis_Lever_Lef "Joystick 9 Grip X-Axis Lever Left Negative Position Status";
BA_ "SPN" SG_ 2164073728 Joystick_9_Grip_X_Axis_Lever_Rig 4700;
BA_ "SystemSignalLongSymbol" SG_ 2164073728 Joystick_9_Grip_X_Axis_Lever_Rig "Joystick 9 Grip X-Axis Lever Right Positive Position Status";
BA_ "SPN" SG_ 2164073728 Joystick_9_Grip_X_Axis_Position 4701;
BA_ "SPN" SG_ 2164073728 Joystick_9_Grip_Y_Axis_Neutral_P 4702;
BA_ "SystemSignalLongSymbol" SG_ 2164073728 Joystick_9_Grip_Y_Axis_Neutral_P "Joystick 9 Grip Y-Axis Neutral Position Status";
BA_ "SPN" SG_ 2164073728 Joystick_9_Grip_Y_Axis_Lever_Bac 4703;
BA_ "SystemSignalLongSymbol" SG_ 2164073728 Joystick_9_Grip_Y_Axis_Lever_Bac "Joystick 9 Grip Y-Axis Lever Back Negative Position Status";
BA_ "SPN" SG_ 2164073728 Joystick_9_Grip_Y_Axis_Lever_For 4704;
BA_ "SystemSignalLongSymbol" SG_ 2164073728 Joystick_9_Grip_Y_Axis_Lever_For "Joystick 9 Grip Y-Axis Lever Forward Positive Position Status";
BA_ "SPN" SG_ 2164073728 Joystick_9_Grip_Y_Axis_Position 4705;
BA_ "SPN" SG_ 2164073728 Joystick_9_Theta_Axis_Neutral_Po 4706;
BA_ "SystemSignalLongSymbol" SG_ 2164073728 Joystick_9_Theta_Axis_Neutral_Po "Joystick 9 Theta-Axis Neutral Position Status";
BA_ "SPN" SG_ 2164073728 Joystick_9_Theta_Axis_Counter_Cl 4707;
BA_ "SystemSignalLongSymbol" SG_ 2164073728 Joystick_9_Theta_Axis_Counter_Cl "Joystick 9 Theta-Axis Counter Clockwise Negative Position Status";
BA_ "SPN" SG_ 2164073728 Joystick_9_Theta_Axis_Clockwise_ 4708;
BA_ "SystemSignalLongSymbol" SG_ 2164073728 Joystick_9_Theta_Axis_Clockwise_ "Joystick 9 Theta-Axis Clockwise Positive Position Status";
BA_ "SPN" SG_ 2164073728 Joystick_9_Theta_Axis_Position 4709;
BA_ "SPN" SG_ 2164073728 Joystick_9_Theta_Axis_Detent_Pos 4710;
BA_ "SystemSignalLongSymbol" SG_ 2164073728 Joystick_9_Theta_Axis_Detent_Pos "Joystick 9 Theta-Axis Detent Position Status";
BA_ "SPN" SG_ 2164073728 Joystick_9_Grip_Y_Axis_Detent_Po 4711;
BA_ "SystemSignalLongSymbol" SG_ 2164073728 Joystick_9_Grip_Y_Axis_Detent_Po "Joystick 9 Grip Y-Axis Detent Position Status";
BA_ "SPN" SG_ 2164073728 Joystick_9_Grip_X_Axis_Detent_Po 4712;
BA_ "SystemSignalLongSymbol" SG_ 2164073728 Joystick_9_Grip_X_Axis_Detent_Po "Joystick 9 Grip X-Axis Detent Position Status";
BA_ "SPN" SG_ 2164073984 Joystick_9_X_Axis_Neutral_Positi 4676;
BA_ "SystemSignalLongSymbol" SG_ 2164073984 Joystick_9_X_Axis_Neutral_Positi "Joystick 9 X-Axis Neutral Position Status";
BA_ "SPN" SG_ 2164073984 Joystick_9_X_Axis_Lever_Left_Neg 4677;
BA_ "SystemSignalLongSymbol" SG_ 2164073984 Joystick_9_X_Axis_Lever_Left_Neg "Joystick 9 X-Axis Lever Left Negative Position Status";
BA_ "SPN" SG_ 2164073984 Joystick_9_X_Axis_Lever_Right_Po 4678;
BA_ "SystemSignalLongSymbol" SG_ 2164073984 Joystick_9_X_Axis_Lever_Right_Po "Joystick 9 X-Axis Lever Right Positive Position Status";
BA_ "SPN" SG_ 2164073984 Joystick_9_X_Axis_Position 4679;
BA_ "SPN" SG_ 2164073984 Joystick_9_Y_Axis_Neutral_Positi 4680;
BA_ "SystemSignalLongSymbol" SG_ 2164073984 Joystick_9_Y_Axis_Neutral_Positi "Joystick 9 Y-Axis Neutral Position Status";
BA_ "SPN" SG_ 2164073984 Joystick_9_Y_Axis_Lever_Back_Neg 4681;
BA_ "SystemSignalLongSymbol" SG_ 2164073984 Joystick_9_Y_Axis_Lever_Back_Neg "Joystick 9 Y-Axis Lever Back Negative Position Status";
BA_ "SPN" SG_ 2164073984 Joystick_9_Y_Axis_Lever_Forward_ 4682;
BA_ "SystemSignalLongSymbol" SG_ 2164073984 Joystick_9_Y_Axis_Lever_Forward_ "Joystick 9 Y-Axis Lever Forward Positive Position Status";
BA_ "SPN" SG_ 2164073984 Joystick_9_Y_Axis_Position 4683;
BA_ "SPN" SG_ 2164073984 Joystick_9_Y_Axis_Detent_Positio 4684;
BA_ "SystemSignalLongSymbol" SG_ 2164073984 Joystick_9_Y_Axis_Detent_Positio "Joystick 9 Y-Axis Detent Position Status";
BA_ "SPN" SG_ 2164073984 Joystick_9_X_Axis_Detent_Positio 4685;
BA_ "SystemSignalLongSymbol" SG_ 2164073984 Joystick_9_X_Axis_Detent_Positio "Joystick 9 X-Axis Detent Position Status";
BA_ "SPN" SG_ 2164073984 Joystick_9_Button_4_Pressed_Stat 4686;
BA_ "SystemSignalLongSymbol" SG_ 2164073984 Joystick_9_Button_4_Pressed_Stat "Joystick 9 Button 4 Pressed Status";
BA_ "SPN" SG_ 2164073984 Joystick_9_Button_3_Pressed_Stat 4687;
BA_ "SystemSignalLongSymbol" SG_ 2164073984 Joystick_9_Button_3_Pressed_Stat "Joystick 9 Button 3 Pressed Status";
BA_ "SPN" SG_ 2164073984 Joystick_9_Button_2_Pressed_Stat 4688;
BA_ "SystemSignalLongSymbol" SG_ 2164073984 Joystick_9_Button_2_Pressed_Stat "Joystick 9 Button 2 Pressed Status";
BA_ "SPN" SG_ 2164073984 Joystick_9_Button_1_Pressed_Stat 4689;
BA_ "SystemSignalLongSymbol" SG_ 2164073984 Joystick_9_Button_1_Pressed_Stat "Joystick 9 Button 1 Pressed Status";
BA_ "SPN" SG_ 2164073984 Joystick_9_Button_8_Pressed_Stat 4690;
BA_ "SystemSignalLongSymbol" SG_ 2164073984 Joystick_9_Button_8_Pressed_Stat "Joystick 9 Button 8 Pressed Status";
BA_ "SPN" SG_ 2164073984 Joystick_9_Button_7_Pressed_Stat 4691;
BA_ "SystemSignalLongSymbol" SG_ 2164073984 Joystick_9_Button_7_Pressed_Stat "Joystick 9 Button 7 Pressed Status";
BA_ "SPN" SG_ 2164073984 Joystick_9_Button_6_Pressed_Stat 4692;
BA_ "SystemSignalLongSymbol" SG_ 2164073984 Joystick_9_Button_6_Pressed_Stat "Joystick 9 Button 6 Pressed Status";
BA_ "SPN" SG_ 2164073984 Joystick_9_Button_5_Pressed_Stat 4693;
BA_ "SystemSignalLongSymbol" SG_ 2164073984 Joystick_9_Button_5_Pressed_Stat "Joystick 9 Button 5 Pressed Status";
BA_ "SPN" SG_ 2164073984 Joystick_9_Button_12_Pressed_Sta 4694;
BA_ "SystemSignalLongSymbol" SG_ 2164073984 Joystick_9_Button_12_Pressed_Sta "Joystick 9 Button 12 Pressed Status";
BA_ "SPN" SG_ 2164073984 Joystick_9_Button_11_Pressed_Sta 4695;
BA_ "SystemSignalLongSymbol" SG_ 2164073984 Joystick_9_Button_11_Pressed_Sta "Joystick 9 Button 11 Pressed Status";
BA_ "SPN" SG_ 2164073984 Joystick_9_Button_10_Pressed_Sta 4696;
BA_ "SystemSignalLongSymbol" SG_ 2164073984 Joystick_9_Button_10_Pressed_Sta "Joystick 9 Button 10 Pressed Status";
BA_ "SPN" SG_ 2164073984 Joystick_9_Button_9_Pressed_Stat 4697;
BA_ "SystemSignalLongSymbol" SG_ 2164073984 Joystick_9_Button_9_Pressed_Stat "Joystick 9 Button 9 Pressed Status";
BA_ "SPN" SG_ 2164074240 Joystick_8_Grip_X_Axis_Neutral_P 4661;
BA_ "SystemSignalLongSymbol" SG_ 2164074240 Joystick_8_Grip_X_Axis_Neutral_P "Joystick 8 Grip X-Axis Neutral Position Status";
BA_ "SPN" SG_ 2164074240 Joystick_8_Grip_X_Axis_Lever_Lef 4662;
BA_ "SystemSignalLongSymbol" SG_ 2164074240 Joystick_8_Grip_X_Axis_Lever_Lef "Joystick 8 Grip X-Axis Lever Left Negative Position Status";
BA_ "SPN" SG_ 2164074240 Joystick_8_Grip_X_Axis_Lever_Rig 4663;
BA_ "SystemSignalLongSymbol" SG_ 2164074240 Joystick_8_Grip_X_Axis_Lever_Rig "Joystick 8 Grip X-Axis Lever Right Positive Position Status";
BA_ "SPN" SG_ 2164074240 Joystick_8_Grip_X_Axis_Position 4664;
BA_ "SPN" SG_ 2164074240 Joystick_8_Grip_Y_Axis_Neutral_P 4665;
BA_ "SystemSignalLongSymbol" SG_ 2164074240 Joystick_8_Grip_Y_Axis_Neutral_P "Joystick 8 Grip Y-Axis Neutral Position Status";
BA_ "SPN" SG_ 2164074240 Joystick_8_Grip_Y_Axis_Lever_Bac 4666;
BA_ "SystemSignalLongSymbol" SG_ 2164074240 Joystick_8_Grip_Y_Axis_Lever_Bac "Joystick 8 Grip Y-Axis Lever Back Negative Position Status";
BA_ "SPN" SG_ 2164074240 Joystick_8_Grip_Y_Axis_Lever_For 4667;
BA_ "SystemSignalLongSymbol" SG_ 2164074240 Joystick_8_Grip_Y_Axis_Lever_For "Joystick 8 Grip Y-Axis Lever Forward Positive Position Status";
BA_ "SPN" SG_ 2164074240 Joystick_8_Grip_Y_Axis_Position 4668;
BA_ "SPN" SG_ 2164074240 Joystick_8_Theta_Axis_Neutral_Po 4669;
BA_ "SystemSignalLongSymbol" SG_ 2164074240 Joystick_8_Theta_Axis_Neutral_Po "Joystick 8 Theta-Axis Neutral Position Status";
BA_ "SPN" SG_ 2164074240 Joystick_8_Theta_Axis_Counter_Cl 4670;
BA_ "SystemSignalLongSymbol" SG_ 2164074240 Joystick_8_Theta_Axis_Counter_Cl "Joystick 8 Theta-Axis Counter Clockwise Negative Position Status";
BA_ "SPN" SG_ 2164074240 Joystick_8_Theta_Axis_Clockwise_ 4671;
BA_ "SystemSignalLongSymbol" SG_ 2164074240 Joystick_8_Theta_Axis_Clockwise_ "Joystick 8 Theta-Axis Clockwise Positive Position Status";
BA_ "SPN" SG_ 2164074240 Joystick_8_Theta_Axis_Position 4672;
BA_ "SPN" SG_ 2164074240 Joystick_8_Theta_Axis_Detent_Pos 4673;
BA_ "SystemSignalLongSymbol" SG_ 2164074240 Joystick_8_Theta_Axis_Detent_Pos "Joystick 8 Theta-Axis Detent Position Status";
BA_ "SPN" SG_ 2164074240 Joystick_8_Grip_Y_Axis_Detent_Po 4674;
BA_ "SystemSignalLongSymbol" SG_ 2164074240 Joystick_8_Grip_Y_Axis_Detent_Po "Joystick 8 Grip Y-Axis Detent Position Status";
BA_ "SPN" SG_ 2164074240 Joystick_8_Grip_X_Axis_Detent_Po 4675;
BA_ "SystemSignalLongSymbol" SG_ 2164074240 Joystick_8_Grip_X_Axis_Detent_Po "Joystick 8 Grip X-Axis Detent Position Status";
BA_ "SPN" SG_ 2164074496 Joystick_8_X_Axis_Neutral_Positi 4639;
BA_ "SystemSignalLongSymbol" SG_ 2164074496 Joystick_8_X_Axis_Neutral_Positi "Joystick 8 X-Axis Neutral Position Status";
BA_ "SPN" SG_ 2164074496 Joystick_8_X_Axis_Lever_Left_Neg 4640;
BA_ "SystemSignalLongSymbol" SG_ 2164074496 Joystick_8_X_Axis_Lever_Left_Neg "Joystick 8 X-Axis Lever Left Negative Position Status";
BA_ "SPN" SG_ 2164074496 Joystick_8_X_Axis_Lever_Right_Po 4641;
BA_ "SystemSignalLongSymbol" SG_ 2164074496 Joystick_8_X_Axis_Lever_Right_Po "Joystick 8 X-Axis Lever Right Positive Position Status";
BA_ "SPN" SG_ 2164074496 Joystick_8_X_Axis_Position 4642;
BA_ "SPN" SG_ 2164074496 Joystick_8_Y_Axis_Neutral_Positi 4643;
BA_ "SystemSignalLongSymbol" SG_ 2164074496 Joystick_8_Y_Axis_Neutral_Positi "Joystick 8 Y-Axis Neutral Position Status";
BA_ "SPN" SG_ 2164074496 Joystick_8_Y_Axis_Lever_Back_Neg 4644;
BA_ "SystemSignalLongSymbol" SG_ 2164074496 Joystick_8_Y_Axis_Lever_Back_Neg "Joystick 8 Y-Axis Lever Back Negative Position Status";
BA_ "SPN" SG_ 2164074496 Joystick_8_Y_Axis_Lever_Forward_ 4645;
BA_ "SystemSignalLongSymbol" SG_ 2164074496 Joystick_8_Y_Axis_Lever_Forward_ "Joystick 8 Y-Axis Lever Forward Positive Position Status";
BA_ "SPN" SG_ 2164074496 Joystick_8_Y_Axis_Position 4646;
BA_ "SPN" SG_ 2164074496 Joystick_8_Y_Axis_Detent_Positio 4647;
BA_ "SystemSignalLongSymbol" SG_ 2164074496 Joystick_8_Y_Axis_Detent_Positio "Joystick 8 Y-Axis Detent Position Status";
BA_ "SPN" SG_ 2164074496 Joystick_8_X_Axis_Detent_Positio 4648;
BA_ "SystemSignalLongSymbol" SG_ 2164074496 Joystick_8_X_Axis_Detent_Positio "Joystick 8 X-Axis Detent Position Status";
BA_ "SPN" SG_ 2164074496 Joystick_8_Button_4_Pressed_Stat 4649;
BA_ "SystemSignalLongSymbol" SG_ 2164074496 Joystick_8_Button_4_Pressed_Stat "Joystick 8 Button 4 Pressed Status";
BA_ "SPN" SG_ 2164074496 Joystick_8_Button_3_Pressed_Stat 4650;
BA_ "SystemSignalLongSymbol" SG_ 2164074496 Joystick_8_Button_3_Pressed_Stat "Joystick 8 Button 3 Pressed Status";
BA_ "SPN" SG_ 2164074496 Joystick_8_Button_2_Pressed_Stat 4651;
BA_ "SystemSignalLongSymbol" SG_ 2164074496 Joystick_8_Button_2_Pressed_Stat "Joystick 8 Button 2 Pressed Status";
BA_ "SPN" SG_ 2164074496 Joystick_8_Button_1_Pressed_Stat 4652;
BA_ "SystemSignalLongSymbol" SG_ 2164074496 Joystick_8_Button_1_Pressed_Stat "Joystick 8 Button 1 Pressed Status";
BA_ "SPN" SG_ 2164074496 Joystick_8_Button_8_Pressed_Stat 4653;
BA_ "SystemSignalLongSymbol" SG_ 2164074496 Joystick_8_Button_8_Pressed_Stat "Joystick 8 Button 8 Pressed Status";
BA_ "SPN" SG_ 2164074496 Joystick_8_Button_7_Pressed_Stat 4654;
BA_ "SystemSignalLongSymbol" SG_ 2164074496 Joystick_8_Button_7_Pressed_Stat "Joystick 8 Button 7 Pressed Status";
BA_ "SPN" SG_ 2164074496 Joystick_8_Button_6_Pressed_Stat 4655;
BA_ "SystemSignalLongSymbol" SG_ 2164074496 Joystick_8_Button_6_Pressed_Stat "Joystick 8 Button 6 Pressed Status";
BA_ "SPN" SG_ 2164074496 Joystick_8_Button_5_Pressed_Stat 4656;
BA_ "SystemSignalLongSymbol" SG_ 2164074496 Joystick_8_Button_5_Pressed_Stat "Joystick 8 Button 5 Pressed Status";
BA_ "SPN" SG_ 2164074496 Joystick_8_Button_12_Pressed_Sta 4657;
BA_ "SystemSignalLongSymbol" SG_ 2164074496 Joystick_8_Button_12_Pressed_Sta "Joystick 8 Button 12 Pressed Status";
BA_ "SPN" SG_ 2164074496 Joystick_8_Button_11_Pressed_Sta 4658;
BA_ "SystemSignalLongSymbol" SG_ 2164074496 Joystick_8_Button_11_Pressed_Sta "Joystick 8 Button 11 Pressed Status";
BA_ "SPN" SG_ 2164074496 Joystick_8_Button_10_Pressed_Sta 4659;
BA_ "SystemSignalLongSymbol" SG_ 2164074496 Joystick_8_Button_10_Pressed_Sta "Joystick 8 Button 10 Pressed Status";
BA_ "SPN" SG_ 2164074496 Joystick_8_Button_9_Pressed_Stat 4660;
BA_ "SystemSignalLongSymbol" SG_ 2164074496 Joystick_8_Button_9_Pressed_Stat "Joystick 8 Button 9 Pressed Status";
BA_ "SPN" SG_ 2164074752 Joystick_7_Grip_X_Axis_Neutral_P 4624;
BA_ "SystemSignalLongSymbol" SG_ 2164074752 Joystick_7_Grip_X_Axis_Neutral_P "Joystick 7 Grip X-Axis Neutral Position Status";
BA_ "SPN" SG_ 2164074752 Joystick_7_Grip_X_Axis_Lever_Lef 4625;
BA_ "SystemSignalLongSymbol" SG_ 2164074752 Joystick_7_Grip_X_Axis_Lever_Lef "Joystick 7 Grip X-Axis Lever Left Negative Position Status";
BA_ "SPN" SG_ 2164074752 Joystick_7_Grip_X_Axis_Lever_Rig 4626;
BA_ "SystemSignalLongSymbol" SG_ 2164074752 Joystick_7_Grip_X_Axis_Lever_Rig "Joystick 7 Grip X-Axis Lever Right Positive Position Status";
BA_ "SPN" SG_ 2164074752 Joystick_7_Grip_X_Axis_Position 4627;
BA_ "SPN" SG_ 2164074752 Joystick_7_Grip_Y_Axis_Neutral_P 4628;
BA_ "SystemSignalLongSymbol" SG_ 2164074752 Joystick_7_Grip_Y_Axis_Neutral_P "Joystick 7 Grip Y-Axis Neutral Position Status";
BA_ "SPN" SG_ 2164074752 Joystick_7_Grip_Y_Axis_Lever_Bac 4629;
BA_ "SystemSignalLongSymbol" SG_ 2164074752 Joystick_7_Grip_Y_Axis_Lever_Bac "Joystick 7 Grip Y-Axis Lever Back Negative Position Status";
BA_ "SPN" SG_ 2164074752 Joystick_7_Grip_Y_Axis_Lever_For 4630;
BA_ "SystemSignalLongSymbol" SG_ 2164074752 Joystick_7_Grip_Y_Axis_Lever_For "Joystick 7 Grip Y-Axis Lever Forward Positive Position Status";
BA_ "SPN" SG_ 2164074752 Joystick_7_Grip_Y_Axis_Position 4631;
BA_ "SPN" SG_ 2164074752 Joystick_7_Theta_Axis_Neutral_Po 4632;
BA_ "SystemSignalLongSymbol" SG_ 2164074752 Joystick_7_Theta_Axis_Neutral_Po "Joystick 7 Theta-Axis Neutral Position Status";
BA_ "SPN" SG_ 2164074752 Joystick_7_Theta_Axis_Counter_Cl 4633;
BA_ "SystemSignalLongSymbol" SG_ 2164074752 Joystick_7_Theta_Axis_Counter_Cl "Joystick 7 Theta-Axis Counter Clockwise Negative Position Status";
BA_ "SPN" SG_ 2164074752 Joystick_7_Theta_Axis_Clockwise_ 4634;
BA_ "SystemSignalLongSymbol" SG_ 2164074752 Joystick_7_Theta_Axis_Clockwise_ "Joystick 7 Theta-Axis Clockwise Positive Position Status";
BA_ "SPN" SG_ 2164074752 Joystick_7_Theta_Axis_Position 4635;
BA_ "SPN" SG_ 2164074752 Joystick_7_Theta_Axis_Detent_Pos 4636;
BA_ "SystemSignalLongSymbol" SG_ 2164074752 Joystick_7_Theta_Axis_Detent_Pos "Joystick 7 Theta-Axis Detent Position Status";
BA_ "SPN" SG_ 2164074752 Joystick_7_Grip_Y_Axis_Detent_Po 4637;
BA_ "SystemSignalLongSymbol" SG_ 2164074752 Joystick_7_Grip_Y_Axis_Detent_Po "Joystick 7 Grip Y-Axis Detent Position Status";
BA_ "SPN" SG_ 2164074752 Joystick_7_Grip_X_Axis_Detent_Po 4638;
BA_ "SystemSignalLongSymbol" SG_ 2164074752 Joystick_7_Grip_X_Axis_Detent_Po "Joystick 7 Grip X-Axis Detent Position Status";
BA_ "SPN" SG_ 2164075008 Joystick_7_X_Axis_Neutral_Positi 4602;
BA_ "SystemSignalLongSymbol" SG_ 2164075008 Joystick_7_X_Axis_Neutral_Positi "Joystick 7 X-Axis Neutral Position Status";
BA_ "SPN" SG_ 2164075008 Joystick_7_X_Axis_Lever_Left_Neg 4603;
BA_ "SystemSignalLongSymbol" SG_ 2164075008 Joystick_7_X_Axis_Lever_Left_Neg "Joystick 7 X-Axis Lever Left Negative Position Status";
BA_ "SPN" SG_ 2164075008 Joystick_7_X_Axis_Lever_Right_Po 4604;
BA_ "SystemSignalLongSymbol" SG_ 2164075008 Joystick_7_X_Axis_Lever_Right_Po "Joystick 7 X-Axis Lever Right Positive Position Status";
BA_ "SPN" SG_ 2164075008 Joystick_7_X_Axis_Position 4605;
BA_ "SPN" SG_ 2164075008 Joystick_7_Y_Axis_Neutral_Positi 4606;
BA_ "SystemSignalLongSymbol" SG_ 2164075008 Joystick_7_Y_Axis_Neutral_Positi "Joystick 7 Y-Axis Neutral Position Status";
BA_ "SPN" SG_ 2164075008 Joystick_7_Y_Axis_Lever_Back_Neg 4607;
BA_ "SystemSignalLongSymbol" SG_ 2164075008 Joystick_7_Y_Axis_Lever_Back_Neg "Joystick 7 Y-Axis Lever Back Negative Position Status";
BA_ "SPN" SG_ 2164075008 Joystick_7_Y_Axis_Lever_Forward_ 4608;
BA_ "SystemSignalLongSymbol" SG_ 2164075008 Joystick_7_Y_Axis_Lever_Forward_ "Joystick 7 Y-Axis Lever Forward Positive Position Status";
BA_ "SPN" SG_ 2164075008 Joystick_7_Y_Axis_Position 4609;
BA_ "SPN" SG_ 2164075008 Joystick_7_Y_Axis_Detent_Positio 4610;
BA_ "SystemSignalLongSymbol" SG_ 2164075008 Joystick_7_Y_Axis_Detent_Positio "Joystick 7 Y-Axis Detent Position Status";
BA_ "SPN" SG_ 2164075008 Joystick_7_X_Axis_Detent_Positio 4611;
BA_ "SystemSignalLongSymbol" SG_ 2164075008 Joystick_7_X_Axis_Detent_Positio "Joystick 7 X-Axis Detent Position Status";
BA_ "SPN" SG_ 2164075008 Joystick_7_Button_4_Pressed_Stat 4612;
BA_ "SystemSignalLongSymbol" SG_ 2164075008 Joystick_7_Button_4_Pressed_Stat "Joystick 7 Button 4 Pressed Status";
BA_ "SPN" SG_ 2164075008 Joystick_7_Button_3_Pressed_Stat 4613;
BA_ "SystemSignalLongSymbol" SG_ 2164075008 Joystick_7_Button_3_Pressed_Stat "Joystick 7 Button 3 Pressed Status";
BA_ "SPN" SG_ 2164075008 Joystick_7_Button_2_Pressed_Stat 4614;
BA_ "SystemSignalLongSymbol" SG_ 2164075008 Joystick_7_Button_2_Pressed_Stat "Joystick 7 Button 2 Pressed Status";
BA_ "SPN" SG_ 2164075008 Joystick_7_Button_1_Pressed_Stat 4615;
BA_ "SystemSignalLongSymbol" SG_ 2164075008 Joystick_7_Button_1_Pressed_Stat "Joystick 7 Button 1 Pressed Status";
BA_ "SPN" SG_ 2164075008 Joystick_7_Button_8_Pressed_Stat 4616;
BA_ "SystemSignalLongSymbol" SG_ 2164075008 Joystick_7_Button_8_Pressed_Stat "Joystick 7 Button 8 Pressed Status";
BA_ "SPN" SG_ 2164075008 Joystick_7_Button_7_Pressed_Stat 4617;
BA_ "SystemSignalLongSymbol" SG_ 2164075008 Joystick_7_Button_7_Pressed_Stat "Joystick 7 Button 7 Pressed Status";
BA_ "SPN" SG_ 2164075008 Joystick_7_Button_6_Pressed_Stat 4618;
BA_ "SystemSignalLongSymbol" SG_ 2164075008 Joystick_7_Button_6_Pressed_Stat "Joystick 7 Button 6 Pressed Status";
BA_ "SPN" SG_ 2164075008 Joystick_7_Button_5_Pressed_Stat 4619;
BA_ "SystemSignalLongSymbol" SG_ 2164075008 Joystick_7_Button_5_Pressed_Stat "Joystick 7 Button 5 Pressed Status";
BA_ "SPN" SG_ 2164075008 Joystick_7_Button_12_Pressed_Sta 4620;
BA_ "SystemSignalLongSymbol" SG_ 2164075008 Joystick_7_Button_12_Pressed_Sta "Joystick 7 Button 12 Pressed Status";
BA_ "SPN" SG_ 2164075008 Joystick_7_Button_11_Pressed_Sta 4621;
BA_ "SystemSignalLongSymbol" SG_ 2164075008 Joystick_7_Button_11_Pressed_Sta "Joystick 7 Button 11 Pressed Status";
BA_ "SPN" SG_ 2164075008 Joystick_7_Button_10_Pressed_Sta 4622;
BA_ "SystemSignalLongSymbol" SG_ 2164075008 Joystick_7_Button_10_Pressed_Sta "Joystick 7 Button 10 Pressed Status";
BA_ "SPN" SG_ 2164075008 Joystick_7_Button_9_Pressed_Stat 4623;
BA_ "SystemSignalLongSymbol" SG_ 2164075008 Joystick_7_Button_9_Pressed_Stat "Joystick 7 Button 9 Pressed Status";
BA_ "SPN" SG_ 2164075264 Joystick_6_Grip_X_Axis_Neutral_P 4587;
BA_ "SystemSignalLongSymbol" SG_ 2164075264 Joystick_6_Grip_X_Axis_Neutral_P "Joystick 6 Grip X-Axis Neutral Position Status";
BA_ "SPN" SG_ 2164075264 Joystick_6_Grip_X_Axis_Lever_Lef 4588;
BA_ "SystemSignalLongSymbol" SG_ 2164075264 Joystick_6_Grip_X_Axis_Lever_Lef "Joystick 6 Grip X-Axis Lever Left Negative Position Status";
BA_ "SPN" SG_ 2164075264 Joystick_6_Grip_X_Axis_Lever_Rig 4589;
BA_ "SystemSignalLongSymbol" SG_ 2164075264 Joystick_6_Grip_X_Axis_Lever_Rig "Joystick 6 Grip X-Axis Lever Right Positive Position Status";
BA_ "SPN" SG_ 2164075264 Joystick_6_Grip_X_Axis_Position 4590;
BA_ "SPN" SG_ 2164075264 Joystick_6_Grip_Y_Axis_Neutral_P 4591;
BA_ "SystemSignalLongSymbol" SG_ 2164075264 Joystick_6_Grip_Y_Axis_Neutral_P "Joystick 6 Grip Y-Axis Neutral Position Status";
BA_ "SPN" SG_ 2164075264 Joystick_6_Grip_Y_Axis_Lever_Bac 4592;
BA_ "SystemSignalLongSymbol" SG_ 2164075264 Joystick_6_Grip_Y_Axis_Lever_Bac "Joystick 6 Grip Y-Axis Lever Back Negative Position Status";
BA_ "SPN" SG_ 2164075264 Joystick_6_Grip_Y_Axis_Lever_For 4593;
BA_ "SystemSignalLongSymbol" SG_ 2164075264 Joystick_6_Grip_Y_Axis_Lever_For "Joystick 6 Grip Y-Axis Lever Forward Positive Position Status";
BA_ "SPN" SG_ 2164075264 Joystick_6_Grip_Y_Axis_Position 4594;
BA_ "SPN" SG_ 2164075264 Joystick_6_Theta_Axis_Neutral_Po 4595;
BA_ "SystemSignalLongSymbol" SG_ 2164075264 Joystick_6_Theta_Axis_Neutral_Po "Joystick 6 Theta-Axis Neutral Position Status";
BA_ "SPN" SG_ 2164075264 Joystick_6_Theta_Axis_Counter_Cl 4596;
BA_ "SystemSignalLongSymbol" SG_ 2164075264 Joystick_6_Theta_Axis_Counter_Cl "Joystick 6 Theta-Axis Counter Clockwise Negative Position Status";
BA_ "SPN" SG_ 2164075264 Joystick_6_Theta_Axis_Clockwise_ 4597;
BA_ "SystemSignalLongSymbol" SG_ 2164075264 Joystick_6_Theta_Axis_Clockwise_ "Joystick 6 Theta-Axis Clockwise Positive Position Status";
BA_ "SPN" SG_ 2164075264 Joystick_6_Theta_Axis_Position 4598;
BA_ "SPN" SG_ 2164075264 Joystick_6_Theta_Axis_Detent_Pos 4599;
BA_ "SystemSignalLongSymbol" SG_ 2164075264 Joystick_6_Theta_Axis_Detent_Pos "Joystick 6 Theta-Axis Detent Position Status";
BA_ "SPN" SG_ 2164075264 Joystick_6_Grip_Y_Axis_Detent_Po 4600;
BA_ "SystemSignalLongSymbol" SG_ 2164075264 Joystick_6_Grip_Y_Axis_Detent_Po "Joystick 6 Grip Y-Axis Detent Position Status";
BA_ "SPN" SG_ 2164075264 Joystick_6_Grip_X_Axis_Detent_Po 4601;
BA_ "SystemSignalLongSymbol" SG_ 2164075264 Joystick_6_Grip_X_Axis_Detent_Po "Joystick 6 Grip X-Axis Detent Position Status";
BA_ "SPN" SG_ 2164075520 Joystick_6_X_Axis_Neutral_Positi 4565;
BA_ "SystemSignalLongSymbol" SG_ 2164075520 Joystick_6_X_Axis_Neutral_Positi "Joystick 6 X-Axis Neutral Position Status";
BA_ "SPN" SG_ 2164075520 Joystick_6_X_Axis_Lever_Left_Neg 4566;
BA_ "SystemSignalLongSymbol" SG_ 2164075520 Joystick_6_X_Axis_Lever_Left_Neg "Joystick 6 X-Axis Lever Left Negative Position Status";
BA_ "SPN" SG_ 2164075520 Joystick_6_X_Axis_Lever_Right_Po 4567;
BA_ "SystemSignalLongSymbol" SG_ 2164075520 Joystick_6_X_Axis_Lever_Right_Po "Joystick 6 X-Axis Lever Right Positive Position Status";
BA_ "SPN" SG_ 2164075520 Joystick_6_X_Axis_Position 4568;
BA_ "SPN" SG_ 2164075520 Joystick_6_Y_Axis_Neutral_Positi 4569;
BA_ "SystemSignalLongSymbol" SG_ 2164075520 Joystick_6_Y_Axis_Neutral_Positi "Joystick 6 Y-Axis Neutral Position Status";
BA_ "SPN" SG_ 2164075520 Joystick_6_Y_Axis_Lever_Back_Neg 4570;
BA_ "SystemSignalLongSymbol" SG_ 2164075520 Joystick_6_Y_Axis_Lever_Back_Neg "Joystick 6 Y-Axis Lever Back Negative Position Status";
BA_ "SPN" SG_ 2164075520 Joystick_6_Y_Axis_Lever_Forward_ 4571;
BA_ "SystemSignalLongSymbol" SG_ 2164075520 Joystick_6_Y_Axis_Lever_Forward_ "Joystick 6 Y-Axis Lever Forward Positive Position Status";
BA_ "SPN" SG_ 2164075520 Joystick_6_Y_Axis_Position 4572;
BA_ "SPN" SG_ 2164075520 Joystick_6_Y_Axis_Detent_Positio 4573;
BA_ "SystemSignalLongSymbol" SG_ 2164075520 Joystick_6_Y_Axis_Detent_Positio "Joystick 6 Y-Axis Detent Position Status";
BA_ "SPN" SG_ 2164075520 Joystick_6_X_Axis_Detent_Positio 4574;
BA_ "SystemSignalLongSymbol" SG_ 2164075520 Joystick_6_X_Axis_Detent_Positio "Joystick 6 X-Axis Detent Position Status";
BA_ "SPN" SG_ 2164075520 Joystick_6_Button_4_Pressed_Stat 4575;
BA_ "SystemSignalLongSymbol" SG_ 2164075520 Joystick_6_Button_4_Pressed_Stat "Joystick 6 Button 4 Pressed Status";
BA_ "SPN" SG_ 2164075520 Joystick_6_Button_3_Pressed_Stat 4576;
BA_ "SystemSignalLongSymbol" SG_ 2164075520 Joystick_6_Button_3_Pressed_Stat "Joystick 6 Button 3 Pressed Status";
BA_ "SPN" SG_ 2164075520 Joystick_6_Button_2_Pressed_Stat 4577;
BA_ "SystemSignalLongSymbol" SG_ 2164075520 Joystick_6_Button_2_Pressed_Stat "Joystick 6 Button 2 Pressed Status";
BA_ "SPN" SG_ 2164075520 Joystick_6_Button_1_Pressed_Stat 4578;
BA_ "SystemSignalLongSymbol" SG_ 2164075520 Joystick_6_Button_1_Pressed_Stat "Joystick 6 Button 1 Pressed Status";
BA_ "SPN" SG_ 2164075520 Joystick_6_Button_8_Pressed_Stat 4579;
BA_ "SystemSignalLongSymbol" SG_ 2164075520 Joystick_6_Button_8_Pressed_Stat "Joystick 6 Button 8 Pressed Status";
BA_ "SPN" SG_ 2164075520 Joystick_6_Button_7_Pressed_Stat 4580;
BA_ "SystemSignalLongSymbol" SG_ 2164075520 Joystick_6_Button_7_Pressed_Stat "Joystick 6 Button 7 Pressed Status";
BA_ "SPN" SG_ 2164075520 Joystick_6_Button_6_Pressed_Stat 4581;
BA_ "SystemSignalLongSymbol" SG_ 2164075520 Joystick_6_Button_6_Pressed_Stat "Joystick 6 Button 6 Pressed Status";
BA_ "SPN" SG_ 2164075520 Joystick_6_Button_5_Pressed_Stat 4582;
BA_ "SystemSignalLongSymbol" SG_ 2164075520 Joystick_6_Button_5_Pressed_Stat "Joystick 6 Button 5 Pressed Status";
BA_ "SPN" SG_ 2164075520 Joystick_6_Button_12_Pressed_Sta 4583;
BA_ "SystemSignalLongSymbol" SG_ 2164075520 Joystick_6_Button_12_Pressed_Sta "Joystick 6 Button 12 Pressed Status";
BA_ "SPN" SG_ 2164075520 Joystick_6_Button_11_Pressed_Sta 4584;
BA_ "SystemSignalLongSymbol" SG_ 2164075520 Joystick_6_Button_11_Pressed_Sta "Joystick 6 Button 11 Pressed Status";
BA_ "SPN" SG_ 2164075520 Joystick_6_Button_10_Pressed_Sta 4585;
BA_ "SystemSignalLongSymbol" SG_ 2164075520 Joystick_6_Button_10_Pressed_Sta "Joystick 6 Button 10 Pressed Status";
BA_ "SPN" SG_ 2164075520 Joystick_6_Button_9_Pressed_Stat 4586;
BA_ "SystemSignalLongSymbol" SG_ 2164075520 Joystick_6_Button_9_Pressed_Stat "Joystick 6 Button 9 Pressed Status";
BA_ "SPN" SG_ 2164075776 Joystick_5_Grip_X_Axis_Neutral_P 4550;
BA_ "SystemSignalLongSymbol" SG_ 2164075776 Joystick_5_Grip_X_Axis_Neutral_P "Joystick 5 Grip X-Axis Neutral Position Status";
BA_ "SPN" SG_ 2164075776 Joystick_5_Grip_X_Axis_Lever_Lef 4551;
BA_ "SystemSignalLongSymbol" SG_ 2164075776 Joystick_5_Grip_X_Axis_Lever_Lef "Joystick 5 Grip X-Axis Lever Left Negative Position Status";
BA_ "SPN" SG_ 2164075776 Joystick_5_Grip_X_Axis_Lever_Rig 4552;
BA_ "SystemSignalLongSymbol" SG_ 2164075776 Joystick_5_Grip_X_Axis_Lever_Rig "Joystick 5 Grip X-Axis Lever Right Positive Position Status";
BA_ "SPN" SG_ 2164075776 Joystick_5_Grip_X_Axis_Position 4553;
BA_ "SPN" SG_ 2164075776 Joystick_5_Grip_Y_Axis_Neutral_P 4554;
BA_ "SystemSignalLongSymbol" SG_ 2164075776 Joystick_5_Grip_Y_Axis_Neutral_P "Joystick 5 Grip Y-Axis Neutral Position Status";
BA_ "SPN" SG_ 2164075776 Joystick_5_Grip_Y_Axis_Lever_Bac 4555;
BA_ "SystemSignalLongSymbol" SG_ 2164075776 Joystick_5_Grip_Y_Axis_Lever_Bac "Joystick 5 Grip Y-Axis Lever Back Negative Position Status";
BA_ "SPN" SG_ 2164075776 Joystick_5_Grip_Y_Axis_Lever_For 4556;
BA_ "SystemSignalLongSymbol" SG_ 2164075776 Joystick_5_Grip_Y_Axis_Lever_For "Joystick 5 Grip Y-Axis Lever Forward Positive Position Status";
BA_ "SPN" SG_ 2164075776 Joystick_5_Grip_Y_Axis_Position 4557;
BA_ "SPN" SG_ 2164075776 Joystick_5_Theta_Axis_Neutral_Po 4558;
BA_ "SystemSignalLongSymbol" SG_ 2164075776 Joystick_5_Theta_Axis_Neutral_Po "Joystick 5 Theta-Axis Neutral Position Status";
BA_ "SPN" SG_ 2164075776 Joystick_5_Theta_Axis_Counter_Cl 4559;
BA_ "SystemSignalLongSymbol" SG_ 2164075776 Joystick_5_Theta_Axis_Counter_Cl "Joystick 5 Theta-Axis Counter Clockwise Negative Position Status";
BA_ "SPN" SG_ 2164075776 Joystick_5_Theta_Axis_Clockwise_ 4560;
BA_ "SystemSignalLongSymbol" SG_ 2164075776 Joystick_5_Theta_Axis_Clockwise_ "Joystick 5 Theta-Axis Clockwise Positive Position Status";
BA_ "SPN" SG_ 2164075776 Joystick_5_Theta_Axis_Position 4561;
BA_ "SPN" SG_ 2164075776 Joystick_5_Theta_Axis_Detent_Pos 4562;
BA_ "SystemSignalLongSymbol" SG_ 2164075776 Joystick_5_Theta_Axis_Detent_Pos "Joystick 5 Theta-Axis Detent Position Status";
BA_ "SPN" SG_ 2164075776 Joystick_5_Grip_Y_Axis_Detent_Po 4563;
BA_ "SystemSignalLongSymbol" SG_ 2164075776 Joystick_5_Grip_Y_Axis_Detent_Po "Joystick 5 Grip Y-Axis Detent Position Status";
BA_ "SPN" SG_ 2164075776 Joystick_5_Grip_X_Axis_Detent_Po 4564;
BA_ "SystemSignalLongSymbol" SG_ 2164075776 Joystick_5_Grip_X_Axis_Detent_Po "Joystick 5 Grip X-Axis Detent Position Status";
BA_ "SPN" SG_ 2164076032 Joystick_5_X_Axis_Neutral_Positi 4528;
BA_ "SystemSignalLongSymbol" SG_ 2164076032 Joystick_5_X_Axis_Neutral_Positi "Joystick 5 X-Axis Neutral Position Status";
BA_ "SPN" SG_ 2164076032 Joystick_5_X_Axis_Lever_Left_Neg 4529;
BA_ "SystemSignalLongSymbol" SG_ 2164076032 Joystick_5_X_Axis_Lever_Left_Neg "Joystick 5 X-Axis Lever Left Negative Position Status";
BA_ "SPN" SG_ 2164076032 Joystick_5_X_Axis_Lever_Right_Po 4530;
BA_ "SystemSignalLongSymbol" SG_ 2164076032 Joystick_5_X_Axis_Lever_Right_Po "Joystick 5 X-Axis Lever Right Positive Position Status";
BA_ "SPN" SG_ 2164076032 Joystick_5_X_Axis_Position 4531;
BA_ "SPN" SG_ 2164076032 Joystick_5_Y_Axis_Neutral_Positi 4532;
BA_ "SystemSignalLongSymbol" SG_ 2164076032 Joystick_5_Y_Axis_Neutral_Positi "Joystick 5 Y-Axis Neutral Position Status";
BA_ "SPN" SG_ 2164076032 Joystick_5_Y_Axis_Lever_Back_Neg 4533;
BA_ "SystemSignalLongSymbol" SG_ 2164076032 Joystick_5_Y_Axis_Lever_Back_Neg "Joystick 5 Y-Axis Lever Back Negative Position Status";
BA_ "SPN" SG_ 2164076032 Joystick_5_Y_Axis_Lever_Forward_ 4534;
BA_ "SystemSignalLongSymbol" SG_ 2164076032 Joystick_5_Y_Axis_Lever_Forward_ "Joystick 5 Y-Axis Lever Forward Positive Position Status";
BA_ "SPN" SG_ 2164076032 Joystick_5_Y_Axis_Position 4535;
BA_ "SPN" SG_ 2164076032 Joystick_5_Y_Axis_Detent_Positio 4536;
BA_ "SystemSignalLongSymbol" SG_ 2164076032 Joystick_5_Y_Axis_Detent_Positio "Joystick 5 Y-Axis Detent Position Status";
BA_ "SPN" SG_ 2164076032 Joystick_5_X_Axis_Detent_Positio 4537;
BA_ "SystemSignalLongSymbol" SG_ 2164076032 Joystick_5_X_Axis_Detent_Positio "Joystick 5 X-Axis Detent Position Status";
BA_ "SPN" SG_ 2164076032 Joystick_5_Button_4_Pressed_Stat 4538;
BA_ "SystemSignalLongSymbol" SG_ 2164076032 Joystick_5_Button_4_Pressed_Stat "Joystick 5 Button 4 Pressed Status";
BA_ "SPN" SG_ 2164076032 Joystick_5_Button_3_Pressed_Stat 4539;
BA_ "SystemSignalLongSymbol" SG_ 2164076032 Joystick_5_Button_3_Pressed_Stat "Joystick 5 Button 3 Pressed Status";
BA_ "SPN" SG_ 2164076032 Joystick_5_Button_2_Pressed_Stat 4540;
BA_ "SystemSignalLongSymbol" SG_ 2164076032 Joystick_5_Button_2_Pressed_Stat "Joystick 5 Button 2 Pressed Status";
BA_ "SPN" SG_ 2164076032 Joystick_5_Button_1_Pressed_Stat 4541;
BA_ "SystemSignalLongSymbol" SG_ 2164076032 Joystick_5_Button_1_Pressed_Stat "Joystick 5 Button 1 Pressed Status";
BA_ "SPN" SG_ 2164076032 Joystick_5_Button_8_Pressed_Stat 4542;
BA_ "SystemSignalLongSymbol" SG_ 2164076032 Joystick_5_Button_8_Pressed_Stat "Joystick 5 Button 8 Pressed Status";
BA_ "SPN" SG_ 2164076032 Joystick_5_Button_7_Pressed_Stat 4543;
BA_ "SystemSignalLongSymbol" SG_ 2164076032 Joystick_5_Button_7_Pressed_Stat "Joystick 5 Button 7 Pressed Status";
BA_ "SPN" SG_ 2164076032 Joystick_5_Button_6_Pressed_Stat 4544;
BA_ "SystemSignalLongSymbol" SG_ 2164076032 Joystick_5_Button_6_Pressed_Stat "Joystick 5 Button 6 Pressed Status";
BA_ "SPN" SG_ 2164076032 Joystick_5_Button_5_Pressed_Stat 4545;
BA_ "SystemSignalLongSymbol" SG_ 2164076032 Joystick_5_Button_5_Pressed_Stat "Joystick 5 Button 5 Pressed Status";
BA_ "SPN" SG_ 2164076032 Joystick_5_Button_12_Pressed_Sta 4546;
BA_ "SystemSignalLongSymbol" SG_ 2164076032 Joystick_5_Button_12_Pressed_Sta "Joystick 5 Button 12 Pressed Status";
BA_ "SPN" SG_ 2164076032 Joystick_5_Button_11_Pressed_Sta 4547;
BA_ "SystemSignalLongSymbol" SG_ 2164076032 Joystick_5_Button_11_Pressed_Sta "Joystick 5 Button 11 Pressed Status";
BA_ "SPN" SG_ 2164076032 Joystick_5_Button_10_Pressed_Sta 4548;
BA_ "SystemSignalLongSymbol" SG_ 2164076032 Joystick_5_Button_10_Pressed_Sta "Joystick 5 Button 10 Pressed Status";
BA_ "SPN" SG_ 2164076032 Joystick_5_Button_9_Pressed_Stat 4549;
BA_ "SystemSignalLongSymbol" SG_ 2164076032 Joystick_5_Button_9_Pressed_Stat "Joystick 5 Button 9 Pressed Status";
BA_ "SPN" SG_ 2164076288 Joystick_4_Grip_X_Axis_Neutral_P 4513;
BA_ "SystemSignalLongSymbol" SG_ 2164076288 Joystick_4_Grip_X_Axis_Neutral_P "Joystick 4 Grip X-Axis Neutral Position Status";
BA_ "SPN" SG_ 2164076288 Joystick_4_Grip_X_Axis_Lever_Lef 4514;
BA_ "SystemSignalLongSymbol" SG_ 2164076288 Joystick_4_Grip_X_Axis_Lever_Lef "Joystick 4 Grip X-Axis Lever Left Negative Position Status";
BA_ "SPN" SG_ 2164076288 Joystick_4_Grip_X_Axis_Lever_Rig 4515;
BA_ "SystemSignalLongSymbol" SG_ 2164076288 Joystick_4_Grip_X_Axis_Lever_Rig "Joystick 4 Grip X-Axis Lever Right Positive Position Status";
BA_ "SPN" SG_ 2164076288 Joystick_4_Grip_X_Axis_Position 4516;
BA_ "SPN" SG_ 2164076288 Joystick_4_Grip_Y_Axis_Neutral_P 4517;
BA_ "SystemSignalLongSymbol" SG_ 2164076288 Joystick_4_Grip_Y_Axis_Neutral_P "Joystick 4 Grip Y-Axis Neutral Position Status";
BA_ "SPN" SG_ 2164076288 Joystick_4_Grip_Y_Axis_Lever_Bac 4518;
BA_ "SystemSignalLongSymbol" SG_ 2164076288 Joystick_4_Grip_Y_Axis_Lever_Bac "Joystick 4 Grip Y-Axis Lever Back Negative Position Status";
BA_ "SPN" SG_ 2164076288 Joystick_4_Grip_Y_Axis_Lever_For 4519;
BA_ "SystemSignalLongSymbol" SG_ 2164076288 Joystick_4_Grip_Y_Axis_Lever_For "Joystick 4 Grip Y-Axis Lever Forward Positive Position Status";
BA_ "SPN" SG_ 2164076288 Joystick_4_Grip_Y_Axis_Position 4520;
BA_ "SPN" SG_ 2164076288 Joystick_4_Theta_Axis_Neutral_Po 4521;
BA_ "SystemSignalLongSymbol" SG_ 2164076288 Joystick_4_Theta_Axis_Neutral_Po "Joystick 4 Theta-Axis Neutral Position Status";
BA_ "SPN" SG_ 2164076288 Joystick_4_Theta_Axis_Counter_Cl 4522;
BA_ "SystemSignalLongSymbol" SG_ 2164076288 Joystick_4_Theta_Axis_Counter_Cl "Joystick 4 Theta-Axis Counter Clockwise Negative Position Status";
BA_ "SPN" SG_ 2164076288 Joystick_4_Theta_Axis_Clockwise_ 4523;
BA_ "SystemSignalLongSymbol" SG_ 2164076288 Joystick_4_Theta_Axis_Clockwise_ "Joystick 4 Theta-Axis Clockwise Positive Position Status";
BA_ "SPN" SG_ 2164076288 Joystick_4_Theta_Axis_Position 4524;
BA_ "SPN" SG_ 2164076288 Joystick_4_Theta_Axis_Detent_Pos 4525;
BA_ "SystemSignalLongSymbol" SG_ 2164076288 Joystick_4_Theta_Axis_Detent_Pos "Joystick 4 Theta-Axis Detent Position Status";
BA_ "SPN" SG_ 2164076288 Joystick_4_Grip_Y_Axis_Detent_Po 4526;
BA_ "SystemSignalLongSymbol" SG_ 2164076288 Joystick_4_Grip_Y_Axis_Detent_Po "Joystick 4 Grip Y-Axis Detent Position Status";
BA_ "SPN" SG_ 2164076288 Joystick_4_Grip_X_Axis_Detent_Po 4527;
BA_ "SystemSignalLongSymbol" SG_ 2164076288 Joystick_4_Grip_X_Axis_Detent_Po "Joystick 4 Grip X-Axis Detent Position Status";
BA_ "SPN" SG_ 2164076544 Joystick_4_X_Axis_Neutral_Positi 4491;
BA_ "SystemSignalLongSymbol" SG_ 2164076544 Joystick_4_X_Axis_Neutral_Positi "Joystick 4 X-Axis Neutral Position Status";
BA_ "SPN" SG_ 2164076544 Joystick_4_X_Axis_Lever_Left_Neg 4492;
BA_ "SystemSignalLongSymbol" SG_ 2164076544 Joystick_4_X_Axis_Lever_Left_Neg "Joystick 4 X-Axis Lever Left Negative Position Status";
BA_ "SPN" SG_ 2164076544 Joystick_4_X_Axis_Lever_Right_Po 4493;
BA_ "SystemSignalLongSymbol" SG_ 2164076544 Joystick_4_X_Axis_Lever_Right_Po "Joystick 4 X-Axis Lever Right Positive Position Status";
BA_ "SPN" SG_ 2164076544 Joystick_4_X_Axis_Position 4494;
BA_ "SPN" SG_ 2164076544 Joystick_4_Y_Axis_Neutral_Positi 4495;
BA_ "SystemSignalLongSymbol" SG_ 2164076544 Joystick_4_Y_Axis_Neutral_Positi "Joystick 4 Y-Axis Neutral Position Status";
BA_ "SPN" SG_ 2164076544 Joystick_4_Y_Axis_Lever_Back_Neg 4496;
BA_ "SystemSignalLongSymbol" SG_ 2164076544 Joystick_4_Y_Axis_Lever_Back_Neg "Joystick 4 Y-Axis Lever Back Negative Position Status";
BA_ "SPN" SG_ 2164076544 Joystick_4_Y_Axis_Lever_Forward_ 4497;
BA_ "SystemSignalLongSymbol" SG_ 2164076544 Joystick_4_Y_Axis_Lever_Forward_ "Joystick 4 Y-Axis Lever Forward Positive Position Status";
BA_ "SPN" SG_ 2164076544 Joystick_4_Y_Axis_Position 4498;
BA_ "SPN" SG_ 2164076544 Joystick_4_Y_Axis_Detent_Positio 4499;
BA_ "SystemSignalLongSymbol" SG_ 2164076544 Joystick_4_Y_Axis_Detent_Positio "Joystick 4 Y-Axis Detent Position Status";
BA_ "SPN" SG_ 2164076544 Joystick_4_X_Axis_Detent_Positio 4500;
BA_ "SystemSignalLongSymbol" SG_ 2164076544 Joystick_4_X_Axis_Detent_Positio "Joystick 4 X-Axis Detent Position Status";
BA_ "SPN" SG_ 2164076544 Joystick_4_Button_4_Pressed_Stat 4501;
BA_ "SystemSignalLongSymbol" SG_ 2164076544 Joystick_4_Button_4_Pressed_Stat "Joystick 4 Button 4 Pressed Status";
BA_ "SPN" SG_ 2164076544 Joystick_4_Button_3_Pressed_Stat 4502;
BA_ "SystemSignalLongSymbol" SG_ 2164076544 Joystick_4_Button_3_Pressed_Stat "Joystick 4 Button 3 Pressed Status";
BA_ "SPN" SG_ 2164076544 Joystick_4_Button_2_Pressed_Stat 4503;
BA_ "SystemSignalLongSymbol" SG_ 2164076544 Joystick_4_Button_2_Pressed_Stat "Joystick 4 Button 2 Pressed Status";
BA_ "SPN" SG_ 2164076544 Joystick_4_Button_1_Pressed_Stat 4504;
BA_ "SystemSignalLongSymbol" SG_ 2164076544 Joystick_4_Button_1_Pressed_Stat "Joystick 4 Button 1 Pressed Status";
BA_ "SPN" SG_ 2164076544 Joystick_4_Button_8_Pressed_Stat 4505;
BA_ "SystemSignalLongSymbol" SG_ 2164076544 Joystick_4_Button_8_Pressed_Stat "Joystick 4 Button 8 Pressed Status";
BA_ "SPN" SG_ 2164076544 Joystick_4_Button_7_Pressed_Stat 4506;
BA_ "SystemSignalLongSymbol" SG_ 2164076544 Joystick_4_Button_7_Pressed_Stat "Joystick 4 Button 7 Pressed Status";
BA_ "SPN" SG_ 2164076544 Joystick_4_Button_6_Pressed_Stat 4507;
BA_ "SystemSignalLongSymbol" SG_ 2164076544 Joystick_4_Button_6_Pressed_Stat "Joystick 4 Button 6 Pressed Status";
BA_ "SPN" SG_ 2164076544 Joystick_4_Button_5_Pressed_Stat 4508;
BA_ "SystemSignalLongSymbol" SG_ 2164076544 Joystick_4_Button_5_Pressed_Stat "Joystick 4 Button 5 Pressed Status";
BA_ "SPN" SG_ 2164076544 Joystick_4_Button_12_Pressed_Sta 4509;
BA_ "SystemSignalLongSymbol" SG_ 2164076544 Joystick_4_Button_12_Pressed_Sta "Joystick 4 Button 12 Pressed Status";
BA_ "SPN" SG_ 2164076544 Joystick_4_Button_11_Pressed_Sta 4510;
BA_ "SystemSignalLongSymbol" SG_ 2164076544 Joystick_4_Button_11_Pressed_Sta "Joystick 4 Button 11 Pressed Status";
BA_ "SPN" SG_ 2164076544 Joystick_4_Button_10_Pressed_Sta 4511;
BA_ "SystemSignalLongSymbol" SG_ 2164076544 Joystick_4_Button_10_Pressed_Sta "Joystick 4 Button 10 Pressed Status";
BA_ "SPN" SG_ 2164076544 Joystick_4_Button_9_Pressed_Stat 4512;
BA_ "SystemSignalLongSymbol" SG_ 2164076544 Joystick_4_Button_9_Pressed_Stat "Joystick 4 Button 9 Pressed Status";
BA_ "SPN" SG_ 2164076800 Joystick_1_Lamp_1_Command 4460;
BA_ "SPN" SG_ 2164076800 Joystick_1_Lamp_2_Command 4461;
BA_ "SPN" SG_ 2164076800 Joystick_1_Lamp_3_Command 4462;
BA_ "SPN" SG_ 2164076800 Joystick_1_Lamp_4_Command 4463;
BA_ "SPN" SG_ 2164076800 Joystick_1_Lamp_5_Command 4464;
BA_ "SPN" SG_ 2164076800 Joystick_1_Lamp_6_Command 4465;
BA_ "SPN" SG_ 2164076800 Joystick_1_Lamp_7_Command 4466;
BA_ "SPN" SG_ 2164076800 Joystick_1_Lamp_8_Command 4467;
BA_ "SPN" SG_ 2164076800 Joystick_1_Lamp_9_Command 4468;
BA_ "SPN" SG_ 2164076800 Joystick_1_Lamp_10_Command 4469;
BA_ "SPN" SG_ 2164076800 Joystick_2_Lamp_1_Command 4470;
BA_ "SPN" SG_ 2164076800 Joystick_2_Lamp_2_Command 4471;
BA_ "SPN" SG_ 2164076800 Joystick_2_Lamp_3_Command 4472;
BA_ "SPN" SG_ 2164076800 Joystick_2_Lamp_4_Command 4473;
BA_ "SPN" SG_ 2164076800 Joystick_2_Lamp_5_Command 4474;
BA_ "SPN" SG_ 2164076800 Joystick_2_Lamp_6_Command 4475;
BA_ "SPN" SG_ 2164076800 Joystick_2_Lamp_7_Command 4476;
BA_ "SPN" SG_ 2164076800 Joystick_2_Lamp_8_Command 4477;
BA_ "SPN" SG_ 2164076800 Joystick_2_Lamp_9_Command 4478;
BA_ "SPN" SG_ 2164076800 Joystick_2_Lamp_10_Command 4479;
BA_ "SPN" SG_ 2164076800 Joystick_3_Lamp_1_Command 4480;
BA_ "SPN" SG_ 2164076800 Joystick_3_Lamp_2_Command 4481;
BA_ "SPN" SG_ 2164076800 Joystick_3_Lamp_3_Command 4482;
BA_ "SPN" SG_ 2164076800 Joystick_3_Lamp_4_Command 4483;
BA_ "SPN" SG_ 2164076800 Joystick_3_Lamp_5_Command 4484;
BA_ "SPN" SG_ 2164076800 Joystick_3_Lamp_6_Command 4485;
BA_ "SPN" SG_ 2164076800 Joystick_3_Lamp_7_Command 4486;
BA_ "SPN" SG_ 2164076800 Joystick_3_Lamp_8_Command 4487;
BA_ "SPN" SG_ 2164076800 Joystick_3_Lamp_9_Command 4488;
BA_ "SPN" SG_ 2164076800 Joystick_3_Lamp_10_Command 4489;
BA_ "SPN" SG_ 2164077312 Aftertreatment_2_SCR_Catalyst_Re0 4440;
BA_ "SystemSignalLongSymbol" SG_ 2164077312 Aftertreatment_2_SCR_Catalyst_Re0 "Aftertreatment 2 SCR Catalyst Reagent Pump Motor Speed (feedback on pump speed)";
BA_ "SPN" SG_ 2164077312 Aftertreatment_2_SCR_Catalyst_Re1 4441;
BA_ "SystemSignalLongSymbol" SG_ 2164077312 Aftertreatment_2_SCR_Catalyst_Re1 "Aftertreatment 2 SCR Catalyst Reagent Pump Drive Percentage (Command to pump)";
BA_ "SPN" SG_ 2164077312 Aftertreatment_2_SCR_Catalyst_Re2 4442;
BA_ "SystemSignalLongSymbol" SG_ 2164077312 Aftertreatment_2_SCR_Catalyst_Re2 "Aftertreatment 2 SCR Catalyst Reagent Return Valve (Directional command for return)";
BA_ "SPN" SG_ 2164077568 Aftertreatment_2_SCR_Catalyst_Re0 4433;
BA_ "SystemSignalLongSymbol" SG_ 2164077568 Aftertreatment_2_SCR_Catalyst_Re0 "Aftertreatment 2 SCR Catalyst Reagent Tank 2 Level";
BA_ "SPN" SG_ 2164077568 Aftertreatment_2_SCR_Catalyst_Re1 4434;
BA_ "SystemSignalLongSymbol" SG_ 2164077568 Aftertreatment_2_SCR_Catalyst_Re1 "Aftertreatment 2 SCR Catalyst Reagent Tank 2 Temperature";
BA_ "SPN" SG_ 2164077568 Aftertreatment_2_SCR_Catalyst_Re2 4435;
BA_ "SystemSignalLongSymbol" SG_ 2164077568 Aftertreatment_2_SCR_Catalyst_Re2 "Aftertreatment 2 SCR Catalyst Reagent Tank 2 Level 2";
BA_ "SPN" SG_ 2164077568 Aftertreatment_2_SCR_Catalyst_Re3 4436;
BA_ "SystemSignalLongSymbol" SG_ 2164077568 Aftertreatment_2_SCR_Catalyst_Re3 "Aftertreatment 2 SCR Catalyst Reagent Tank 2 Level Preliminary FMI";
BA_ "SPN" SG_ 2164077568 Aftertreatment_2_SCR_Reagent_Tan 4437;
BA_ "SystemSignalLongSymbol" SG_ 2164077568 Aftertreatment_2_SCR_Reagent_Tan "Aftertreatment 2 SCR Reagent Tank 2 Temperature Preliminary FMI";
BA_ "SPN" SG_ 2164077568 Aftertreatment_2_SCR_Catalyst_Re4 4438;
BA_ "SystemSignalLongSymbol" SG_ 2164077568 Aftertreatment_2_SCR_Catalyst_Re4 "Aftertreatment 2 SCR Catalyst Reagent Tank 2 Heater (light-off)";
BA_ "SPN" SG_ 2164077568 Aftertreatment_2_SCR_Catalyst_Re5 4439;
BA_ "SystemSignalLongSymbol" SG_ 2164077568 Aftertreatment_2_SCR_Catalyst_Re5 "Aftertreatment 2 SCR Catalyst Reagent Tank 2 Heater Preliminary FMI";
BA_ "SPN" SG_ 2164077824 Aftertreatment_2_SCR_Catalyst_Ta0 4426;
BA_ "SystemSignalLongSymbol" SG_ 2164077824 Aftertreatment_2_SCR_Catalyst_Ta0 "Aftertreatment 2 SCR Catalyst Tank Level";
BA_ "SPN" SG_ 2164077824 Aftertreatment_2_SCR_Catalyst_Ta1 4427;
BA_ "SystemSignalLongSymbol" SG_ 2164077824 Aftertreatment_2_SCR_Catalyst_Ta1 "Aftertreatment 2 SCR Catalyst Tank Temperature";
BA_ "SPN" SG_ 2164077824 Aftertreatment_2_SCR_Catalyst_Ta2 4428;
BA_ "SystemSignalLongSymbol" SG_ 2164077824 Aftertreatment_2_SCR_Catalyst_Ta2 "Aftertreatment 2 SCR Catalyst Tank Level 2";
BA_ "SPN" SG_ 2164077824 Aftertreatment_2_SCR_Catalyst_Ta3 4429;
BA_ "SystemSignalLongSymbol" SG_ 2164077824 Aftertreatment_2_SCR_Catalyst_Ta3 "Aftertreatment 2 SCR Catalyst Tank Level Preliminary FMI";
BA_ "SPN" SG_ 2164077824 Aftertreatment_2_SCR_Catalyst_Re0 4430;
BA_ "SystemSignalLongSymbol" SG_ 2164077824 Aftertreatment_2_SCR_Catalyst_Re0 "Aftertreatment 2 SCR Catalyst Reagent Tank 1 Temperature Preliminary FMI";
BA_ "SPN" SG_ 2164077824 Aftertreatment_2_SCR_Catalyst_Re1 4432;
BA_ "SystemSignalLongSymbol" SG_ 2164077824 Aftertreatment_2_SCR_Catalyst_Re1 "Aftertreatment 2 SCR Catalyst Reagent Tank 1 Heater Preliminary FMI";
BA_ "SPN" SG_ 2164078080 Aftertreatment_2_SCR_Catalyst_Re0 4420;
BA_ "SystemSignalLongSymbol" SG_ 2164078080 Aftertreatment_2_SCR_Catalyst_Re0 "Aftertreatment 2 SCR Catalyst Reagent Temperature 2";
BA_ "SPN" SG_ 2164078080 Aftertreatment_2_SCR_Catalyst_Re1 4421;
BA_ "SystemSignalLongSymbol" SG_ 2164078080 Aftertreatment_2_SCR_Catalyst_Re1 "Aftertreatment 2 SCR Catalyst Reagent Concentration";
BA_ "SPN" SG_ 2164078080 Aftertreatment_2_SCR_Catalyst_Re2 4422;
BA_ "SystemSignalLongSymbol" SG_ 2164078080 Aftertreatment_2_SCR_Catalyst_Re2 "Aftertreatment 2 SCR Catalyst Reagent Conductivity";
BA_ "SPN" SG_ 2164078080 Aftertreatment_2_SCR_Catalyst_Re3 4423;
BA_ "SystemSignalLongSymbol" SG_ 2164078080 Aftertreatment_2_SCR_Catalyst_Re3 "Aftertreatment 2 SCR Catalyst Reagent Temperature 2 Preliminary FMI";
BA_ "SPN" SG_ 2164078080 Aftertreatment_2_SCR_Catalyst_Re4 4424;
BA_ "SystemSignalLongSymbol" SG_ 2164078080 Aftertreatment_2_SCR_Catalyst_Re4 "Aftertreatment 2 SCR Catalyst Reagent Properties Preliminary FMI";
BA_ "SPN" SG_ 2164078080 Aftertreatment_2_SCR_Catalyst_Re5 4425;
BA_ "SystemSignalLongSymbol" SG_ 2164078080 Aftertreatment_2_SCR_Catalyst_Re5 "Aftertreatment 2 SCR Catalyst Reagent Type";
BA_ "SPN" SG_ 2164078336 Aftertreatment_2_SCR_Average_Cat 4417;
BA_ "SystemSignalLongSymbol" SG_ 2164078336 Aftertreatment_2_SCR_Average_Cat "Aftertreatment 2 SCR Average Catalyst Reagent Consumption (15 hr avg)";
BA_ "SPN" SG_ 2164078336 Aftertreatment_2_SCR_Commanded_C 4418;
BA_ "SystemSignalLongSymbol" SG_ 2164078336 Aftertreatment_2_SCR_Commanded_C "Aftertreatment 2 SCR Commanded Catalyst Reagent Consumption (15 hr avg)";
BA_ "SPN" SG_ 2164078336 Aftertreatment_2_SCR_Catalyst_Co 4419;
BA_ "SystemSignalLongSymbol" SG_ 2164078336 Aftertreatment_2_SCR_Catalyst_Co "Aftertreatment 2 SCR Catalyst Conversion Efficiency";
BA_ "SPN" SG_ 2164078592 Aftertreatment_2_SCR_Catalyst_In0 4413;
BA_ "SystemSignalLongSymbol" SG_ 2164078592 Aftertreatment_2_SCR_Catalyst_In0 "Aftertreatment 2 SCR Catalyst Intake Gas Temperature";
BA_ "SPN" SG_ 2164078592 Aftertreatment_2_SCR_Catalyst_In1 4414;
BA_ "SystemSignalLongSymbol" SG_ 2164078592 Aftertreatment_2_SCR_Catalyst_In1 "Aftertreatment 2 SCR Catalyst Intake Gas Temperature Preliminary FMI";
BA_ "SPN" SG_ 2164078592 Aftertreatment_2_SCR_Catalyst_Ou0 4415;
BA_ "SystemSignalLongSymbol" SG_ 2164078592 Aftertreatment_2_SCR_Catalyst_Ou0 "Aftertreatment 2 SCR Catalyst Outlet Gas Temperature";
BA_ "SPN" SG_ 2164078592 Aftertreatment_2_SCR_Catalyst_Ou1 4416;
BA_ "SystemSignalLongSymbol" SG_ 2164078592 Aftertreatment_2_SCR_Catalyst_Ou1 "Aftertreatment 2 SCR Catalyst Outlet Gas Temperature Preliminary FMI";
BA_ "SPN" SG_ 2164078848 Aftertreatment_2_SCR_Catalyst_Ex0 4411;
BA_ "SystemSignalLongSymbol" SG_ 2164078848 Aftertreatment_2_SCR_Catalyst_Ex0 "Aftertreatment 2 SCR Catalyst Exhaust Gas Differential Pressure";
BA_ "SPN" SG_ 2164078848 Aftertreatment_2_SCR_Catalyst_Ex1 4412;
BA_ "SystemSignalLongSymbol" SG_ 2164078848 Aftertreatment_2_SCR_Catalyst_Ex1 "Aftertreatment 2 SCR Catalyst Exhaust Gas Differential Pressure Preliminary FMI";
BA_ "SPN" SG_ 2164079104 Aftertreatment_2_SCR_Doser_Fault 4405;
BA_ "SystemSignalLongSymbol" SG_ 2164079104 Aftertreatment_2_SCR_Doser_Fault "Aftertreatment 2 SCR Doser Fault Suppression Request";
BA_ "SPN" SG_ 2164079104 Aftertreatment_2_SCR_Doser_Heati 4406;
BA_ "SystemSignalLongSymbol" SG_ 2164079104 Aftertreatment_2_SCR_Doser_Heati "Aftertreatment 2 SCR Doser Heating Mode Request";
BA_ "SPN" SG_ 2164079104 Aftertreatment_2_SCR_Catalyst_Re0 4407;
BA_ "SystemSignalLongSymbol" SG_ 2164079104 Aftertreatment_2_SCR_Catalyst_Re0 "Aftertreatment 2 SCR Catalyst Reagent Line Heater 1 (request)";
BA_ "SPN" SG_ 2164079104 Aftertreatment_2_SCR_Catalyst_Re1 4408;
BA_ "SystemSignalLongSymbol" SG_ 2164079104 Aftertreatment_2_SCR_Catalyst_Re1 "Aftertreatment 2 SCR Catalyst Reagent Line Heater 2 (request)";
BA_ "SPN" SG_ 2164079104 Aftertreatment_2_SCR_Catalyst_Re2 4409;
BA_ "SystemSignalLongSymbol" SG_ 2164079104 Aftertreatment_2_SCR_Catalyst_Re2 "Aftertreatment 2 SCR Catalyst Reagent Line Heater 3 (request)";
BA_ "SPN" SG_ 2164079104 Aftertreatment_2_SCR_Catalyst_Re3 4410;
BA_ "SystemSignalLongSymbol" SG_ 2164079104 Aftertreatment_2_SCR_Catalyst_Re3 "Aftertreatment 2 SCR Catalyst Reagent Line Heater 4 (request)";
